VERSION "dbc-export 1 2026.26.6.5"

NS_ :

BS_:

BU_: ADSP APB APP APS APSB BB BMS CC CMP CMPD CP DAS DI DIF DIR DPB EPAS3P EPAS3S EPASTP EPASTS EPBL EPBR ESP EVSE FC GTW HCML HCMR HVP IBST ICR IDB LS OCS1P PARK PCS PCS2 PM PMF PMR PNCD PTC RADC RCM RCM2 RCM3 RCU SCCM SCM SCS SDCR TAS TCU TCU2 TPMS TRCM UI UIS UMC USM V2G VC VCBATT VCBATT0 VCBATT1 VCBATT2 VCCC VCFRONT VCFRONT1 VCFRONT2 VCLEFT VCRIGHT VCSEAT2L VCSEAT2R VCSEC VEH

BO_ 1328 VCSEC_alertLog: 8 VCSEC
 SG_ VCSEC_alertID M : 0|10@1+ (1,0) [0|1023] "" Vector__XXX
 SG_ VCSEC_alertState : 15|1@1+ (1,0) [0|1] "" Vector__XXX
 SG_ VCSEC_a001_InternalWatchdog m1 : 16|1@1+ (1,0) [0|1] "" Vector__XXX
 SG_ VCSEC_a010_UnderVoltageDetected m10 : 16|1@1+ (1,0) [0|1] "" Vector__XXX
 SG_ VCSEC_a010_UnderVoltageTimeout m10 : 17|1@1+ (1,0) [0|1] "" Vector__XXX
 SG_ VCSEC_a015_NVMMMemOverflow m15 : 16|1@1+ (1,0) [0|1] "" Vector__XXX
 SG_ VCSEC_a015_NVMMFilesystemError m15 : 17|1@1+ (1,0) [0|1] "" Vector__XXX
 SG_ VCSEC_a015_NVMMRecordIDError m15 : 18|1@1+ (1,0) [0|1] "" Vector__XXX
 SG_ VCSEC_a057_VEH_cpControl m57 : 16|1@1+ (1,0) [0|1] "" Vector__XXX
 SG_ VCSEC_a059_voltageDrop m59 : 16|12@1+ (0.005443676,0) [0|22.29185322] "" Vector__XXX
 SG_ VCSEC_a059_resistanceEstimate m59 : 28|12@1+ (0.00244,0) [0|9.9918] "" Vector__XXX
 SG_ VCSEC_a059_current m59 : 40|12@1+ (0.05,0) [0|204.75] "" Vector__XXX
 SG_ VCSEC_a063_switchChannel m63 : 16|8@1+ (1,0) [0|255] "" Vector__XXX
 SG_ VCSEC_a063_switchType m63 : 24|8@1+ (1,0) [0|255] "" Vector__XXX
 SG_ VCSEC_a063_ADCVoltage m63 : 32|8@1+ (0.025,0) [0|6.375] "" Vector__XXX
 SG_ VCSEC_a063_disconnected m63 : 40|1@1+ (1,0) [0|1] "" Vector__XXX
 SG_ VCSEC_a063_indeterminate m63 : 41|1@1+ (1,0) [0|1] "" Vector__XXX
 SG_ VCSEC_a063_stuckActive m63 : 42|1@1+ (1,0) [0|1] "" Vector__XXX
 SG_ VCSEC_a063_faulted m63 : 43|1@1+ (1,0) [0|1] "" Vector__XXX
 SG_ VCSEC_a082_RIPC_epbPrivateState m82 : 16|1@1+ (1,0) [0|1] "" Vector__XXX
 SG_ VCSEC_a082_RIPC_remoteHSD m82 : 17|1@1+ (1,0) [0|1] "" Vector__XXX
 SG_ VCSEC_a082_RIPC_railStatus m82 : 18|1@1+ (1,0) [0|1] "" Vector__XXX
 SG_ VCSEC_a082_RIPC_remoteMux m82 : 19|1@1+ (1,0) [0|1] "" Vector__XXX
 SG_ VCSEC_a083_LIPC_epbPrivateState m83 : 16|1@1+ (1,0) [0|1] "" Vector__XXX
 SG_ VCSEC_a083_LIPC_remoteHSD m83 : 17|1@1+ (1,0) [0|1] "" Vector__XXX
 SG_ VCSEC_a083_LIPC_railStatus m83 : 18|1@1+ (1,0) [0|1] "" Vector__XXX
 SG_ VCSEC_a083_LIPC_HSDFaults m83 : 19|1@1+ (1,0) [0|1] "" Vector__XXX
 SG_ VCSEC_a084_CH_StatusC m84 : 16|1@1+ (1,0) [0|1] "" Vector__XXX
 SG_ VCSEC_a085_PARTY_buttonStatus m85 : 16|1@1+ (1,0) [0|1] "" Vector__XXX
 SG_ VCSEC_a086_VEH_LVBMS_statusHigh m86 : 16|1@1+ (1,0) [0|1] "" Vector__XXX
 SG_ VCSEC_a086_VEH_LVBMS_statusLow m86 : 17|1@1+ (1,0) [0|1] "" Vector__XXX
 SG_ VCSEC_a086_VEH_status m86 : 18|1@1+ (1,0) [0|1] "" Vector__XXX
 SG_ VCSEC_a086_VEH_12VBatteryStatus m86 : 19|1@1+ (1,0) [0|1] "" Vector__XXX
 SG_ VCSEC_a086_VEH_LVPowerState m86 : 20|1@1+ (1,0) [0|1] "" Vector__XXX
 SG_ VCSEC_a086_VEH_lightStatus m86 : 21|1@1+ (1,0) [0|1] "" Vector__XXX
 SG_ VCSEC_a086_VEH_systemStatus m86 : 22|1@1+ (1,0) [0|1] "" Vector__XXX
 SG_ VCSEC_a086_VEH_thermalStatus m86 : 23|1@1+ (1,0) [0|1] "" Vector__XXX
 SG_ VCSEC_a086_VEH_vehNm m86 : 24|1@1+ (1,0) [0|1] "" Vector__XXX
 SG_ VCSEC_a087_VEH_temperature m87 : 16|1@1+ (1,0) [0|1] "" Vector__XXX
 SG_ VCSEC_a087_VEH_thermalControl m87 : 17|1@1+ (1,0) [0|1] "" Vector__XXX
 SG_ VCSEC_a087_VEH_torque m87 : 18|1@1+ (1,0) [0|1] "" Vector__XXX
 SG_ VCSEC_a087_VEH_status m87 : 19|1@1+ (1,0) [0|1] "" Vector__XXX
 SG_ VCSEC_a087_PARTY_torque m87 : 20|1@1+ (1,0) [0|1] "" Vector__XXX
 SG_ VCSEC_a087_PARTY_status m87 : 21|1@1+ (1,0) [0|1] "" Vector__XXX
 SG_ VCSEC_a087_PARTY_temperature m87 : 22|1@1+ (1,0) [0|1] "" Vector__XXX
 SG_ VCSEC_a087_PARTY_thermalControl m87 : 23|1@1+ (1,0) [0|1] "" Vector__XXX
 SG_ VCSEC_a087_VEH_motorStatus m87 : 24|1@1+ (1,0) [0|1] "" Vector__XXX
 SG_ VCSEC_a088_VEH_temperature m88 : 16|1@1+ (1,0) [0|1] "" Vector__XXX
 SG_ VCSEC_a088_VEH_thermalControl m88 : 17|1@1+ (1,0) [0|1] "" Vector__XXX
 SG_ VCSEC_a088_VEH_torque m88 : 18|1@1+ (1,0) [0|1] "" Vector__XXX
 SG_ VCSEC_a088_VEH_status m88 : 19|1@1+ (1,0) [0|1] "" Vector__XXX
 SG_ VCSEC_a088_PARTY_torque m88 : 20|1@1+ (1,0) [0|1] "" Vector__XXX
 SG_ VCSEC_a088_PARTY_status m88 : 21|1@1+ (1,0) [0|1] "" Vector__XXX
 SG_ VCSEC_a088_PARTY_temperature m88 : 22|1@1+ (1,0) [0|1] "" Vector__XXX
 SG_ VCSEC_a088_PARTY_thermalControl m88 : 23|1@1+ (1,0) [0|1] "" Vector__XXX
 SG_ VCSEC_a088_VEH_motorStatus m88 : 24|1@1+ (1,0) [0|1] "" Vector__XXX
 SG_ VCSEC_a089_PARTY_party1 m89 : 16|1@1+ (1,0) [0|1] "" Vector__XXX
 SG_ VCSEC_a089_PARTY_status m89 : 17|1@1+ (1,0) [0|1] "" Vector__XXX
 SG_ VCSEC_a089_VEH_status m89 : 18|1@1+ (1,0) [0|1] "" Vector__XXX
 SG_ VCSEC_a089_BDY_party1 m89 : 19|1@1+ (1,0) [0|1] "" Vector__XXX
 SG_ VCSEC_a089_BDY_status m89 : 20|1@1+ (1,0) [0|1] "" Vector__XXX
 SG_ VCSEC_a089_CH_status m89 : 21|1@1+ (1,0) [0|1] "" Vector__XXX
 SG_ VCSEC_a089_CH_party1 m89 : 22|1@1+ (1,0) [0|1] "" Vector__XXX
 SG_ VCSEC_a089_CH_party3 m89 : 23|1@1+ (1,0) [0|1] "" Vector__XXX
 SG_ VCSEC_a089_VEH_party1 m89 : 24|1@1+ (1,0) [0|1] "" Vector__XXX
 SG_ VCSEC_a089_VEH_party3 m89 : 25|1@1+ (1,0) [0|1] "" Vector__XXX
 SG_ VCSEC_a091_VEH_faultsAndExtras m91 : 16|1@1+ (1,0) [0|1] "" Vector__XXX
 SG_ VCSEC_a091_VEH_info m91 : 17|1@1+ (1,0) [0|1] "" Vector__XXX
 SG_ VCSEC_a091_VEH_state m91 : 18|1@1+ (1,0) [0|1] "" Vector__XXX
 SG_ VCSEC_a092_VEH_restraintStatus m92 : 16|1@1+ (1,0) [0|1] "" Vector__XXX
 SG_ VCSEC_a092_VEH_switchStatus m92 : 17|1@1+ (1,0) [0|1] "" Vector__XXX
 SG_ VCSEC_a092_VEH_seatStatus2 m92 : 18|1@1+ (1,0) [0|1] "" Vector__XXX
 SG_ VCSEC_a092_VEH_vehNm m92 : 19|1@1+ (1,0) [0|1] "" Vector__XXX
 SG_ VCSEC_a093_VEH_restraintStatus m93 : 16|1@1+ (1,0) [0|1] "" Vector__XXX
 SG_ VCSEC_a093_VEH_switchStatus m93 : 17|1@1+ (1,0) [0|1] "" Vector__XXX
 SG_ VCSEC_a093_VEH_seatStatus2 m93 : 18|1@1+ (1,0) [0|1] "" Vector__XXX
 SG_ VCSEC_a093_VEH_vehNm m93 : 19|1@1+ (1,0) [0|1] "" Vector__XXX
 SG_ VCSEC_a094_VEH_sysStatus m94 : 16|1@1+ (1,0) [0|1] "" Vector__XXX
 SG_ VCSEC_a094_PARTY_sysStatus m94 : 17|1@1+ (1,0) [0|1] "" Vector__XXX
 SG_ VCSEC_a094_CH_sysStatus m94 : 18|1@1+ (1,0) [0|1] "" Vector__XXX
 SG_ VCSEC_a095_PT_ptNm m95 : 16|1@1+ (1,0) [0|1] "" Vector__XXX
 SG_ VCSEC_a095_PT_status m95 : 17|1@1+ (1,0) [0|1] "" Vector__XXX
 SG_ VCSEC_a096_VEH_status m96 : 16|1@1+ (1,0) [0|1] "" Vector__XXX
 SG_ VCSEC_a096_CH_status m96 : 17|1@1+ (1,0) [0|1] "" Vector__XXX
 SG_ VCSEC_a097_VEH_HVStatus m97 : 16|1@1+ (1,0) [0|1] "" Vector__XXX
 SG_ VCSEC_a097_VEH_state m97 : 17|1@1+ (1,0) [0|1] "" Vector__XXX
 SG_ VCSEC_a098_CH_torque m98 : 16|1@1+ (1,0) [0|1] "" Vector__XXX
 SG_ VCSEC_a098_VEH_hvStatus m98 : 17|1@1+ (1,0) [0|1] "" Vector__XXX
 SG_ VCSEC_a098_VEH_status m98 : 18|1@1+ (1,0) [0|1] "" Vector__XXX
 SG_ VCSEC_a098_VEH_thermalControl m98 : 19|1@1+ (1,0) [0|1] "" Vector__XXX
 SG_ VCSEC_a098_VEH_temperature m98 : 20|1@1+ (1,0) [0|1] "" Vector__XXX
 SG_ VCSEC_a098_VEH_torque m98 : 21|1@1+ (1,0) [0|1] "" Vector__XXX
 SG_ VCSEC_a098_PARTY_status m98 : 22|1@1+ (1,0) [0|1] "" Vector__XXX
 SG_ VCSEC_a098_PARTY_temperature m98 : 23|1@1+ (1,0) [0|1] "" Vector__XXX
 SG_ VCSEC_a098_PARTY_thermalControl m98 : 24|1@1+ (1,0) [0|1] "" Vector__XXX
 SG_ VCSEC_a098_PARTY_torque m98 : 25|1@1+ (1,0) [0|1] "" Vector__XXX
 SG_ VCSEC_a098_PT_thermalControl m98 : 26|1@1+ (1,0) [0|1] "" Vector__XXX
 SG_ VCSEC_a098_PT_temperature m98 : 27|1@1+ (1,0) [0|1] "" Vector__XXX
 SG_ VCSEC_a098_PARTY_motorStatus m98 : 28|1@1+ (1,0) [0|1] "" Vector__XXX
 SG_ VCSEC_a098_VEH_motorStatus m98 : 29|1@1+ (1,0) [0|1] "" Vector__XXX
 SG_ VCSEC_a099_VEH_oocStatus m99 : 16|1@1+ (1,0) [0|1] "" Vector__XXX
 SG_ VCSEC_a100_VEH m100 : 16|1@1+ (1,0) [0|1] "" Vector__XXX
 SG_ VCSEC_a100_PARTY m100 : 17|1@1+ (1,0) [0|1] "" Vector__XXX
 SG_ VCSEC_a100_PT m100 : 18|1@1+ (1,0) [0|1] "" Vector__XXX
 SG_ VCSEC_a100_CH m100 : 19|1@1+ (1,0) [0|1] "" Vector__XXX
 SG_ VCSEC_a100_OBD m100 : 20|1@1+ (1,0) [0|1] "" Vector__XXX
 SG_ VCSEC_a101_VEH_state m101 : 16|1@1+ (1,0) [0|1] "" Vector__XXX
 SG_ VCSEC_a101_PARTY_locState m101 : 17|1@1+ (1,0) [0|1] "" Vector__XXX
 SG_ VCSEC_a101_LIPC_externalWatchdog m101 : 18|1@1+ (1,0) [0|1] "" Vector__XXX
 SG_ VCSEC_a101_VEH_locState m101 : 19|1@1+ (1,0) [0|1] "" Vector__XXX
 SG_ VCSEC_a101_BDY_locState m101 : 20|1@1+ (1,0) [0|1] "" Vector__XXX
 SG_ VCSEC_a102_VEH_faultsAndExtras m102 : 16|1@1+ (1,0) [0|1] "" Vector__XXX
 SG_ VCSEC_a102_VEH_feedbackStatus m102 : 17|1@1+ (1,0) [0|1] "" Vector__XXX
 SG_ VCSEC_a102_VEH_sensorStatus m102 : 18|1@1+ (1,0) [0|1] "" Vector__XXX
 SG_ VCSEC_a102_VEH_rods m102 : 19|1@1+ (1,0) [0|1] "" Vector__XXX
 SG_ VCSEC_a103_VEH_hvsNm m103 : 16|1@1+ (1,0) [0|1] "" Vector__XXX
 SG_ VCSEC_a103_VEH_vehNm m103 : 17|1@1+ (1,0) [0|1] "" Vector__XXX
 SG_ VCSEC_a103_VEH_status m103 : 18|1@1+ (1,0) [0|1] "" Vector__XXX
 SG_ VCSEC_a103_PT_ptNm m103 : 19|1@1+ (1,0) [0|1] "" Vector__XXX
 SG_ VCSEC_a103_PT_status m103 : 20|1@1+ (1,0) [0|1] "" Vector__XXX
 SG_ VCSEC_a103_VEH_evseStatus m103 : 21|1@1+ (1,0) [0|1] "" Vector__XXX
 SG_ VCSEC_a105_VEH_states m105 : 16|1@1+ (1,0) [0|1] "" Vector__XXX
 SG_ VCSEC_a105_VEH_chNm m105 : 17|1@1+ (1,0) [0|1] "" Vector__XXX
 SG_ VCSEC_a105_VEH_dampingStates m105 : 18|1@1+ (1,0) [0|1] "" Vector__XXX
 SG_ VCSEC_a106_VEH_dcdcStatus m106 : 16|1@1+ (1,0) [0|1] "" Vector__XXX
 SG_ VCSEC_a106_VEH_thermalControl m106 : 17|1@1+ (1,0) [0|1] "" Vector__XXX
 SG_ VCSEC_a106_VEH_dcdcRailStatus m106 : 18|1@1+ (1,0) [0|1] "" Vector__XXX
 SG_ VCSEC_a106_CH_dcdcRailStatus m106 : 19|1@1+ (1,0) [0|1] "" Vector__XXX
 SG_ VCSEC_a106_CH_alertMatrix m106 : 20|1@1+ (1,0) [0|1] "" Vector__XXX
 SG_ VCSEC_a107_VEH_hvsNm m107 : 16|1@1+ (1,0) [0|1] "" Vector__XXX
 SG_ VCSEC_a107_VEH_vehNm m107 : 17|1@1+ (1,0) [0|1] "" Vector__XXX
 SG_ VCSEC_a107_VEH_status m107 : 18|1@1+ (1,0) [0|1] "" Vector__XXX
 SG_ VCSEC_a107_VEH_thermalStatus m107 : 19|1@1+ (1,0) [0|1] "" Vector__XXX
 SG_ VCSEC_a107_VEH_bmbMinMax m107 : 20|1@1+ (1,0) [0|1] "" Vector__XXX
 SG_ VCSEC_a107_VEH_powerAvailable m107 : 21|1@1+ (1,0) [0|1] "" Vector__XXX
 SG_ VCSEC_a107_PT_ptNm m107 : 22|1@1+ (1,0) [0|1] "" Vector__XXX
 SG_ VCSEC_a107_PT_status m107 : 23|1@1+ (1,0) [0|1] "" Vector__XXX
 SG_ VCSEC_a107_PT_thermalStatus m107 : 24|1@1+ (1,0) [0|1] "" Vector__XXX
 SG_ VCSEC_a107_PT_socStatus m107 : 25|1@1+ (1,0) [0|1] "" Vector__XXX
 SG_ VCSEC_a107_VEH_socStatus m107 : 26|1@1+ (1,0) [0|1] "" Vector__XXX
 SG_ VCSEC_a107_VEH_packConfig m107 : 27|1@1+ (1,0) [0|1] "" Vector__XXX
 SG_ VCSEC_a107_VEH_energyStatus m107 : 28|1@1+ (1,0) [0|1] "" Vector__XXX
 SG_ VCSEC_a107_VEH_chargeInfo m107 : 29|1@1+ (1,0) [0|1] "" Vector__XXX
 SG_ VCSEC_a108_VEH_hvStatus m108 : 16|1@1+ (1,0) [0|1] "" Vector__XXX
 SG_ VCSEC_a108_VEH_temperature m108 : 17|1@1+ (1,0) [0|1] "" Vector__XXX
 SG_ VCSEC_a108_VEH_thermalControl m108 : 18|1@1+ (1,0) [0|1] "" Vector__XXX
 SG_ VCSEC_a108_VEH_torque m108 : 19|1@1+ (1,0) [0|1] "" Vector__XXX
 SG_ VCSEC_a108_VEH_status m108 : 20|1@1+ (1,0) [0|1] "" Vector__XXX
 SG_ VCSEC_a108_PARTY_torque m108 : 21|1@1+ (1,0) [0|1] "" Vector__XXX
 SG_ VCSEC_a108_PARTY_status m108 : 22|1@1+ (1,0) [0|1] "" Vector__XXX
 SG_ VCSEC_a108_PARTY_temperature m108 : 23|1@1+ (1,0) [0|1] "" Vector__XXX
 SG_ VCSEC_a108_PARTY_thermalControl m108 : 24|1@1+ (1,0) [0|1] "" Vector__XXX
 SG_ VCSEC_a108_PT_temperature m108 : 25|1@1+ (1,0) [0|1] "" Vector__XXX
 SG_ VCSEC_a108_PT_thermalControl m108 : 26|1@1+ (1,0) [0|1] "" Vector__XXX
 SG_ VCSEC_a108_PARTY_motorStatus m108 : 27|1@1+ (1,0) [0|1] "" Vector__XXX
 SG_ VCSEC_a108_VEH_motorStatus m108 : 28|1@1+ (1,0) [0|1] "" Vector__XXX
 SG_ VCSEC_a108_CH_torque m108 : 29|1@1+ (1,0) [0|1] "" Vector__XXX
 SG_ VCSEC_a110_VEH_carState m110 : 16|1@1+ (1,0) [0|1] "" Vector__XXX
 SG_ VCSEC_a110_VEH_carConfig m110 : 17|1@1+ (1,0) [0|1] "" Vector__XXX
 SG_ VCSEC_a110_VEH_time m110 : 18|1@1+ (1,0) [0|1] "" Vector__XXX
 SG_ VCSEC_a110_VEH_updateStatus m110 : 19|1@1+ (1,0) [0|1] "" Vector__XXX
 SG_ VCSEC_a110_VEH_vehNm m110 : 20|1@1+ (1,0) [0|1] "" Vector__XXX
 SG_ VCSEC_a110_VEH_mismatchFault m110 : 21|1@1+ (1,0) [0|1] "" Vector__XXX
 SG_ VCSEC_a110_VEH_vin m110 : 22|1@1+ (1,0) [0|1] "" Vector__XXX
 SG_ VCSEC_a110_VEH_bmpDebug m110 : 23|1@1+ (1,0) [0|1] "" Vector__XXX
 SG_ VCSEC_a110_VEH_gearControl m110 : 24|1@1+ (1,0) [0|1] "" Vector__XXX
 SG_ VCSEC_a110_VEH_canLogAvailabilit m110 : 25|1@1+ (1,0) [0|1] "" Vector__XXX
 SG_ VCSEC_a110_CH_airbagCutoffStatus m110 : 26|1@1+ (1,0) [0|1] "" Vector__XXX
 SG_ VCSEC_a110_CH_carConfig m110 : 27|1@1+ (1,0) [0|1] "" Vector__XXX
 SG_ VCSEC_a110_CH_carState m110 : 28|1@1+ (1,0) [0|1] "" Vector__XXX
 SG_ VCSEC_a110_CH_vin m110 : 29|1@1+ (1,0) [0|1] "" Vector__XXX
 SG_ VCSEC_a110_CH_chNm m110 : 30|1@1+ (1,0) [0|1] "" Vector__XXX
 SG_ VCSEC_a110_CH_epochTimeGtw m110 : 31|1@1+ (1,0) [0|1] "" Vector__XXX
 SG_ VCSEC_a110_PARTY_carConfig m110 : 32|1@1+ (1,0) [0|1] "" Vector__XXX
 SG_ VCSEC_a111_VEH_internalStatus m111 : 16|1@1+ (1,0) [0|1] "" Vector__XXX
 SG_ VCSEC_a111_VEH_status m111 : 17|1@1+ (1,0) [0|1] "" Vector__XXX
 SG_ VCSEC_a111_VEH_vehNm m111 : 18|1@1+ (1,0) [0|1] "" Vector__XXX
 SG_ VCSEC_a111_RIPC_LVPowerState m111 : 19|1@1+ (1,0) [0|1] "" Vector__XXX
 SG_ VCSEC_a111_RIPC_epbPrivateState m111 : 20|1@1+ (1,0) [0|1] "" Vector__XXX
 SG_ VCSEC_a111_RIPC_railStatus m111 : 21|1@1+ (1,0) [0|1] "" Vector__XXX
 SG_ VCSEC_a111_RIPC_remoteADC m111 : 22|1@1+ (1,0) [0|1] "" Vector__XXX
 SG_ VCSEC_a111_RIPC_switchStatus m111 : 23|1@1+ (1,0) [0|1] "" Vector__XXX
 SG_ VCSEC_a111_VEH_LVPowerState m111 : 24|1@1+ (1,0) [0|1] "" Vector__XXX
 SG_ VCSEC_a111_VEH_seatStatus m111 : 25|1@1+ (1,0) [0|1] "" Vector__XXX
 SG_ VCSEC_a111_PARTY_status m111 : 26|1@1+ (1,0) [0|1] "" Vector__XXX
 SG_ VCSEC_a111_CH_status m111 : 27|1@1+ (1,0) [0|1] "" Vector__XXX
 SG_ VCSEC_a112_VEH_internalStatus m112 : 16|1@1+ (1,0) [0|1] "" Vector__XXX
 SG_ VCSEC_a112_VEH_status m112 : 17|1@1+ (1,0) [0|1] "" Vector__XXX
 SG_ VCSEC_a112_VEH_vehNm m112 : 18|1@1+ (1,0) [0|1] "" Vector__XXX
 SG_ VCSEC_a112_LIPC_LVPowerState m112 : 19|1@1+ (1,0) [0|1] "" Vector__XXX
 SG_ VCSEC_a112_LIPC_epbPrivateState m112 : 20|1@1+ (1,0) [0|1] "" Vector__XXX
 SG_ VCSEC_a112_LIPC_railStatus m112 : 21|1@1+ (1,0) [0|1] "" Vector__XXX
 SG_ VCSEC_a112_LIPC_remoteADC m112 : 22|1@1+ (1,0) [0|1] "" Vector__XXX
 SG_ VCSEC_a112_LIPC_switchStatus m112 : 23|1@1+ (1,0) [0|1] "" Vector__XXX
 SG_ VCSEC_a112_VEH_LVPowerState m112 : 24|1@1+ (1,0) [0|1] "" Vector__XXX
 SG_ VCSEC_a112_PARTY_status m112 : 25|1@1+ (1,0) [0|1] "" Vector__XXX
 SG_ VCSEC_a112_CH_status m112 : 26|1@1+ (1,0) [0|1] "" Vector__XXX
 SG_ VCSEC_a114_PARTY_status m114 : 16|1@1+ (1,0) [0|1] "" Vector__XXX
 SG_ VCSEC_a114_PARTY_wheelSpeeds m114 : 17|1@1+ (1,0) [0|1] "" Vector__XXX
 SG_ VCSEC_a114_VEH_wheelSpeeds m114 : 18|1@1+ (1,0) [0|1] "" Vector__XXX
 SG_ VCSEC_a114_CH_wheelSpeeds m114 : 19|1@1+ (1,0) [0|1] "" Vector__XXX
 SG_ VCSEC_a114_PARTY_party3 m114 : 20|1@1+ (1,0) [0|1] "" Vector__XXX
 SG_ VCSEC_a114_VEH_party3 m114 : 21|1@1+ (1,0) [0|1] "" Vector__XXX
 SG_ VCSEC_a114_VEH_status m114 : 22|1@1+ (1,0) [0|1] "" Vector__XXX
 SG_ VCSEC_a114_PARTY_wheelRotation m114 : 23|1@1+ (1,0) [0|1] "" Vector__XXX
 SG_ VCSEC_a114_CH_wheelRotation m114 : 24|1@1+ (1,0) [0|1] "" Vector__XXX
 SG_ VCSEC_a114_VEH_wheelRotation m114 : 25|1@1+ (1,0) [0|1] "" Vector__XXX
 SG_ VCSEC_a114_PARTY_brakeTorque m114 : 26|1@1+ (1,0) [0|1] "" Vector__XXX
 SG_ VCSEC_a114_PARTY_offsets m114 : 27|1@1+ (1,0) [0|1] "" Vector__XXX
 SG_ VCSEC_a114_BDY_offsets m114 : 28|1@1+ (1,0) [0|1] "" Vector__XXX
 SG_ VCSEC_a114_BDY_party3 m114 : 29|1@1+ (1,0) [0|1] "" Vector__XXX
 SG_ VCSEC_a114_BDY_status m114 : 30|1@1+ (1,0) [0|1] "" Vector__XXX
 SG_ VCSEC_a114_BDY_wheelRotation m114 : 31|1@1+ (1,0) [0|1] "" Vector__XXX
 SG_ VCSEC_a114_BDY_wheelSpeeds m114 : 32|1@1+ (1,0) [0|1] "" Vector__XXX
 SG_ VCSEC_a114_CH_party1 m114 : 33|1@1+ (1,0) [0|1] "" Vector__XXX
 SG_ VCSEC_a114_CH_party3 m114 : 34|1@1+ (1,0) [0|1] "" Vector__XXX
 SG_ VCSEC_a114_CH_status m114 : 35|1@1+ (1,0) [0|1] "" Vector__XXX
 SG_ VCSEC_a115_VEH_vehNm m115 : 16|1@1+ (1,0) [0|1] "" Vector__XXX
 SG_ VCSEC_a115_VEH_authentication m115 : 17|1@1+ (1,0) [0|1] "" Vector__XXX
 SG_ VCSEC_a115_VEH_BLEResetRequest m115 : 18|1@1+ (1,0) [0|1] "" Vector__XXX
 SG_ VCSEC_a115_VEH_requests m115 : 19|1@1+ (1,0) [0|1] "" Vector__XXX
 SG_ VCSEC_a115_VEH_requests2 m115 : 20|1@1+ (1,0) [0|1] "" Vector__XXX
 SG_ VCSEC_a115_REM_authentication m115 : 21|1@1+ (1,0) [0|1] "" Vector__XXX
 SG_ VCSEC_a115_UI_corianderVehicleCo m115 : 22|1@1+ (1,0) [0|1] "" Vector__XXX
 SG_ VCSEC_a115_CH_TPMSDisplay m115 : 23|1@1+ (1,0) [0|1] "" Vector__XXX
 SG_ VCSEC_a116_PARTY_epbmStatus m116 : 16|1@1+ (1,0) [0|1] "" Vector__XXX
 SG_ VCSEC_a116_VEH_vehNm m116 : 17|1@1+ (1,0) [0|1] "" Vector__XXX
 SG_ VCSEC_a116_VEH_hvacRequest m116 : 18|1@1+ (1,0) [0|1] "" Vector__XXX
 SG_ VCSEC_a116_VEH_hvacStatus m116 : 19|1@1+ (1,0) [0|1] "" Vector__XXX
 SG_ VCSEC_a116_VEH_LVPowerState m116 : 20|1@1+ (1,0) [0|1] "" Vector__XXX
 SG_ VCSEC_a116_VEH_lightStatus m116 : 21|1@1+ (1,0) [0|1] "" Vector__XXX
 SG_ VCSEC_a116_VEH_seatStatus m116 : 22|1@1+ (1,0) [0|1] "" Vector__XXX
 SG_ VCSEC_a116_VEH_thsStatus m116 : 23|1@1+ (1,0) [0|1] "" Vector__XXX
 SG_ VCSEC_a116_VEH_doorStatus m116 : 24|1@1+ (1,0) [0|1] "" Vector__XXX
 SG_ VCSEC_a116_VEH_seatHeatStatus m116 : 25|1@1+ (1,0) [0|1] "" Vector__XXX
 SG_ VCSEC_a116_VEH_restraintStatus m116 : 26|1@1+ (1,0) [0|1] "" Vector__XXX
 SG_ VCSEC_a116_VEH_switchStatus m116 : 27|1@1+ (1,0) [0|1] "" Vector__XXX
 SG_ VCSEC_a116_VEH_logging1Hz m116 : 28|1@1+ (1,0) [0|1] "" Vector__XXX
 SG_ VCSEC_a116_VEH_seatStatus2 m116 : 29|1@1+ (1,0) [0|1] "" Vector__XXX
 SG_ VCSEC_a116_VEH_status m116 : 30|1@1+ (1,0) [0|1] "" Vector__XXX
 SG_ VCSEC_a116_VEH_thermalCommand m116 : 31|1@1+ (1,0) [0|1] "" Vector__XXX
 SG_ VCSEC_a116_VEH_windowStatus m116 : 32|1@1+ (1,0) [0|1] "" Vector__XXX
 SG_ VCSEC_a116_PARTY_restraintStatus m116 : 33|1@1+ (1,0) [0|1] "" Vector__XXX
 SG_ VCSEC_a116_PARTY_doorStatus m116 : 34|1@1+ (1,0) [0|1] "" Vector__XXX
 SG_ VCSEC_a116_BDY_epbmStatus m116 : 35|1@1+ (1,0) [0|1] "" Vector__XXX
 SG_ VCSEC_a116_BDY_restraintStatus m116 : 36|1@1+ (1,0) [0|1] "" Vector__XXX
 SG_ VCSEC_a116_BDY_switchStatus m116 : 37|1@1+ (1,0) [0|1] "" Vector__XXX
 SG_ VCSEC_a117_BDY_epbmStatus m117 : 16|1@1+ (1,0) [0|1] "" Vector__XXX
 SG_ VCSEC_a117_BDY_restraintStatus m117 : 17|1@1+ (1,0) [0|1] "" Vector__XXX
 SG_ VCSEC_a117_VEH_prndStatus m117 : 18|1@1+ (1,0) [0|1] "" Vector__XXX
 SG_ VCSEC_a117_PARTY_epbmStatus m117 : 19|1@1+ (1,0) [0|1] "" Vector__XXX
 SG_ VCSEC_a117_VEH_vehNm m117 : 20|1@1+ (1,0) [0|1] "" Vector__XXX
 SG_ VCSEC_a117_VEH_hvacBlowerFdb m117 : 21|1@1+ (1,0) [0|1] "" Vector__XXX
 SG_ VCSEC_a117_VEH_LVPowerState m117 : 22|1@1+ (1,0) [0|1] "" Vector__XXX
 SG_ VCSEC_a117_VEH_restraintStatus m117 : 23|1@1+ (1,0) [0|1] "" Vector__XXX
 SG_ VCSEC_a117_VEH_lightStatus m117 : 24|1@1+ (1,0) [0|1] "" Vector__XXX
 SG_ VCSEC_a117_VEH_seatStatus m117 : 25|1@1+ (1,0) [0|1] "" Vector__XXX
 SG_ VCSEC_a117_BDY_falconSwitchStatu m117 : 26|1@1+ (1,0) [0|1] "" Vector__XXX
 SG_ VCSEC_a117_VEH_doorStatus m117 : 27|1@1+ (1,0) [0|1] "" Vector__XXX
 SG_ VCSEC_a117_VEH_doorStatus2 m117 : 28|1@1+ (1,0) [0|1] "" Vector__XXX
 SG_ VCSEC_a117_VEH_windowStatus m117 : 29|1@1+ (1,0) [0|1] "" Vector__XXX
 SG_ VCSEC_a117_VEH_switchStatus m117 : 30|1@1+ (1,0) [0|1] "" Vector__XXX
 SG_ VCSEC_a117_VEH_intrusionSensorSt m117 : 31|1@1+ (1,0) [0|1] "" Vector__XXX
 SG_ VCSEC_a117_VEH_liftgateStatus m117 : 32|1@1+ (1,0) [0|1] "" Vector__XXX
 SG_ VCSEC_a117_VEH_seatStatus2 m117 : 33|1@1+ (1,0) [0|1] "" Vector__XXX
 SG_ VCSEC_a117_PARTY_restraintStatus m117 : 34|1@1+ (1,0) [0|1] "" Vector__XXX
 SG_ VCSEC_a117_VEH_thermalStatus m117 : 35|1@1+ (1,0) [0|1] "" Vector__XXX
 SG_ VCSEC_a117_PARTY_doorStatus m117 : 36|1@1+ (1,0) [0|1] "" Vector__XXX
 SG_ VCSEC_a117_VEH_status m117 : 37|1@1+ (1,0) [0|1] "" Vector__XXX
 SG_ VCSEC_a117_PARTY_prndStatus m117 : 38|1@1+ (1,0) [0|1] "" Vector__XXX
 SG_ VCSEC_a117_PARTY_lightingSeconda m117 : 39|1@1+ (1,0) [0|1] "" Vector__XXX
 SG_ VCSEC_a118_VEH_vehNm m118 : 16|1@1+ (1,0) [0|1] "" Vector__XXX
 SG_ VCSEC_a118_VEH_lighting m118 : 17|1@1+ (1,0) [0|1] "" Vector__XXX
 SG_ VCSEC_a118_VEH_sensors m118 : 18|1@1+ (1,0) [0|1] "" Vector__XXX
 SG_ VCSEC_a118_VEH_status m118 : 19|1@1+ (1,0) [0|1] "" Vector__XXX
 SG_ VCSEC_a118_VEH_okToUseHighPwr m118 : 20|1@1+ (1,0) [0|1] "" Vector__XXX
 SG_ VCSEC_a118_VEH_LVPowerState m118 : 21|1@1+ (1,0) [0|1] "" Vector__XXX
 SG_ VCSEC_a118_VEH_coolant m118 : 22|1@1+ (1,0) [0|1] "" Vector__XXX
 SG_ VCSEC_a118_VEH_vehicleStatus m118 : 23|1@1+ (1,0) [0|1] "" Vector__XXX
 SG_ VCSEC_a118_VEH_12VBatteryStatus m118 : 24|1@1+ (1,0) [0|1] "" Vector__XXX
 SG_ VCSEC_a118_VEH_systemStatus m118 : 25|1@1+ (1,0) [0|1] "" Vector__XXX
 SG_ VCSEC_a118_PARTY_LVPowerState m118 : 26|1@1+ (1,0) [0|1] "" Vector__XXX
 SG_ VCSEC_a118_PARTY_outputPowerStat m118 : 27|1@1+ (1,0) [0|1] "" Vector__XXX
 SG_ VCSEC_a118_PARTY_vehicleTime m118 : 28|1@1+ (1,0) [0|1] "" Vector__XXX
 SG_ VCSEC_a118_VEH_thermalCommand m118 : 29|1@1+ (1,0) [0|1] "" Vector__XXX
 SG_ VCSEC_a118_CH_LVPowerState m118 : 30|1@1+ (1,0) [0|1] "" Vector__XXX
 SG_ VCSEC_a118_PARTY_sensors m118 : 31|1@1+ (1,0) [0|1] "" Vector__XXX
 SG_ VCSEC_a118_CH_sensors m118 : 32|1@1+ (1,0) [0|1] "" Vector__XXX
 SG_ VCSEC_a118_VEH_interNodeResistan m118 : 33|1@1+ (1,0) [0|1] "" Vector__XXX
 SG_ VCSEC_a118_CH_lighting m118 : 34|1@1+ (1,0) [0|1] "" Vector__XXX
 SG_ VCSEC_a118_VEH_lightStatus m118 : 35|1@1+ (1,0) [0|1] "" Vector__XXX
 SG_ VCSEC_a118_PARTY_vehNm m118 : 36|1@1+ (1,0) [0|1] "" Vector__XXX
 SG_ VCSEC_a118_CH_12VBatteryStatus m118 : 37|1@1+ (1,0) [0|1] "" Vector__XXX
 SG_ VCSEC_a118_CH_LVBMS_statusHigh m118 : 38|1@1+ (1,0) [0|1] "" Vector__XXX
 SG_ VCSEC_a118_CH_alertMatrix m118 : 39|1@1+ (1,0) [0|1] "" Vector__XXX
 SG_ VCSEC_a118_BDY_outputPowerStatus m118 : 40|1@1+ (1,0) [0|1] "" Vector__XXX
 SG_ VCSEC_a118_BDY_vehicleTime m118 : 41|1@1+ (1,0) [0|1] "" Vector__XXX
 SG_ VCSEC_a118_PARTY_AP_vehicleState m118 : 42|1@1+ (1,0) [0|1] "" Vector__XXX
 SG_ VCSEC_a118_BDY_AP_vehicleState1H m118 : 43|1@1+ (1,0) [0|1] "" Vector__XXX
 SG_ VCSEC_a118_PARTY_VCFRONT_cameraC m118 : 44|1@1+ (1,0) [0|1] "" Vector__XXX
 SG_ VCSEC_a119_VEH_steerAngle m119 : 16|1@1+ (1,0) [0|1] "" Vector__XXX
 SG_ VCSEC_a119_VEH_leftStalk m119 : 17|1@1+ (1,0) [0|1] "" Vector__XXX
 SG_ VCSEC_a119_VEH_rightStalk m119 : 18|1@1+ (1,0) [0|1] "" Vector__XXX
 SG_ VCSEC_a119_PARTY_rightStalk m119 : 19|1@1+ (1,0) [0|1] "" Vector__XXX
 SG_ VCSEC_a119_CH_steerAngle m119 : 20|1@1+ (1,0) [0|1] "" Vector__XXX
 SG_ VCSEC_a119_PARTY_steerAngle m119 : 21|1@1+ (1,0) [0|1] "" Vector__XXX
 SG_ VCSEC_a120_PARTY_chassisCntl m120 : 16|1@1+ (1,0) [0|1] "" Vector__XXX
 SG_ VCSEC_a120_VEH_systemStatus m120 : 17|1@1+ (1,0) [0|1] "" Vector__XXX
 SG_ VCSEC_a120_CH_chassisCntl m120 : 18|1@1+ (1,0) [0|1] "" Vector__XXX
 SG_ VCSEC_a120_PARTY_systemStatus m120 : 19|1@1+ (1,0) [0|1] "" Vector__XXX
 SG_ VCSEC_a120_PARTY_torque m120 : 20|1@1+ (1,0) [0|1] "" Vector__XXX
 SG_ VCSEC_a120_VEH_torque m120 : 21|1@1+ (1,0) [0|1] "" Vector__XXX
 SG_ VCSEC_a120_PARTY_locStatus m120 : 22|1@1+ (1,0) [0|1] "" Vector__XXX
 SG_ VCSEC_a120_PARTY_speed m120 : 23|1@1+ (1,0) [0|1] "" Vector__XXX
 SG_ VCSEC_a120_VEH_speed m120 : 24|1@1+ (1,0) [0|1] "" Vector__XXX
 SG_ VCSEC_a120_PARTY_status m120 : 25|1@1+ (1,0) [0|1] "" Vector__XXX
 SG_ VCSEC_a120_PT_speed m120 : 26|1@1+ (1,0) [0|1] "" Vector__XXX
 SG_ VCSEC_a120_PT_systemStatus m120 : 27|1@1+ (1,0) [0|1] "" Vector__XXX
 SG_ VCSEC_a120_PARTY_vehicleEstimate m120 : 28|1@1+ (1,0) [0|1] "" Vector__XXX
 SG_ VCSEC_a120_VEH_aggregatedAxleSpe m120 : 29|1@1+ (1,0) [0|1] "" Vector__XXX
 SG_ VCSEC_a120_PARTY_aggregatedAxleS m120 : 30|1@1+ (1,0) [0|1] "" Vector__XXX
 SG_ VCSEC_a120_VEH_systemPower m120 : 31|1@1+ (1,0) [0|1] "" Vector__XXX
 SG_ VCSEC_a120_PARTY_autonomyHealth m120 : 32|1@1+ (1,0) [0|1] "" Vector__XXX
 SG_ VCSEC_a120_VEH_autonomyHealth m120 : 33|1@1+ (1,0) [0|1] "" Vector__XXX
 SG_ VCSEC_a120_PT_systemPower m120 : 34|1@1+ (1,0) [0|1] "" Vector__XXX
 SG_ VCSEC_a120_PARTY_stalklessInterf m120 : 35|1@1+ (1,0) [0|1] "" Vector__XXX
 SG_ VCSEC_a120_CH_speed m120 : 36|1@1+ (1,0) [0|1] "" Vector__XXX
 SG_ VCSEC_a120_VEH_estimatedBrakeTem m120 : 37|1@1+ (1,0) [0|1] "" Vector__XXX
 SG_ VCSEC_a120_PARTY_prndControl m120 : 38|1@1+ (1,0) [0|1] "" Vector__XXX
 SG_ VCSEC_a120_PARTY_locStatus2 m120 : 39|1@1+ (1,0) [0|1] "" Vector__XXX
 SG_ VCSEC_a120_VEH_chassisCntl m120 : 40|1@1+ (1,0) [0|1] "" Vector__XXX
 SG_ VCSEC_a120_CH_locStatus2 m120 : 41|1@1+ (1,0) [0|1] "" Vector__XXX
 SG_ VCSEC_a120_VEH_locStatus m120 : 42|1@1+ (1,0) [0|1] "" Vector__XXX
 SG_ VCSEC_a120_VEH_locStatus2 m120 : 43|1@1+ (1,0) [0|1] "" Vector__XXX
 SG_ VCSEC_a120_VEH_prndControl m120 : 44|1@1+ (1,0) [0|1] "" Vector__XXX
 SG_ VCSEC_a120_VEH_vehicleEstimates m120 : 45|1@1+ (1,0) [0|1] "" Vector__XXX
 SG_ VCSEC_a120_PARTY_motorStatus m120 : 46|1@1+ (1,0) [0|1] "" Vector__XXX
 SG_ VCSEC_a120_VEH_motorStatus m120 : 47|1@1+ (1,0) [0|1] "" Vector__XXX
 SG_ VCSEC_a120_BDY_speed m120 : 48|1@1+ (1,0) [0|1] "" Vector__XXX
 SG_ VCSEC_a121_VEH_status m121 : 16|1@1+ (1,0) [0|1] "" Vector__XXX
 SG_ VCSEC_a121_VEH_occupancy m121 : 17|1@1+ (1,0) [0|1] "" Vector__XXX
 SG_ VCSEC_a133_alarmTriggerReason m133 : 16|4@1+ (1,0) [0|15] "" Vector__XXX
 SG_ VCSEC_a140_keyDidNotIdentify m140 : 16|1@1+ (1,0) [0|1] "" Vector__XXX
 SG_ VCSEC_a140_keyNotPairedToTheCar m140 : 17|1@1+ (1,0) [0|1] "" Vector__XXX
 SG_ VCSEC_a140_authenticationFailed m140 : 18|1@1+ (1,0) [0|1] "" Vector__XXX
 SG_ VCSEC_a140_authenticationTimeout m140 : 19|1@1+ (1,0) [0|1] "" Vector__XXX
 SG_ VCSEC_a140_cardRmvdB4AuthComplet m140 : 20|1@1+ (1,0) [0|1] "" Vector__XXX
 SG_ VCSEC_a140_cardRmvdB4SndingChaln m140 : 21|1@1+ (1,0) [0|1] "" Vector__XXX
 SG_ VCSEC_a140_cardRmvdB4SndingReqID m140 : 22|1@1+ (1,0) [0|1] "" Vector__XXX
 SG_ VCSEC_a140_cardRmvdB4RecvingID m140 : 23|1@1+ (1,0) [0|1] "" Vector__XXX
 SG_ VCSEC_a140_multipleTriesToAuth m140 : 24|1@1+ (1,0) [0|1] "" Vector__XXX
 SG_ VCSEC_a177_newWhitelistSlot m177 : 16|5@1+ (1,0) [0|31] "" Vector__XXX
 SG_ VCSEC_a177_signingKeySlot m177 : 21|5@1+ (1,0) [0|31] "" Vector__XXX
 SG_ VCSEC_a177_newKeyPublicKey m177 : 26|20@1+ (1,0) [0|1048575] "" Vector__XXX
 SG_ VCSEC_a177_keyActiveTime m177 : 46|12@1+ (1,0) [0|4095] "" Vector__XXX
 SG_ VCSEC_a177_keyRole m177 : 58|4@1+ (1,0) [0|15] "" Vector__XXX
 SG_ VCSEC_a178_publicKey m178 : 16|32@1+ (1,0) [0|4294967295] "" Vector__XXX
 SG_ VCSEC_a178_signingKeySlot m178 : 48|5@1+ (1,0) [0|31] "" Vector__XXX
 SG_ VCSEC_a178_removedKeySlot m178 : 53|5@1+ (1,0) [0|31] "" Vector__XXX
 SG_ VCSEC_a178_removedKeyRole m178 : 58|4@1+ (1,0) [0|15] "" Vector__XXX
 SG_ VCSEC_a191_clearWlist m191 : 16|1@1+ (1,0) [0|1] "" Vector__XXX
 SG_ VCSEC_a191_WlistingDevice m191 : 17|1@1+ (1,0) [0|1] "" Vector__XXX
 SG_ VCSEC_a191_failedToSendWlist m191 : 18|1@1+ (1,0) [0|1] "" Vector__XXX
 SG_ VCSEC_a192_clearWlist m192 : 16|1@1+ (1,0) [0|1] "" Vector__XXX
 SG_ VCSEC_a192_WlistingDevice m192 : 17|1@1+ (1,0) [0|1] "" Vector__XXX
 SG_ VCSEC_a192_failedToSendWlist m192 : 18|1@1+ (1,0) [0|1] "" Vector__XXX
 SG_ VCSEC_a193_clearWlist m193 : 16|1@1+ (1,0) [0|1] "" Vector__XXX
 SG_ VCSEC_a193_WlistingDevice m193 : 17|1@1+ (1,0) [0|1] "" Vector__XXX
 SG_ VCSEC_a193_failedToSendWlist m193 : 18|1@1+ (1,0) [0|1] "" Vector__XXX
 SG_ VCSEC_a194_clearWlist m194 : 16|1@1+ (1,0) [0|1] "" Vector__XXX
 SG_ VCSEC_a194_WlistingDevice m194 : 17|1@1+ (1,0) [0|1] "" Vector__XXX
 SG_ VCSEC_a194_failedToSendWlist m194 : 18|1@1+ (1,0) [0|1] "" Vector__XXX
 SG_ VCSEC_a197_connectionChannel m197 : 16|4@1+ (1,0) [0|15] "" Vector__XXX
 SG_ VCSEC_a197_connHandleMismatch m197 : 20|1@1+ (1,0) [0|1] "" Vector__XXX
 SG_ VCSEC_a197_confrmtnTimeout m197 : 21|1@1+ (1,0) [0|1] "" Vector__XXX
 SG_ VCSEC_a197_errorInconfrmtn m197 : 24|8@1+ (1,0) [0|255] "" Vector__XXX
 SG_ VCSEC_a210_whiteListChannel m210 : 16|5@1+ (1,0) [0|31] "" Vector__XXX
 SG_ VCSEC_a211_handlePulled m211 : 16|4@1+ (1,0) [0|15] "" Vector__XXX
 SG_ VCSEC_a211_connectionCount m211 : 20|2@1+ (1,0) [0|3] "" Vector__XXX
 SG_ VCSEC_a211_RSSIValidMatrix m211 : 22|24@1+ (1,0) [0|16777215] "" Vector__XXX
 SG_ VCSEC_a211_DevicePresentCount m211 : 46|2@1+ (1,0) [0|3] "" Vector__XXX
 SG_ VCSEC_a211_UnknownDevicePresent m211 : 48|1@1+ (1,0) [0|1] "" Vector__XXX
 SG_ VCSEC_a211_AuthRequested m211 : 49|1@1+ (1,0) [0|1] "" Vector__XXX
 SG_ VCSEC_a211_MaximumRSSI m211 : 50|8@1- (1,0) [-128|127] "" Vector__XXX
 SG_ VCSEC_a211_MaximumRSSIAntenna m211 : 58|4@1+ (1,0) [0|15] "" Vector__XXX
 SG_ VCSEC_a211_riderKeyConnected m211 : 62|1@1+ (1,0) [0|1] "" Vector__XXX
 SG_ VCSEC_a211_FleetModeActive m211 : 63|1@1+ (1,0) [0|1] "" Vector__XXX
 SG_ VCSEC_a219_pairingRemovedSensor0 m219 : 16|1@1+ (1,0) [0|1] "" Vector__XXX
 SG_ VCSEC_a219_pairingRemovedSensor1 m219 : 17|1@1+ (1,0) [0|1] "" Vector__XXX
 SG_ VCSEC_a219_pairingRemovedSensor2 m219 : 18|1@1+ (1,0) [0|1] "" Vector__XXX
 SG_ VCSEC_a219_pairingRemovedSensor3 m219 : 19|1@1+ (1,0) [0|1] "" Vector__XXX
 SG_ VCSEC_a221_countryCode m221 : 16|16@1+ (1,0) [0|65535] "" Vector__XXX
 SG_ VCSEC_a221_homologationRegion m221 : 32|2@1+ (1,0) [0|3] "" Vector__XXX
 SG_ VCSEC_a256_whitelistOperation m256 : 16|4@1+ (1,0) [0|15] "" Vector__XXX
 SG_ VCSEC_a256_failureReason m256 : 24|6@1+ (1,0) [0|63] "" Vector__XXX
 SG_ VCSEC_a256_whitelistSlot m256 : 32|5@1+ (1,0) [0|31] "" Vector__XXX
 SG_ VCSEC_a256_signingKeySlot m256 : 40|5@1+ (1,0) [0|31] "" Vector__XXX
 SG_ VCSEC_a256_keyActiveTime m256 : 45|18@1+ (1,0) [0|262143] "" Vector__XXX
 SG_ VCSEC_a257_whitelistSlot m257 : 16|5@1+ (1,0) [0|31] "" Vector__XXX
 SG_ VCSEC_a257_keyID m257 : 24|24@1+ (1,0) [0|16777215] "" Vector__XXX
 SG_ VCSEC_a257_keyActiveTime m257 : 48|8@1+ (1,0) [0|255] "" Vector__XXX
 SG_ VCSEC_a257_permissionActiveTime m257 : 56|8@1+ (1,0) [0|255] "" Vector__XXX
 SG_ VCSEC_a266_pressure m266 : 16|8@1+ (0.025,0) [0|6.375] "" Vector__XXX
 SG_ VCSEC_a267_pressure m267 : 16|8@1+ (0.025,0) [0|6.375] "" Vector__XXX
 SG_ VCSEC_a268_pressure m268 : 16|8@1+ (0.025,0) [0|6.375] "" Vector__XXX
 SG_ VCSEC_a269_pressure m269 : 16|8@1+ (0.025,0) [0|6.375] "" Vector__XXX
 SG_ VCSEC_a270_pressure m270 : 16|8@1+ (0.025,0) [0|6.375] "" Vector__XXX
 SG_ VCSEC_a271_pressure m271 : 16|8@1+ (0.025,0) [0|6.375] "" Vector__XXX
 SG_ VCSEC_a272_pressure m272 : 16|8@1+ (0.025,0) [0|6.375] "" Vector__XXX
 SG_ VCSEC_a273_pressure m273 : 16|8@1+ (0.025,0) [0|6.375] "" Vector__XXX
 SG_ VCSEC_a311_whitelistChannel m311 : 16|5@1+ (1,0) [0|31] "" Vector__XXX
 SG_ VCSEC_a436_currentUHFHardware m436 : 16|8@1+ (1,0) [0|255] "" Vector__XXX
 SG_ VCSEC_a436_expectedUHFHardware m436 : 24|8@1+ (1,0) [0|255] "" Vector__XXX
 SG_ VCSEC_a436_countryCode m436 : 32|16@1+ (1,0) [0|65535] "" Vector__XXX
 SG_ VCSEC_a455_pressure m455 : 16|8@1+ (0.025,0) [0|6.375] "" Vector__XXX
 SG_ VCSEC_a456_pressure m456 : 16|8@1+ (0.025,0) [0|6.375] "" Vector__XXX
 SG_ VCSEC_a457_pressure m457 : 16|8@1+ (0.025,0) [0|6.375] "" Vector__XXX
 SG_ VCSEC_a458_pressure m458 : 16|8@1+ (0.025,0) [0|6.375] "" Vector__XXX
 SG_ VCSEC_a497_centerEndpointMismatc m497 : 16|1@1+ (1,0) [0|1] "" Vector__XXX
 SG_ VCSEC_a497_cradleEndpointMismatc m497 : 17|1@1+ (1,0) [0|1] "" Vector__XXX
 SG_ VCSEC_a497_leftEndpointMismatch m497 : 18|1@1+ (1,0) [0|1] "" Vector__XXX
 SG_ VCSEC_a497_rightEndpointMismatch m497 : 19|1@1+ (1,0) [0|1] "" Vector__XXX
 SG_ VCSEC_a497_rearLeftEndpointMisma m497 : 20|1@1+ (1,0) [0|1] "" Vector__XXX
 SG_ VCSEC_a497_rearRightEndpointMism m497 : 21|1@1+ (1,0) [0|1] "" Vector__XXX
 SG_ VCSEC_a497_endpointLocationToFix m497 : 24|4@1+ (1,0) [0|15] "" Vector__XXX
 SG_ VCSEC_a497_endpointExpectedPcbaI m497 : 32|8@1+ (1,0) [0|255] "" Vector__XXX
 SG_ VCSEC_a497_endpointExpectedAssem m497 : 40|4@1+ (1,0) [0|15] "" Vector__XXX
 SG_ VCSEC_a497_endpointExpectedUsage m497 : 44|4@1+ (1,0) [0|15] "" Vector__XXX
 SG_ VCSEC_a497_endpointActualPcbaId m497 : 48|8@1+ (1,0) [0|255] "" Vector__XXX
 SG_ VCSEC_a497_endpointActualAssembl m497 : 56|4@1+ (1,0) [0|15] "" Vector__XXX
 SG_ VCSEC_a497_endpointActualUsageId m497 : 60|4@1+ (1,0) [0|15] "" Vector__XXX
 SG_ VCSEC_a504_ecuUnprovisioned m504 : 16|1@1+ (1,0) [0|1] "" Vector__XXX
 SG_ VCSEC_a505_excessiveMacFailures m505 : 16|1@1+ (1,0) [0|1] "" Vector__XXX
 SG_ VCSEC_a517_pressure m517 : 16|9@1+ (0.025,0) [0|12.775] "" Vector__XXX
 SG_ VCSEC_a518_pressure m518 : 16|9@1+ (0.025,0) [0|12.775] "" Vector__XXX
 SG_ VCSEC_a519_pressure m519 : 16|9@1+ (0.025,0) [0|12.775] "" Vector__XXX
 SG_ VCSEC_a520_pressure m520 : 16|9@1+ (0.025,0) [0|12.775] "" Vector__XXX

BO_ 1017 VCSEC_alertMatrix: 8 VCSEC
 SG_ VCSEC_matrixIndex M : 0|4@1+ (1,0) [0|15] "" Vector__XXX
 SG_ VCSEC_a001_WatchdogReset m0 : 4|1@1+ (1,0) [0|1] "" Vector__XXX
 SG_ VCSEC_a002_PowerLossReset m0 : 5|1@1+ (1,0) [0|1] "" Vector__XXX
 SG_ VCSEC_a003_SWAssertion m0 : 6|1@1+ (1,0) [0|1] "" Vector__XXX
 SG_ VCSEC_a005_CANTXError m0 : 8|1@1+ (1,0) [0|1] "" Vector__XXX
 SG_ VCSEC_a006_CANTX_cyclicError m0 : 9|1@1+ (1,0) [0|1] "" Vector__XXX
 SG_ VCSEC_a010_ExtSupplyVoltError m0 : 13|1@1+ (1,0) [0|1] "" Vector__XXX
 SG_ VCSEC_a012_CPUReset m0 : 15|1@1+ (1,0) [0|1] "" Vector__XXX
 SG_ VCSEC_a013_AlertManagerFault m0 : 16|1@1+ (1,0) [0|1] "" Vector__XXX
 SG_ VCSEC_a015_NVMMError m0 : 18|1@1+ (1,0) [0|1] "" Vector__XXX
 SG_ VCSEC_a016_NVMMRecordError m0 : 19|1@1+ (1,0) [0|1] "" Vector__XXX
 SG_ VCSEC_a017_NVMMStatusDbg m0 : 20|1@1+ (1,0) [0|1] "" Vector__XXX
 SG_ VCSEC_a021_TaskSchedulerError m0 : 24|1@1+ (1,0) [0|1] "" Vector__XXX
 SG_ VCSEC_a022_TaskInitError m0 : 25|1@1+ (1,0) [0|1] "" Vector__XXX
 SG_ VCSEC_a029_CoreDump m0 : 32|1@1+ (1,0) [0|1] "" Vector__XXX
 SG_ VCSEC_a030_ECULogUploadRequest m0 : 33|1@1+ (1,0) [0|1] "" Vector__XXX
 SG_ VCSEC_a031_UDSActive m0 : 34|1@1+ (1,0) [0|1] "" Vector__XXX
 SG_ VCSEC_a041_HighCPULoad m0 : 44|1@1+ (1,0) [0|1] "" Vector__XXX
 SG_ VCSEC_a042_HighStackUsage m0 : 45|1@1+ (1,0) [0|1] "" Vector__XXX
 SG_ VCSEC_a043_Task1msError m0 : 46|1@1+ (1,0) [0|1] "" Vector__XXX
 SG_ VCSEC_a044_Task10msError m0 : 47|1@1+ (1,0) [0|1] "" Vector__XXX
 SG_ VCSEC_a045_Task100msError m0 : 48|1@1+ (1,0) [0|1] "" Vector__XXX
 SG_ VCSEC_a046_Task1000msError m0 : 49|1@1+ (1,0) [0|1] "" Vector__XXX
 SG_ VCSEC_a057_HVP_MIA m0 : 60|1@1+ (1,0) [0|1] "" Vector__XXX
 SG_ VCSEC_a058_inputRHighSyncDebug m0 : 61|1@1+ (1,0) [0|1] "" Vector__XXX
 SG_ VCSEC_a059_inputResistanceHigh m0 : 62|1@1+ (1,0) [0|1] "" Vector__XXX
 SG_ VCSEC_a060_engineeringBuild m0 : 63|1@1+ (1,0) [0|1] "" Vector__XXX
 SG_ VCSEC_a061_XCPConnected m1 : 4|1@1+ (1,0) [0|1] "" Vector__XXX
 SG_ VCSEC_a062_XCPWasConnected m1 : 5|1@1+ (1,0) [0|1] "" Vector__XXX
 SG_ VCSEC_a063_SwitchFault m1 : 6|1@1+ (1,0) [0|1] "" Vector__XXX
 SG_ VCSEC_a064_busSleepReqTimeout m1 : 7|1@1+ (1,0) [0|1] "" Vector__XXX
 SG_ VCSEC_a082_VCRIGHT_IPC_MIA m1 : 25|1@1+ (1,0) [0|1] "" Vector__XXX
 SG_ VCSEC_a083_VCLEFT_IPC_MIA m1 : 26|1@1+ (1,0) [0|1] "" Vector__XXX
 SG_ VCSEC_a084_TPMS_MIA m1 : 27|1@1+ (1,0) [0|1] "" Vector__XXX
 SG_ VCSEC_a085_CCCM_MIA m1 : 28|1@1+ (1,0) [0|1] "" Vector__XXX
 SG_ VCSEC_a086_VCBATT_MIA m1 : 29|1@1+ (1,0) [0|1] "" Vector__XXX
 SG_ VCSEC_a087_DIREL_MIA m1 : 30|1@1+ (1,0) [0|1] "" Vector__XXX
 SG_ VCSEC_a088_DIRER_MIA m1 : 31|1@1+ (1,0) [0|1] "" Vector__XXX
 SG_ VCSEC_a089_IBST_MIA m1 : 32|1@1+ (1,0) [0|1] "" Vector__XXX
 SG_ VCSEC_a090_APS_MIA m1 : 33|1@1+ (1,0) [0|1] "" Vector__XXX
 SG_ VCSEC_a091_CMPD_MIA m1 : 34|1@1+ (1,0) [0|1] "" Vector__XXX
 SG_ VCSEC_a092_VCSEATD_MIA m1 : 35|1@1+ (1,0) [0|1] "" Vector__XXX
 SG_ VCSEC_a093_VCSEATP_MIA m1 : 36|1@1+ (1,0) [0|1] "" Vector__XXX
 SG_ VCSEC_a094_EPAS3P_MIA m1 : 37|1@1+ (1,0) [0|1] "" Vector__XXX
 SG_ VCSEC_a095_CHG_MIA m1 : 38|1@1+ (1,0) [0|1] "" Vector__XXX
 SG_ VCSEC_a096_OCS1P_MIA m1 : 39|1@1+ (1,0) [0|1] "" Vector__XXX
 SG_ VCSEC_a097_CMP_MIA m1 : 40|1@1+ (1,0) [0|1] "" Vector__XXX
 SG_ VCSEC_a098_DIR_MIA m1 : 41|1@1+ (1,0) [0|1] "" Vector__XXX
 SG_ VCSEC_a099_PARK_MIA m1 : 42|1@1+ (1,0) [0|1] "" Vector__XXX
 SG_ VCSEC_a100_CANbus_MIA m1 : 43|1@1+ (1,0) [0|1] "" Vector__XXX
 SG_ VCSEC_a101_PM_MIA m1 : 44|1@1+ (1,0) [0|1] "" Vector__XXX
 SG_ VCSEC_a102_PTC_MIA m1 : 45|1@1+ (1,0) [0|1] "" Vector__XXX
 SG_ VCSEC_a103_CP_MIA m1 : 46|1@1+ (1,0) [0|1] "" Vector__XXX
 SG_ VCSEC_a104_DAS_MIA m1 : 47|1@1+ (1,0) [0|1] "" Vector__XXX
 SG_ VCSEC_a105_TAS_MIA m1 : 48|1@1+ (1,0) [0|1] "" Vector__XXX
 SG_ VCSEC_a106_PCS_MIA m1 : 49|1@1+ (1,0) [0|1] "" Vector__XXX
 SG_ VCSEC_a107_BMS_MIA m1 : 50|1@1+ (1,0) [0|1] "" Vector__XXX
 SG_ VCSEC_a108_DIF_MIA m1 : 51|1@1+ (1,0) [0|1] "" Vector__XXX
 SG_ VCSEC_a109_RCM_MIA m1 : 52|1@1+ (1,0) [0|1] "" Vector__XXX
 SG_ VCSEC_a110_GTW_MIA m1 : 53|1@1+ (1,0) [0|1] "" Vector__XXX
 SG_ VCSEC_a111_EPBR_MIA m1 : 54|1@1+ (1,0) [0|1] "" Vector__XXX
 SG_ VCSEC_a112_EPBL_MIA m1 : 55|1@1+ (1,0) [0|1] "" Vector__XXX
 SG_ VCSEC_a113_UI_MIA m1 : 56|1@1+ (1,0) [0|1] "" Vector__XXX
 SG_ VCSEC_a114_ESP_MIA m1 : 57|1@1+ (1,0) [0|1] "" Vector__XXX
 SG_ VCSEC_a115_VCSEC_MIA m1 : 58|1@1+ (1,0) [0|1] "" Vector__XXX
 SG_ VCSEC_a116_VCRIGHT_MIA m1 : 59|1@1+ (1,0) [0|1] "" Vector__XXX
 SG_ VCSEC_a117_VCLEFT_MIA m1 : 60|1@1+ (1,0) [0|1] "" Vector__XXX
 SG_ VCSEC_a118_VCFRONT_MIA m1 : 61|1@1+ (1,0) [0|1] "" Vector__XXX
 SG_ VCSEC_a119_SCCM_MIA m1 : 62|1@1+ (1,0) [0|1] "" Vector__XXX
 SG_ VCSEC_a120_DI_DRIVE_MIA m1 : 63|1@1+ (1,0) [0|1] "" Vector__XXX
 SG_ VCSEC_a121_ICR_MIA m2 : 4|1@1+ (1,0) [0|1] "" Vector__XXX
 SG_ VCSEC_a133_alarmTriggered m2 : 16|1@1+ (1,0) [0|1] "" Vector__XXX
 SG_ VCSEC_a134_noVINLoaded m2 : 17|1@1+ (1,0) [0|1] "" Vector__XXX
 SG_ VCSEC_a135_centerEndpointBusy m2 : 18|1@1+ (1,0) [0|1] "" Vector__XXX
 SG_ VCSEC_a136_leftEndpointBusy m2 : 19|1@1+ (1,0) [0|1] "" Vector__XXX
 SG_ VCSEC_a137_rightEndpointBusy m2 : 20|1@1+ (1,0) [0|1] "" Vector__XXX
 SG_ VCSEC_a138_rearEndpointBusy m2 : 21|1@1+ (1,0) [0|1] "" Vector__XXX
 SG_ VCSEC_a140_nfcAuthentication m2 : 23|1@1+ (1,0) [0|1] "" Vector__XXX
 SG_ VCSEC_a141_tooFewKeysOnWhitelist m2 : 24|1@1+ (1,0) [0|1] "" Vector__XXX
 SG_ VCSEC_a142_bleGattAlertC m2 : 25|1@1+ (1,0) [0|1] "" Vector__XXX
 SG_ VCSEC_a143_bleGattAlertL m2 : 26|1@1+ (1,0) [0|1] "" Vector__XXX
 SG_ VCSEC_a144_bleGattAlertR m2 : 27|1@1+ (1,0) [0|1] "" Vector__XXX
 SG_ VCSEC_a145_bleGattAlertRe m2 : 28|1@1+ (1,0) [0|1] "" Vector__XXX
 SG_ VCSEC_a147_protobufRXTimeout m2 : 30|1@1+ (1,0) [0|1] "" Vector__XXX
 SG_ VCSEC_a148_keyWhitelistFull m2 : 31|1@1+ (1,0) [0|1] "" Vector__XXX
 SG_ VCSEC_a149_attrsWentMissingL m2 : 32|1@1+ (1,0) [0|1] "" Vector__XXX
 SG_ VCSEC_a150_attrsWentMissingR m2 : 33|1@1+ (1,0) [0|1] "" Vector__XXX
 SG_ VCSEC_a151_attrsWentMissingRe m2 : 34|1@1+ (1,0) [0|1] "" Vector__XXX
 SG_ VCSEC_a153_srvcCmdTimeoutC m2 : 36|1@1+ (1,0) [0|1] "" Vector__XXX
 SG_ VCSEC_a154_srvcCmdTimeoutL m2 : 37|1@1+ (1,0) [0|1] "" Vector__XXX
 SG_ VCSEC_a155_srvcCmdTimeoutR m2 : 38|1@1+ (1,0) [0|1] "" Vector__XXX
 SG_ VCSEC_a156_srvcCmdTimeoutRe m2 : 39|1@1+ (1,0) [0|1] "" Vector__XXX
 SG_ VCSEC_a158_hciDebugC m2 : 41|1@1+ (1,0) [0|1] "" Vector__XXX
 SG_ VCSEC_a159_hciDebugL m2 : 42|1@1+ (1,0) [0|1] "" Vector__XXX
 SG_ VCSEC_a161_hciDebugR m2 : 44|1@1+ (1,0) [0|1] "" Vector__XXX
 SG_ VCSEC_a162_hciDebugRe m2 : 45|1@1+ (1,0) [0|1] "" Vector__XXX
 SG_ VCSEC_a164_attrsWentMissingC m2 : 47|1@1+ (1,0) [0|1] "" Vector__XXX
 SG_ VCSEC_a165_ephemeralKeyGenerated m2 : 48|1@1+ (1,0) [0|1] "" Vector__XXX
 SG_ VCSEC_a166_BLECenterPowerCycled m2 : 49|1@1+ (1,0) [0|1] "" Vector__XXX
 SG_ VCSEC_a167_BLECenterSoftReset m2 : 50|1@1+ (1,0) [0|1] "" Vector__XXX
 SG_ VCSEC_a168_BLELeftSoftReset m2 : 51|1@1+ (1,0) [0|1] "" Vector__XXX
 SG_ VCSEC_a169_BLERightSoftReset m2 : 52|1@1+ (1,0) [0|1] "" Vector__XXX
 SG_ VCSEC_a170_BLERearSoftReset m2 : 53|1@1+ (1,0) [0|1] "" Vector__XXX
 SG_ VCSEC_a172_BLEUnexpectedResetC m2 : 55|1@1+ (1,0) [0|1] "" Vector__XXX
 SG_ VCSEC_a173_BLEUnexpectedResetL m2 : 56|1@1+ (1,0) [0|1] "" Vector__XXX
 SG_ VCSEC_a174_BLEUnexpectedResetRi m2 : 57|1@1+ (1,0) [0|1] "" Vector__XXX
 SG_ VCSEC_a175_BLEUnexpectedResetRe m2 : 58|1@1+ (1,0) [0|1] "" Vector__XXX
 SG_ VCSEC_a177_whitelistAddedKey m2 : 60|1@1+ (1,0) [0|1] "" Vector__XXX
 SG_ VCSEC_a178_whitelistRemovedKey m2 : 61|1@1+ (1,0) [0|1] "" Vector__XXX
 SG_ VCSEC_a179_InfotainmentNotPaired m2 : 62|1@1+ (1,0) [0|1] "" Vector__XXX
 SG_ VCSEC_a180_wlistRemovedPermissio m2 : 63|1@1+ (1,0) [0|1] "" Vector__XXX
 SG_ VCSEC_a181_signedMessageFault m3 : 4|1@1+ (1,0) [0|1] "" Vector__XXX
 SG_ VCSEC_a182_cryptoHighStackUsage m3 : 5|1@1+ (1,0) [0|1] "" Vector__XXX
 SG_ VCSEC_a183_centerEndpointRFMia m3 : 6|1@1+ (1,0) [0|1] "" Vector__XXX
 SG_ VCSEC_a184_driverEndpointRFMia m3 : 7|1@1+ (1,0) [0|1] "" Vector__XXX
 SG_ VCSEC_a185_passengerEndpointRFMi m3 : 8|1@1+ (1,0) [0|1] "" Vector__XXX
 SG_ VCSEC_a186_rearEndpointRFMia m3 : 9|1@1+ (1,0) [0|1] "" Vector__XXX
 SG_ VCSEC_a187_badConnectionDropped m3 : 10|1@1+ (1,0) [0|1] "" Vector__XXX
 SG_ VCSEC_a188_protobufDecodeError m3 : 11|1@1+ (1,0) [0|1] "" Vector__XXX
 SG_ VCSEC_a189_protoExpLengthTooLarg m3 : 12|1@1+ (1,0) [0|1] "" Vector__XXX
 SG_ VCSEC_a190_protoTooManyBytes m3 : 13|1@1+ (1,0) [0|1] "" Vector__XXX
 SG_ VCSEC_a191_macIDWlistingFailedC m3 : 14|1@1+ (1,0) [0|1] "" Vector__XXX
 SG_ VCSEC_a192_macIDWlistingFailedL m3 : 15|1@1+ (1,0) [0|1] "" Vector__XXX
 SG_ VCSEC_a193_macIDWlistingFailedRi m3 : 16|1@1+ (1,0) [0|1] "" Vector__XXX
 SG_ VCSEC_a194_macIDWlistingFailedRe m3 : 17|1@1+ (1,0) [0|1] "" Vector__XXX
 SG_ VCSEC_a195_keyMissingInDrive m3 : 18|1@1+ (1,0) [0|1] "" Vector__XXX
 SG_ VCSEC_a196_protobufTXTimeout m3 : 19|1@1+ (1,0) [0|1] "" Vector__XXX
 SG_ VCSEC_a197_indicationFault m3 : 20|1@1+ (1,0) [0|1] "" Vector__XXX
 SG_ VCSEC_a198_BPillarNFCReaderMIA m3 : 21|1@1+ (1,0) [0|1] "" Vector__XXX
 SG_ VCSEC_a199_CenterNFCReaderMIA m3 : 22|1@1+ (1,0) [0|1] "" Vector__XXX
 SG_ VCSEC_a200_centerEndpointLostCom m3 : 23|1@1+ (1,0) [0|1] "" Vector__XXX
 SG_ VCSEC_a201_leftEndpointLostComm m3 : 24|1@1+ (1,0) [0|1] "" Vector__XXX
 SG_ VCSEC_a202_rightEndpointLostComm m3 : 25|1@1+ (1,0) [0|1] "" Vector__XXX
 SG_ VCSEC_a203_rearEndpointLostComm m3 : 26|1@1+ (1,0) [0|1] "" Vector__XXX
 SG_ VCSEC_a204_SharedSecretsWritten m3 : 27|1@1+ (1,0) [0|1] "" Vector__XXX
 SG_ VCSEC_a205_MTUUpdateNotConfirmed m3 : 28|1@1+ (1,0) [0|1] "" Vector__XXX
 SG_ VCSEC_a206_BLELeftAssertFailure m3 : 29|1@1+ (1,0) [0|1] "" Vector__XXX
 SG_ VCSEC_a207_BLERightAssertFailure m3 : 30|1@1+ (1,0) [0|1] "" Vector__XXX
 SG_ VCSEC_a208_BLERearAssertFailure m3 : 31|1@1+ (1,0) [0|1] "" Vector__XXX
 SG_ VCSEC_a209_BLECenterAssertFailur m3 : 32|1@1+ (1,0) [0|1] "" Vector__XXX
 SG_ VCSEC_a210_keyDeviceBatteryLow m3 : 33|1@1+ (1,0) [0|1] "" Vector__XXX
 SG_ VCSEC_a211_handlePullWithoutAuth m3 : 34|1@1+ (1,0) [0|1] "" Vector__XXX
 SG_ VCSEC_a212_snifferRSSIMIA m3 : 35|1@1+ (1,0) [0|1] "" Vector__XXX
 SG_ VCSEC_a213_gattTimeoutWithExptdC m3 : 36|1@1+ (1,0) [0|1] "" Vector__XXX
 SG_ VCSEC_a214_gattServFalseWaitToBo m3 : 37|1@1+ (1,0) [0|1] "" Vector__XXX
 SG_ VCSEC_a215_TPMSUnexpectedDisconn m3 : 38|1@1+ (1,0) [0|1] "" Vector__XXX
 SG_ VCSEC_a216_TPMSUnexpectedDisconn m3 : 39|1@1+ (1,0) [0|1] "" Vector__XXX
 SG_ VCSEC_a217_TPMSUnexpectedDisconn m3 : 40|1@1+ (1,0) [0|1] "" Vector__XXX
 SG_ VCSEC_a218_TPMSUnexpectedDisconn m3 : 41|1@1+ (1,0) [0|1] "" Vector__XXX
 SG_ VCSEC_a219_TPMSSensorPairingRemo m3 : 42|1@1+ (1,0) [0|1] "" Vector__XXX
 SG_ VCSEC_a220_TPMSSensorPairingNotC m3 : 43|1@1+ (1,0) [0|1] "" Vector__XXX
 SG_ VCSEC_a221_TPMSSoftWarning m3 : 44|1@1+ (1,0) [0|1] "" Vector__XXX
 SG_ VCSEC_a222_TPMSSystemMalfunction m3 : 45|1@1+ (1,0) [0|1] "" Vector__XXX
 SG_ VCSEC_a223_TPMSSensorConnectionC m3 : 46|1@1+ (1,0) [0|1] "" Vector__XXX
 SG_ VCSEC_a224_TPMSSensorConnectionC m3 : 47|1@1+ (1,0) [0|1] "" Vector__XXX
 SG_ VCSEC_a225_TPMSSensorConnectionC m3 : 48|1@1+ (1,0) [0|1] "" Vector__XXX
 SG_ VCSEC_a226_TPMSSensorConnectionC m3 : 49|1@1+ (1,0) [0|1] "" Vector__XXX
 SG_ VCSEC_a227_connectionWithoutLink m3 : 50|1@1+ (1,0) [0|1] "" Vector__XXX
 SG_ VCSEC_a228_TPMSHardWarning m3 : 51|1@1+ (1,0) [0|1] "" Vector__XXX
 SG_ VCSEC_a235_presentWithoutHandleP m3 : 58|1@1+ (1,0) [0|1] "" Vector__XXX
 SG_ VCSEC_a236_keyIdentificationMaxA m3 : 59|1@1+ (1,0) [0|1] "" Vector__XXX
 SG_ VCSEC_a237_keyNotReadyToReceiveI m3 : 60|1@1+ (1,0) [0|1] "" Vector__XXX
 SG_ VCSEC_a238_TPMSLocationsUpdated m3 : 61|1@1+ (1,0) [0|1] "" Vector__XXX
 SG_ VCSEC_a239_TPMSIdleConnection m3 : 62|1@1+ (1,0) [0|1] "" Vector__XXX
 SG_ VCSEC_a240_noKeysPaired m3 : 63|1@1+ (1,0) [0|1] "" Vector__XXX
 SG_ VCSEC_a241_TPMSUpdateStartedSens m4 : 4|1@1+ (1,0) [0|1] "" Vector__XXX
 SG_ VCSEC_a242_TPMSUpdateStartedSens m4 : 5|1@1+ (1,0) [0|1] "" Vector__XXX
 SG_ VCSEC_a243_TPMSUpdateStartedSens m4 : 6|1@1+ (1,0) [0|1] "" Vector__XXX
 SG_ VCSEC_a244_TPMSUpdateStartedSens m4 : 7|1@1+ (1,0) [0|1] "" Vector__XXX
 SG_ VCSEC_a245_TPMSUpdateInterrupted m4 : 8|1@1+ (1,0) [0|1] "" Vector__XXX
 SG_ VCSEC_a246_TPMSUpdateInterrupted m4 : 9|1@1+ (1,0) [0|1] "" Vector__XXX
 SG_ VCSEC_a247_TPMSUpdateInterrupted m4 : 10|1@1+ (1,0) [0|1] "" Vector__XXX
 SG_ VCSEC_a248_TPMSUpdateInterrupted m4 : 11|1@1+ (1,0) [0|1] "" Vector__XXX
 SG_ VCSEC_a249_TPMSUpdateCompleteSen m4 : 12|1@1+ (1,0) [0|1] "" Vector__XXX
 SG_ VCSEC_a250_TPMSUpdateCompleteSen m4 : 13|1@1+ (1,0) [0|1] "" Vector__XXX
 SG_ VCSEC_a251_TPMSUpdateCompleteSen m4 : 14|1@1+ (1,0) [0|1] "" Vector__XXX
 SG_ VCSEC_a252_TPMSUpdateCompleteSen m4 : 15|1@1+ (1,0) [0|1] "" Vector__XXX
 SG_ VCSEC_a254_whitelistUpdatedKey m4 : 17|1@1+ (1,0) [0|1] "" Vector__XXX
 SG_ VCSEC_a255_wlistUpdatedPermissio m4 : 18|1@1+ (1,0) [0|1] "" Vector__XXX
 SG_ VCSEC_a256_whitelistOperationFai m4 : 19|1@1+ (1,0) [0|1] "" Vector__XXX
 SG_ VCSEC_a257_connectedKeyIsExpirin m4 : 20|1@1+ (1,0) [0|1] "" Vector__XXX
 SG_ VCSEC_a258_keyIsExpiring m4 : 21|1@1+ (1,0) [0|1] "" Vector__XXX
 SG_ VCSEC_a260_prsntPhoneKeyDisconne m4 : 23|1@1+ (1,0) [0|1] "" Vector__XXX
 SG_ VCSEC_a261_TPMSFactoryLearnActiv m4 : 24|1@1+ (1,0) [0|1] "" Vector__XXX
 SG_ VCSEC_a262_flowControlBackedUp m4 : 25|1@1+ (1,0) [0|1] "" Vector__XXX
 SG_ VCSEC_a263_dispatchCouldNotBeCom m4 : 26|1@1+ (1,0) [0|1] "" Vector__XXX
 SG_ VCSEC_a264_noOnePopulatedMessage m4 : 27|1@1+ (1,0) [0|1] "" Vector__XXX
 SG_ VCSEC_a265_tooManyPopulatedMessa m4 : 28|1@1+ (1,0) [0|1] "" Vector__XXX
 SG_ VCSEC_a266_TPMSSoftWarningFrontL m4 : 29|1@1+ (1,0) [0|1] "" Vector__XXX
 SG_ VCSEC_a267_TPMSSoftWarningFrontR m4 : 30|1@1+ (1,0) [0|1] "" Vector__XXX
 SG_ VCSEC_a268_TPMSSoftWarningRearLe m4 : 31|1@1+ (1,0) [0|1] "" Vector__XXX
 SG_ VCSEC_a269_TPMSSoftWarningRearRi m4 : 32|1@1+ (1,0) [0|1] "" Vector__XXX
 SG_ VCSEC_a270_TPMSHardWarningFrontL m4 : 33|1@1+ (1,0) [0|1] "" Vector__XXX
 SG_ VCSEC_a271_TPMSHardWarningFrontR m4 : 34|1@1+ (1,0) [0|1] "" Vector__XXX
 SG_ VCSEC_a272_TPMSHardWarningRearLe m4 : 35|1@1+ (1,0) [0|1] "" Vector__XXX
 SG_ VCSEC_a273_TPMSHardWarningRearRi m4 : 36|1@1+ (1,0) [0|1] "" Vector__XXX
 SG_ VCSEC_a274_handlePullWithoutAuth m4 : 37|1@1+ (1,0) [0|1] "" Vector__XXX
 SG_ VCSEC_a275_childSeatNotConnected m4 : 38|1@1+ (1,0) [0|1] "" Vector__XXX
 SG_ VCSEC_a276_childSeatNotConnected m4 : 39|1@1+ (1,0) [0|1] "" Vector__XXX
 SG_ VCSEC_a277_childSeatBatteryIsLow m4 : 40|1@1+ (1,0) [0|1] "" Vector__XXX
 SG_ VCSEC_a280_TPMSLowBattery0 m4 : 43|1@1+ (1,0) [0|1] "" Vector__XXX
 SG_ VCSEC_a281_TPMSLowBattery1 m4 : 44|1@1+ (1,0) [0|1] "" Vector__XXX
 SG_ VCSEC_a282_TPMSLowBattery2 m4 : 45|1@1+ (1,0) [0|1] "" Vector__XXX
 SG_ VCSEC_a283_TPMSLowBattery3 m4 : 46|1@1+ (1,0) [0|1] "" Vector__XXX
 SG_ VCSEC_a300_scheduleItKeyAdded m4 : 63|1@1+ (1,0) [0|1] "" Vector__XXX
 SG_ VCSEC_a301_imposterDetected m5 : 4|1@1+ (1,0) [0|1] "" Vector__XXX
 SG_ VCSEC_a302_unfused m5 : 5|1@1+ (1,0) [0|1] "" Vector__XXX
 SG_ VCSEC_a303_KeyfobUpdateInterrupt m5 : 6|1@1+ (1,0) [0|1] "" Vector__XXX
 SG_ VCSEC_a304_KeyfobUpdateComplete m5 : 7|1@1+ (1,0) [0|1] "" Vector__XXX
 SG_ VCSEC_a305_ATTFlowControlViolate m5 : 8|1@1+ (1,0) [0|1] "" Vector__XXX
 SG_ VCSEC_a306_KeyfobAdvReceivedWhil m5 : 9|1@1+ (1,0) [0|1] "" Vector__XXX
 SG_ VCSEC_a307_ATTTimeout m5 : 10|1@1+ (1,0) [0|1] "" Vector__XXX
 SG_ VCSEC_a308_NonConnectableAdvRece m5 : 11|1@1+ (1,0) [0|1] "" Vector__XXX
 SG_ VCSEC_a309_serviceKeyConditionsN m5 : 12|1@1+ (1,0) [0|1] "" Vector__XXX
 SG_ VCSEC_a310_chargePortFilterFalse m5 : 13|1@1+ (1,0) [0|1] "" Vector__XXX
 SG_ VCSEC_a311_moreThanThreeKeysPres m5 : 14|1@1+ (1,0) [0|1] "" Vector__XXX
 SG_ VCSEC_a312_unexpectedBLEDisconne m5 : 15|1@1+ (1,0) [0|1] "" Vector__XXX
 SG_ VCSEC_a315_bleBondingEvent m5 : 18|1@1+ (1,0) [0|1] "" Vector__XXX
 SG_ VCSEC_a316_ltkRequestRejected m5 : 19|1@1+ (1,0) [0|1] "" Vector__XXX
 SG_ VCSEC_a401_rearLeftEndpointLostC m6 : 44|1@1+ (1,0) [0|1] "" Vector__XXX
 SG_ VCSEC_a402_rearRightEndpointLost m6 : 45|1@1+ (1,0) [0|1] "" Vector__XXX
 SG_ VCSEC_a404_NFCCradleEndpointLost m6 : 47|1@1+ (1,0) [0|1] "" Vector__XXX
 SG_ VCSEC_a406_hciDebugRL m6 : 49|1@1+ (1,0) [0|1] "" Vector__XXX
 SG_ VCSEC_a407_hciDebugRR m6 : 50|1@1+ (1,0) [0|1] "" Vector__XXX
 SG_ VCSEC_a408_hciDebugNFCC m6 : 51|1@1+ (1,0) [0|1] "" Vector__XXX
 SG_ VCSEC_a411_leftRearEndpointBusy m6 : 54|1@1+ (1,0) [0|1] "" Vector__XXX
 SG_ VCSEC_a412_rightRearEndpointBusy m6 : 55|1@1+ (1,0) [0|1] "" Vector__XXX
 SG_ VCSEC_a413_NFCCradleEndpointBusy m6 : 56|1@1+ (1,0) [0|1] "" Vector__XXX
 SG_ VCSEC_a416_BLECradleNFCSoftReset m6 : 59|1@1+ (1,0) [0|1] "" Vector__XXX
 SG_ VCSEC_a417_BLERearLeftSoftReset m6 : 60|1@1+ (1,0) [0|1] "" Vector__XXX
 SG_ VCSEC_a418_BLERearRightSoftReset m6 : 61|1@1+ (1,0) [0|1] "" Vector__XXX
 SG_ VCSEC_a420_BLEUnexpectedResetNFC m6 : 63|1@1+ (1,0) [0|1] "" Vector__XXX
 SG_ VCSEC_a421_BLEUnexpectedResetRL m7 : 4|1@1+ (1,0) [0|1] "" Vector__XXX
 SG_ VCSEC_a422_BLEUnexpectedResetRR m7 : 5|1@1+ (1,0) [0|1] "" Vector__XXX
 SG_ VCSEC_a425_BLENFCCradleAssertFai m7 : 8|1@1+ (1,0) [0|1] "" Vector__XXX
 SG_ VCSEC_a426_BLERearLeftAssertFail m7 : 9|1@1+ (1,0) [0|1] "" Vector__XXX
 SG_ VCSEC_a427_BLERearRightAssertFai m7 : 10|1@1+ (1,0) [0|1] "" Vector__XXX
 SG_ VCSEC_a428_UWBCenterUpdateInterr m7 : 11|1@1+ (1,0) [0|1] "" Vector__XXX
 SG_ VCSEC_a429_UWBLeftUpdateInterrup m7 : 12|1@1+ (1,0) [0|1] "" Vector__XXX
 SG_ VCSEC_a430_UWBRightUpdateInterru m7 : 13|1@1+ (1,0) [0|1] "" Vector__XXX
 SG_ VCSEC_a432_UWBRearLeftUpdateInte m7 : 15|1@1+ (1,0) [0|1] "" Vector__XXX
 SG_ VCSEC_a433_UWBRearRightUpdateInt m7 : 16|1@1+ (1,0) [0|1] "" Vector__XXX
 SG_ VCSEC_a434_UWBRadioConfigUpdated m7 : 17|1@1+ (1,0) [0|1] "" Vector__XXX
 SG_ VCSEC_a435_NFCCardPresentWhileCh m7 : 18|1@1+ (1,0) [0|1] "" Vector__XXX
 SG_ VCSEC_a436_uhfHWDoesNotMatchCoun m7 : 19|1@1+ (1,0) [0|1] "" Vector__XXX
 SG_ VCSEC_a437_NearbyInteractionDebu m7 : 20|1@1+ (1,0) [0|1] "" Vector__XXX
 SG_ VCSEC_a438_UWBRearUpdateInterrup m7 : 21|1@1+ (1,0) [0|1] "" Vector__XXX
 SG_ VCSEC_a453_passiveDisabled m7 : 36|1@1+ (1,0) [0|1] "" Vector__XXX
 SG_ VCSEC_a454_TPMSOverPressureWarni m7 : 37|1@1+ (1,0) [0|1] "" Vector__XXX
 SG_ VCSEC_a455_TPMSOverPressureWarni m7 : 38|1@1+ (1,0) [0|1] "" Vector__XXX
 SG_ VCSEC_a456_TPMSOverPressureWarni m7 : 39|1@1+ (1,0) [0|1] "" Vector__XXX
 SG_ VCSEC_a457_TPMSOverPressureWarni m7 : 40|1@1+ (1,0) [0|1] "" Vector__XXX
 SG_ VCSEC_a458_TPMSOverPressureWarni m7 : 41|1@1+ (1,0) [0|1] "" Vector__XXX
 SG_ VCSEC_a459_TPMSCertCheckFailedSe m7 : 42|1@1+ (1,0) [0|1] "" Vector__XXX
 SG_ VCSEC_a460_TPMSCertCheckFailedSe m7 : 43|1@1+ (1,0) [0|1] "" Vector__XXX
 SG_ VCSEC_a461_TPMSCertCheckFailedSe m7 : 44|1@1+ (1,0) [0|1] "" Vector__XXX
 SG_ VCSEC_a462_TPMSCertCheckFailedSe m7 : 45|1@1+ (1,0) [0|1] "" Vector__XXX
 SG_ VCSEC_a465_UWBRearLeftKeyVerific m7 : 48|1@1+ (1,0) [0|1] "" Vector__XXX
 SG_ VCSEC_a466_UWBRearRightKeyVerifi m7 : 49|1@1+ (1,0) [0|1] "" Vector__XXX
 SG_ VCSEC_a467_UWBCenterKeyVerificat m7 : 50|1@1+ (1,0) [0|1] "" Vector__XXX
 SG_ VCSEC_a468_UWBRearKeyVerificatio m7 : 51|1@1+ (1,0) [0|1] "" Vector__XXX
 SG_ VCSEC_a469_UWBLeftKeyVerificatio m7 : 52|1@1+ (1,0) [0|1] "" Vector__XXX
 SG_ VCSEC_a470_UWBRightKeyVerificati m7 : 53|1@1+ (1,0) [0|1] "" Vector__XXX
 SG_ VCSEC_a472_peerRemovedInformatio m7 : 55|1@1+ (1,0) [0|1] "" Vector__XXX
 SG_ VCSEC_a473_handlePullWithoutAuth m7 : 56|1@1+ (1,0) [0|1] "" Vector__XXX
 SG_ VCSEC_a474_handlePullWithoutAuth m7 : 57|1@1+ (1,0) [0|1] "" Vector__XXX
 SG_ VCSEC_a475_handlePullWithoutAuth m7 : 58|1@1+ (1,0) [0|1] "" Vector__XXX
 SG_ VCSEC_a476_handlePullWithoutAuth m7 : 59|1@1+ (1,0) [0|1] "" Vector__XXX
 SG_ VCSEC_a477_phoneStartedBonding m7 : 60|1@1+ (1,0) [0|1] "" Vector__XXX
 SG_ VCSEC_a478_handlePullWithoutAuth m7 : 61|1@1+ (1,0) [0|1] "" Vector__XXX
 SG_ VCSEC_a479_handlePullWithoutAuth m7 : 62|1@1+ (1,0) [0|1] "" Vector__XXX
 SG_ VCSEC_a480_handlePullWithoutAuth m7 : 63|1@1+ (1,0) [0|1] "" Vector__XXX
 SG_ VCSEC_a481_handlePullWithoutAuth m8 : 4|1@1+ (1,0) [0|1] "" Vector__XXX
 SG_ VCSEC_a482_VINChanged m8 : 5|1@1+ (1,0) [0|1] "" Vector__XXX
 SG_ VCSEC_a483_highThermalGradiantDe m8 : 6|1@1+ (1,0) [0|1] "" Vector__XXX
 SG_ VCSEC_a484_UWBLeftUpdateTriggere m8 : 7|1@1+ (1,0) [0|1] "" Vector__XXX
 SG_ VCSEC_a485_UWBCenterUpdateTrigge m8 : 8|1@1+ (1,0) [0|1] "" Vector__XXX
 SG_ VCSEC_a486_UWBRightUpdateTrigger m8 : 9|1@1+ (1,0) [0|1] "" Vector__XXX
 SG_ VCSEC_a487_unrecognizedProto m8 : 10|1@1+ (1,0) [0|1] "" Vector__XXX
 SG_ VCSEC_a488_FiraRangingRejected m8 : 11|1@1+ (1,0) [0|1] "" Vector__XXX
 SG_ VCSEC_a489_UWBRearLeftUpdateTrig m8 : 12|1@1+ (1,0) [0|1] "" Vector__XXX
 SG_ VCSEC_a490_UWBRearRightUpdateTri m8 : 13|1@1+ (1,0) [0|1] "" Vector__XXX
 SG_ VCSEC_a494_UWBRearUpdateTriggere m8 : 17|1@1+ (1,0) [0|1] "" Vector__XXX
 SG_ VCSEC_a495_handlePullWithoutAuth m8 : 18|1@1+ (1,0) [0|1] "" Vector__XXX
 SG_ VCSEC_a496_handlePullWithoutAuth m8 : 19|1@1+ (1,0) [0|1] "" Vector__XXX
 SG_ VCSEC_a497_incorrectEndpointInst m8 : 20|1@1+ (1,0) [0|1] "" Vector__XXX
 SG_ VCSEC_a498_TPMSFeature0Reached m8 : 21|1@1+ (1,0) [0|1] "" Vector__XXX
 SG_ VCSEC_a499_TPMSAssertFailure0 m8 : 22|1@1+ (1,0) [0|1] "" Vector__XXX
 SG_ VCSEC_a500_TPMSAssertFailure1 m8 : 23|1@1+ (1,0) [0|1] "" Vector__XXX
 SG_ VCSEC_a501_TPMSAssertFailure2 m8 : 24|1@1+ (1,0) [0|1] "" Vector__XXX
 SG_ VCSEC_a502_TPMSAssertFailure3 m8 : 25|1@1+ (1,0) [0|1] "" Vector__XXX
 SG_ VCSEC_a503_CANMsgMACVerification m8 : 26|1@1+ (1,0) [0|1] "" Vector__XXX
 SG_ VCSEC_a504_CANMsgMACVerification m8 : 27|1@1+ (1,0) [0|1] "" Vector__XXX
 SG_ VCSEC_a505_CANMsgMACVerification m8 : 28|1@1+ (1,0) [0|1] "" Vector__XXX
 SG_ VCSEC_a510_watchKeyOffWrist m8 : 33|1@1+ (1,0) [0|1] "" Vector__XXX
 SG_ VCSEC_a511_phoneKeyStationary m8 : 34|1@1+ (1,0) [0|1] "" Vector__XXX
 SG_ VCSEC_a513_TPMSConnectionStatsNo m8 : 36|1@1+ (1,0) [0|1] "" Vector__XXX
 SG_ VCSEC_a514_TPMSConnectionStatsNo m8 : 37|1@1+ (1,0) [0|1] "" Vector__XXX
 SG_ VCSEC_a515_TPMSConnectionStatsNo m8 : 38|1@1+ (1,0) [0|1] "" Vector__XXX
 SG_ VCSEC_a516_TPMSConnectionStatsNo m8 : 39|1@1+ (1,0) [0|1] "" Vector__XXX
 SG_ VCSEC_a517_TPMSOutOfRangePressur m8 : 40|1@1+ (1,0) [0|1] "" Vector__XXX
 SG_ VCSEC_a518_TPMSOutOfRangePressur m8 : 41|1@1+ (1,0) [0|1] "" Vector__XXX
 SG_ VCSEC_a519_TPMSOutOfRangePressur m8 : 42|1@1+ (1,0) [0|1] "" Vector__XXX
 SG_ VCSEC_a520_TPMSOutOfRangePressur m8 : 43|1@1+ (1,0) [0|1] "" Vector__XXX
 SG_ VCSEC_a521_TPMSSensorLowConfiden m8 : 44|1@1+ (1,0) [0|1] "" Vector__XXX
 SG_ VCSEC_a522_TPMSSensorLowConfiden m8 : 45|1@1+ (1,0) [0|1] "" Vector__XXX
 SG_ VCSEC_a523_TPMSSensorLowConfiden m8 : 46|1@1+ (1,0) [0|1] "" Vector__XXX
 SG_ VCSEC_a524_TPMSSensorLowConfiden m8 : 47|1@1+ (1,0) [0|1] "" Vector__XXX
 SG_ VCSEC_a525_TPMSLocalizationMulti m8 : 48|1@1+ (1,0) [0|1] "" Vector__XXX
 SG_ VCSEC_a526_TPMSLocalizationMulti m8 : 49|1@1+ (1,0) [0|1] "" Vector__XXX
 SG_ VCSEC_a527_TPMSLocalizationMulti m8 : 50|1@1+ (1,0) [0|1] "" Vector__XXX
 SG_ VCSEC_a528_TPMSLocalizationMulti m8 : 51|1@1+ (1,0) [0|1] "" Vector__XXX
 SG_ VCSEC_a529_TPMSTireServiceDetect m8 : 52|1@1+ (1,0) [0|1] "" Vector__XXX
 SG_ VCSEC_a540_dummyAlertMax m8 : 63|1@1+ (1,0) [0|1] "" Vector__XXX

BO_ 825 VCSEC_authentication: 8 VCSEC
 SG_ VCSEC_BLEConnectionCounter : 0|4@1+ (1,0) [0|15] "" Vector__XXX
 SG_ VCSEC_authRejectionReason : 4|3@1+ (1,0) [0|7] "" Vector__XXX
 SG_ VCSEC_IDRequested : 7|1@1+ (1,0) [0|1] "" Vector__XXX
 SG_ VCSEC_operationMode : 8|2@1+ (1,0) [0|3] "" Vector__XXX
 SG_ VCSEC_vehicleLockStatus : 12|4@1+ (1,0) [0|15] "" Vector__XXX
 SG_ VCSEC_authenticationStatus : 16|2@1+ (1,0) [0|3] "" Vector__XXX
 SG_ VCSEC_chargePortLockStatus : 18|1@1+ (1,0) [0|1] "" Vector__XXX
 SG_ VCSEC_leftFrontLockStatus : 19|1@1+ (1,0) [0|1] "" Vector__XXX
 SG_ VCSEC_leftRearLockStatus : 20|1@1+ (1,0) [0|1] "" Vector__XXX
 SG_ VCSEC_rightFrontLockStatus : 21|1@1+ (1,0) [0|1] "" Vector__XXX
 SG_ VCSEC_rightRearLockStatus : 22|1@1+ (1,0) [0|1] "" Vector__XXX
 SG_ VCSEC_trunkLockStatus : 23|1@1+ (1,0) [0|1] "" Vector__XXX
 SG_ VCSEC_lockRequestType : 24|5@1+ (1,0) [0|31] "" Vector__XXX
 SG_ VCSEC_summonRequest : 29|3@1+ (1,0) [0|7] "" Vector__XXX
 SG_ VCSEC_3rdPartyPLGRequest : 32|2@1+ (1,0) [0|3] "" Vector__XXX
 SG_ VCSEC_3rdPartyFrunkPLGRequest : 34|2@1+ (1,0) [0|3] "" Vector__XXX
 SG_ VCSEC_MCUCommandType : 36|3@1+ (1,0) [0|7] "" Vector__XXX
 SG_ VCSEC_frunkLockStatus : 39|1@1+ (1,0) [0|1] "" Vector__XXX
 SG_ VCSEC_usingModifiedMACAddress : 40|1@1+ (1,0) [0|1] "" Vector__XXX
 SG_ VCSEC_isKeyWithinSummonRange : 41|1@1+ (1,0) [0|1] "" Vector__XXX
 SG_ VCSEC_isBLEDeviceWithinSummonRan : 42|1@1+ (1,0) [0|1] "" Vector__XXX
 SG_ VCSEC_alarmStatus : 43|4@1+ (1,0) [0|15] "" Vector__XXX
 SG_ VCSEC_serviceDiagnosticRequest : 47|1@1+ (1,0) [0|1] "" Vector__XXX
 SG_ VCSEC_immobilizerState : 48|3@1+ (1,0) [0|7] "" Vector__XXX
 SG_ VCSEC_lockIndicationRequest : 51|3@1+ (1,0) [0|7] "" Vector__XXX
 SG_ VCSEC_simpleLockStatus : 54|2@1+ (1,0) [0|3] "" Vector__XXX
 SG_ VCSEC_keyChannelIndexed : 56|4@1+ (1,0) [0|15] "" Vector__XXX
 SG_ VCSEC_authRequested : 60|1@1+ (1,0) [0|1] "" Vector__XXX
 SG_ VCSEC_remoteStartActive : 61|2@1+ (1,0) [0|3] "" Vector__XXX
 SG_ VCSEC_keyPairDesired : 63|1@1+ (1,0) [0|1] "" Vector__XXX

BO_ 1817 VCSEC_debug100ms: 8 VCSEC
 SG_ VCSEC_debug100msIndex M : 0|5@1+ (1,0) [0|31] "" Vector__XXX
 SG_ VCSEC_walkAwayLockKeyState m0 : 5|2@1+ (1,0) [0|3] "" Vector__XXX
 SG_ VCSEC_thresholdOffsetVersion m0 : 8|3@1+ (1,0) [0|7] "" Vector__XXX
 SG_ VCSEC_walkAwayLockState m0 : 11|3@1+ (1,0) [0|7] "" Vector__XXX
 SG_ VCSEC_rssi0WLEntry m0 : 16|5@1+ (1,0) [0|31] "" Vector__XXX
 SG_ VCSEC_endpointLayout m0 : 21|2@1+ (1,0) [0|3] "" Vector__XXX
 SG_ VCSEC_rssi1WLEntry m0 : 24|5@1+ (1,0) [0|31] "" Vector__XXX
 SG_ VCSEC_rssi2WLEntry m0 : 32|5@1+ (1,0) [0|31] "" Vector__XXX
 SG_ VCSEC_walkUpUnlockState m0 : 37|3@1+ (1,0) [0|7] "" Vector__XXX
 SG_ VCSEC_algoHighThreshLeft m0 : 40|1@1+ (1,0) [0|1] "" Vector__XXX
 SG_ VCSEC_algoHighThreshRight m0 : 41|1@1+ (1,0) [0|1] "" Vector__XXX
 SG_ VCSEC_algoHighThreshCenter m0 : 42|1@1+ (1,0) [0|1] "" Vector__XXX
 SG_ VCSEC_pollingReason m0 : 43|4@1+ (1,0) [0|15] "" Vector__XXX
 SG_ VCSEC_numberOfPubKeysOnWhitelist m0 : 48|5@1+ (1,0) [0|31] "" Vector__XXX
 SG_ VCSEC_thermalDetectState m0 : 53|2@1+ (1,0) [0|3] "" Vector__XXX
 SG_ VCSEC_chargeHandleMitigationActi m0 : 55|1@1+ (1,0) [0|1] "" Vector__XXX
 SG_ VCSEC_smartTrunkMitigatedKeyCoun m5 : 8|5@1+ (1,0) [0|31] "" Vector__XXX
 SG_ VCSEC_UWB3WLEntry m5 : 21|5@1+ (1,0) [0|31] "" Vector__XXX
 SG_ VCSEC_device0Offset m5 : 26|6@1- (0.5,0) [-16|15.5] "dBm" Vector__XXX
 SG_ VCSEC_device1Offset m5 : 32|6@1- (0.5,0) [-16|15.5] "dBm" Vector__XXX
 SG_ VCSEC_device2Offset m5 : 40|6@1- (0.5,0) [-16|15.5] "dBm" Vector__XXX
 SG_ VCSEC_connection0BondingState m7 : 8|4@1+ (1,0) [0|15] "" Vector__XXX
 SG_ VCSEC_connection1BondingState m7 : 12|4@1+ (1,0) [0|15] "" Vector__XXX
 SG_ VCSEC_connection2BondingState m7 : 16|4@1+ (1,0) [0|15] "" Vector__XXX
 SG_ VCSEC_connection0UWBAvailability m7 : 24|5@1+ (1,0) [0|31] "" Vector__XXX
 SG_ VCSEC_connection1UWBAvailability m7 : 32|5@1+ (1,0) [0|31] "" Vector__XXX
 SG_ VCSEC_connection2UWBAvailability m7 : 40|5@1+ (1,0) [0|31] "" Vector__XXX
 SG_ VCSEC_NISessionStateCenter0 m8 : 8|5@1+ (1,0) [0|31] "" Vector__XXX
 SG_ VCSEC_NISessionStateLeft0 m8 : 16|5@1+ (1,0) [0|31] "" Vector__XXX
 SG_ VCSEC_NISessionStateRight0 m8 : 24|5@1+ (1,0) [0|31] "" Vector__XXX
 SG_ VCSEC_NISessionStateRearLeft0 m8 : 29|5@1+ (1,0) [0|31] "" Vector__XXX
 SG_ VCSEC_NISessionStateRearRight0 m8 : 34|5@1+ (1,0) [0|31] "" Vector__XXX
 SG_ VCSEC_NISessionStateRear0 m8 : 39|5@1+ (1,0) [0|31] "" Vector__XXX
 SG_ VCSEC_NISessionStateCenter1 m8 : 44|5@1+ (1,0) [0|31] "" Vector__XXX
 SG_ VCSEC_NISessionStateLeft1 m8 : 49|5@1+ (1,0) [0|31] "" Vector__XXX
 SG_ VCSEC_NISessionStateRight1 m8 : 54|5@1+ (1,0) [0|31] "" Vector__XXX
 SG_ VCSEC_NISessionStateRearLeft1 m8 : 59|5@1+ (1,0) [0|31] "" Vector__XXX
 SG_ VCSEC_NISessionStateRearRight1 m9 : 8|5@1+ (1,0) [0|31] "" Vector__XXX
 SG_ VCSEC_NISessionStateRear1 m9 : 16|5@1+ (1,0) [0|31] "" Vector__XXX
 SG_ VCSEC_NISessionStateCenter2 m9 : 24|5@1+ (1,0) [0|31] "" Vector__XXX
 SG_ VCSEC_NISessionStateLeft2 m9 : 32|5@1+ (1,0) [0|31] "" Vector__XXX
 SG_ VCSEC_NISessionStateRight2 m9 : 40|5@1+ (1,0) [0|31] "" Vector__XXX
 SG_ VCSEC_NISessionStateRearLeft2 m9 : 48|5@1+ (1,0) [0|31] "" Vector__XXX
 SG_ VCSEC_NISessionStateRearRight2 m9 : 53|5@1+ (1,0) [0|31] "" Vector__XXX
 SG_ VCSEC_NISessionStateRear2 m9 : 58|5@1+ (1,0) [0|31] "" Vector__XXX
 SG_ VCSEC_NISessionStateLeft3 m10 : 8|5@1+ (1,0) [0|31] "" Vector__XXX
 SG_ VCSEC_NISessionStateRight3 m10 : 16|5@1+ (1,0) [0|31] "" Vector__XXX
 SG_ VCSEC_NISessionStateRearRight3 m10 : 24|5@1+ (1,0) [0|31] "" Vector__XXX
 SG_ VCSEC_NISessionStateRearLeft3 m10 : 32|5@1+ (1,0) [0|31] "" Vector__XXX
 SG_ VCSEC_NISessionStateCenter3 m10 : 40|5@1+ (1,0) [0|31] "" Vector__XXX

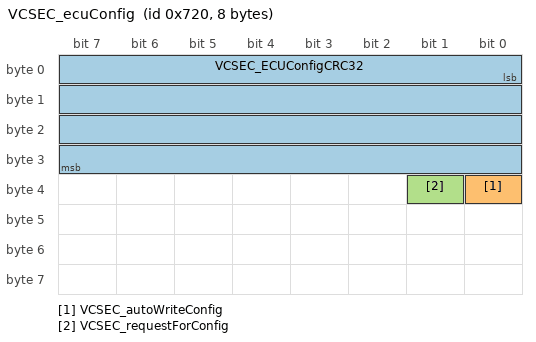
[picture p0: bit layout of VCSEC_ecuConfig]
BO_ 1824 VCSEC_ecuConfig: 8 VCSEC
 SG_ VCSEC_ECUConfigCRC32 : 0|32@1+ (1,0) [0|4294967295] "" Vector__XXX
 SG_ VCSEC_autoWriteConfig : 32|1@1+ (1,0) [0|1] "" Vector__XXX
 SG_ VCSEC_requestForConfig : 33|1@1+ (1,0) [0|1] "" Vector__XXX

BO_ 793 VCSEC_info: 8 VCSEC
 SG_ VCSEC_infoIndex M : 0|8@1+ (1,0) [0|255] "" Vector__XXX
 SG_ VCSEC_infoBuildType m10 : 8|3@1+ (1,0) [0|7] "" Vector__XXX
 SG_ VCSEC_infoBuildConfigId m10 : 16|16@1+ (1,0) [0|65535] "" Vector__XXX
 SG_ VCSEC_infoHardwareId m10 : 32|16@1+ (1,0) [0|65535] "" Vector__XXX
 SG_ VCSEC_infoComponentId m10 : 48|16@1+ (1,0) [0|65535] "" Vector__XXX
 SG_ VCSEC_infoPcbaId m11 : 8|8@1+ (1,0) [0|255] "" Vector__XXX
 SG_ VCSEC_infoAssemblyId m11 : 16|8@1+ (1,0) [0|255] "" Vector__XXX
 SG_ VCSEC_infoUsageId m11 : 32|16@1+ (1,0) [0|65535] "" Vector__XXX
 SG_ VCSEC_infoSubUsageId m11 : 48|16@1+ (1,0) [0|65535] "" Vector__XXX
 SG_ VCSEC_infoAppCrc m13 : 32|32@1+ (1,0) [0|4294967295] "" Vector__XXX
 SG_ VCSEC_infoSubcomponent1 m16 : 32|32@1+ (1,0) [0|4294967295] "" Vector__XXX
 SG_ VCSEC_infoAppGitHash m17 : 8|56@1+ (1,0) [0|7.20575940379e+16] "" Vector__XXX
 SG_ VCSEC_infoBootGitHash m18 : 8|56@1+ (1,0) [0|7.20575940379e+16] "" Vector__XXX
 SG_ VCSEC_infoPlatformType m19 : 8|8@1+ (1,0) [0|255] "" Vector__XXX
 SG_ VCSEC_infoBootUdsProtoVersion m20 : 8|16@1+ (1,0) [0|65535] "" Vector__XXX
 SG_ VCSEC_infoBootCrc m20 : 24|32@1+ (1,0) [0|4294967295] "" Vector__XXX
 SG_ VCSEC_infoSubcomponent2 m23 : 32|32@1+ (1,0) [0|4294967295] "" Vector__XXX
 SG_ VCSEC_infoSubcomponent3 m24 : 32|32@1+ (1,0) [0|4294967295] "" Vector__XXX
 SG_ VCSEC_infoSubcomponent4 m31 : 32|32@1+ (1,0) [0|4294967295] "" Vector__XXX

CM_ BO_ 1328 "Vehicle security controller message: alert log";
CM_ SG_ 1328 VCSEC_alertID "Vehicle security controller: alert ID";
CM_ SG_ 1328 VCSEC_alertState "Vehicle security controller: alert state";
CM_ SG_ 1328 VCSEC_a001_InternalWatchdog "Vehicle security controller: a001 internal watchdog";
CM_ SG_ 1328 VCSEC_a010_UnderVoltageDetected "Vehicle security controller: a010 under voltage detected";
CM_ SG_ 1328 VCSEC_a010_UnderVoltageTimeout "Vehicle security controller: a010 under voltage timeout";
CM_ SG_ 1328 VCSEC_a015_NVMMMemOverflow "Vehicle security controller: a015 NVMM mem overflow";
CM_ SG_ 1328 VCSEC_a015_NVMMFilesystemError "Vehicle security controller: a015 NVMM filesystem error";
CM_ SG_ 1328 VCSEC_a015_NVMMRecordIDError "Vehicle security controller: a015 NVMM record ID error";
CM_ SG_ 1328 VCSEC_a057_VEH_cpControl "Vehicle security controller: a057 VEH cp control";
CM_ SG_ 1328 VCSEC_a059_voltageDrop "Vehicle security controller: a059 voltage drop";
CM_ SG_ 1328 VCSEC_a059_resistanceEstimate "Vehicle security controller: a059 resistance estimate";
CM_ SG_ 1328 VCSEC_a059_current "Vehicle security controller: a059 current";
CM_ SG_ 1328 VCSEC_a063_switchChannel "Vehicle security controller: a063 switch channel";
CM_ SG_ 1328 VCSEC_a063_switchType "Vehicle security controller: a063 switch type";
CM_ SG_ 1328 VCSEC_a063_ADCVoltage "Vehicle security controller: a063 ADC voltage";
CM_ SG_ 1328 VCSEC_a063_disconnected "Vehicle security controller: a063 disconnected";
CM_ SG_ 1328 VCSEC_a063_indeterminate "Vehicle security controller: a063 indeterminate";
CM_ SG_ 1328 VCSEC_a063_stuckActive "Vehicle security controller: a063 stuck active";
CM_ SG_ 1328 VCSEC_a063_faulted "Vehicle security controller: a063 faulted";
CM_ SG_ 1328 VCSEC_a082_RIPC_epbPrivateState "Vehicle security controller: a082 RIPC epb private state";
CM_ SG_ 1328 VCSEC_a082_RIPC_remoteHSD "Vehicle security controller: a082 RIPC remote HSD";
CM_ SG_ 1328 VCSEC_a082_RIPC_railStatus "Vehicle security controller: a082 RIPC rail status";
CM_ SG_ 1328 VCSEC_a082_RIPC_remoteMux "Vehicle security controller: a082 RIPC remote mux";
CM_ SG_ 1328 VCSEC_a083_LIPC_epbPrivateState "Vehicle security controller: a083 LIPC epb private state";
CM_ SG_ 1328 VCSEC_a083_LIPC_remoteHSD "Vehicle security controller: a083 LIPC remote HSD";
CM_ SG_ 1328 VCSEC_a083_LIPC_railStatus "Vehicle security controller: a083 LIPC rail status";
CM_ SG_ 1328 VCSEC_a083_LIPC_HSDFaults "Vehicle security controller: a083 LIPC HSD faults";
CM_ SG_ 1328 VCSEC_a084_CH_StatusC "Vehicle security controller: a084 CH status c";
CM_ SG_ 1328 VCSEC_a085_PARTY_buttonStatus "Vehicle security controller: a085 PARTY button status";
CM_ SG_ 1328 VCSEC_a086_VEH_LVBMS_statusHigh "Vehicle security controller: a086 VEH LVBMS status high";
CM_ SG_ 1328 VCSEC_a086_VEH_LVBMS_statusLow "Vehicle security controller: a086 VEH LVBMS status low";
CM_ SG_ 1328 VCSEC_a086_VEH_status "Vehicle security controller: a086 VEH status";
CM_ SG_ 1328 VCSEC_a086_VEH_12VBatteryStatus "Vehicle security controller: a086 VEH 12 v battery status";
CM_ SG_ 1328 VCSEC_a086_VEH_LVPowerState "Vehicle security controller: a086 VEH LV power state";
CM_ SG_ 1328 VCSEC_a086_VEH_lightStatus "Vehicle security controller: a086 VEH light status";
CM_ SG_ 1328 VCSEC_a086_VEH_systemStatus "Vehicle security controller: a086 VEH system status";
CM_ SG_ 1328 VCSEC_a086_VEH_thermalStatus "Vehicle security controller: a086 VEH thermal status";
CM_ SG_ 1328 VCSEC_a086_VEH_vehNm "Vehicle security controller: a086 VEH veh nm";
CM_ SG_ 1328 VCSEC_a087_VEH_temperature "Vehicle security controller: a087 VEH temperature";
CM_ SG_ 1328 VCSEC_a087_VEH_thermalControl "Vehicle security controller: a087 VEH thermal control";
CM_ SG_ 1328 VCSEC_a087_VEH_torque "Vehicle security controller: a087 VEH torque";
CM_ SG_ 1328 VCSEC_a087_VEH_status "Vehicle security controller: a087 VEH status";
CM_ SG_ 1328 VCSEC_a087_PARTY_torque "Vehicle security controller: a087 PARTY torque";
CM_ SG_ 1328 VCSEC_a087_PARTY_status "Vehicle security controller: a087 PARTY status";
CM_ SG_ 1328 VCSEC_a087_PARTY_temperature "Vehicle security controller: a087 PARTY temperature";
CM_ SG_ 1328 VCSEC_a087_PARTY_thermalControl "Vehicle security controller: a087 PARTY thermal control";
CM_ SG_ 1328 VCSEC_a087_VEH_motorStatus "Vehicle security controller: a087 VEH motor status";
CM_ SG_ 1328 VCSEC_a088_VEH_temperature "Vehicle security controller: a088 VEH temperature";
CM_ SG_ 1328 VCSEC_a088_VEH_thermalControl "Vehicle security controller: a088 VEH thermal control";
CM_ SG_ 1328 VCSEC_a088_VEH_torque "Vehicle security controller: a088 VEH torque";
CM_ SG_ 1328 VCSEC_a088_VEH_status "Vehicle security controller: a088 VEH status";
CM_ SG_ 1328 VCSEC_a088_PARTY_torque "Vehicle security controller: a088 PARTY torque";
CM_ SG_ 1328 VCSEC_a088_PARTY_status "Vehicle security controller: a088 PARTY status";
CM_ SG_ 1328 VCSEC_a088_PARTY_temperature "Vehicle security controller: a088 PARTY temperature";
CM_ SG_ 1328 VCSEC_a088_PARTY_thermalControl "Vehicle security controller: a088 PARTY thermal control";
CM_ SG_ 1328 VCSEC_a088_VEH_motorStatus "Vehicle security controller: a088 VEH motor status";
CM_ SG_ 1328 VCSEC_a089_PARTY_party1 "Vehicle security controller: a089 PARTY party1";
CM_ SG_ 1328 VCSEC_a089_PARTY_status "Vehicle security controller: a089 PARTY status";
CM_ SG_ 1328 VCSEC_a089_VEH_status "Vehicle security controller: a089 VEH status";
CM_ SG_ 1328 VCSEC_a089_BDY_party1 "Vehicle security controller: a089 BDY party1";
CM_ SG_ 1328 VCSEC_a089_BDY_status "Vehicle security controller: a089 BDY status";
CM_ SG_ 1328 VCSEC_a089_CH_status "Vehicle security controller: a089 CH status";
CM_ SG_ 1328 VCSEC_a089_CH_party1 "Vehicle security controller: a089 CH party1";
CM_ SG_ 1328 VCSEC_a089_CH_party3 "Vehicle security controller: a089 CH party3";
CM_ SG_ 1328 VCSEC_a089_VEH_party1 "Vehicle security controller: a089 VEH party1";
CM_ SG_ 1328 VCSEC_a089_VEH_party3 "Vehicle security controller: a089 VEH party3";
CM_ SG_ 1328 VCSEC_a091_VEH_faultsAndExtras "Vehicle security controller: a091 VEH faults and extras";
CM_ SG_ 1328 VCSEC_a091_VEH_info "Vehicle security controller: a091 VEH info";
CM_ SG_ 1328 VCSEC_a091_VEH_state "Vehicle security controller: a091 VEH state";
CM_ SG_ 1328 VCSEC_a092_VEH_restraintStatus "Vehicle security controller: a092 VEH restraint status";
CM_ SG_ 1328 VCSEC_a092_VEH_switchStatus "Vehicle security controller: a092 VEH switch status";
CM_ SG_ 1328 VCSEC_a092_VEH_seatStatus2 "Vehicle security controller: a092 VEH seat status2";
CM_ SG_ 1328 VCSEC_a092_VEH_vehNm "Vehicle security controller: a092 VEH veh nm";
CM_ SG_ 1328 VCSEC_a093_VEH_restraintStatus "Vehicle security controller: a093 VEH restraint status";
CM_ SG_ 1328 VCSEC_a093_VEH_switchStatus "Vehicle security controller: a093 VEH switch status";
CM_ SG_ 1328 VCSEC_a093_VEH_seatStatus2 "Vehicle security controller: a093 VEH seat status2";
CM_ SG_ 1328 VCSEC_a093_VEH_vehNm "Vehicle security controller: a093 VEH veh nm";
CM_ SG_ 1328 VCSEC_a094_VEH_sysStatus "Vehicle security controller: a094 VEH sys status";
CM_ SG_ 1328 VCSEC_a094_PARTY_sysStatus "Vehicle security controller: a094 PARTY sys status";
CM_ SG_ 1328 VCSEC_a094_CH_sysStatus "Vehicle security controller: a094 CH sys status";
CM_ SG_ 1328 VCSEC_a095_PT_ptNm "Vehicle security controller: a095 PT pt nm";
CM_ SG_ 1328 VCSEC_a095_PT_status "Vehicle security controller: a095 PT status";
CM_ SG_ 1328 VCSEC_a096_VEH_status "Vehicle security controller: a096 VEH status";
CM_ SG_ 1328 VCSEC_a096_CH_status "Vehicle security controller: a096 CH status";
CM_ SG_ 1328 VCSEC_a097_VEH_HVStatus "Vehicle security controller: a097 VEH HV status";
CM_ SG_ 1328 VCSEC_a097_VEH_state "Vehicle security controller: a097 VEH state";
CM_ SG_ 1328 VCSEC_a098_CH_torque "Vehicle security controller: a098 CH torque";
CM_ SG_ 1328 VCSEC_a098_VEH_hvStatus "Vehicle security controller: a098 VEH hv status";
CM_ SG_ 1328 VCSEC_a098_VEH_status "Vehicle security controller: a098 VEH status";
CM_ SG_ 1328 VCSEC_a098_VEH_thermalControl "Vehicle security controller: a098 VEH thermal control";
CM_ SG_ 1328 VCSEC_a098_VEH_temperature "Vehicle security controller: a098 VEH temperature";
CM_ SG_ 1328 VCSEC_a098_VEH_torque "Vehicle security controller: a098 VEH torque";
CM_ SG_ 1328 VCSEC_a098_PARTY_status "Vehicle security controller: a098 PARTY status";
CM_ SG_ 1328 VCSEC_a098_PARTY_temperature "Vehicle security controller: a098 PARTY temperature";
CM_ SG_ 1328 VCSEC_a098_PARTY_thermalControl "Vehicle security controller: a098 PARTY thermal control";
CM_ SG_ 1328 VCSEC_a098_PARTY_torque "Vehicle security controller: a098 PARTY torque";
CM_ SG_ 1328 VCSEC_a098_PT_thermalControl "Vehicle security controller: a098 PT thermal control";
CM_ SG_ 1328 VCSEC_a098_PT_temperature "Vehicle security controller: a098 PT temperature";
CM_ SG_ 1328 VCSEC_a098_PARTY_motorStatus "Vehicle security controller: a098 PARTY motor status";
CM_ SG_ 1328 VCSEC_a098_VEH_motorStatus "Vehicle security controller: a098 VEH motor status";
CM_ SG_ 1328 VCSEC_a099_VEH_oocStatus "Vehicle security controller: a099 VEH ooc status";
CM_ SG_ 1328 VCSEC_a100_VEH "Vehicle security controller: a100 VEH";
CM_ SG_ 1328 VCSEC_a100_PARTY "Vehicle security controller: a100 PARTY";
CM_ SG_ 1328 VCSEC_a100_PT "Vehicle security controller: a100 PT";
CM_ SG_ 1328 VCSEC_a100_CH "Vehicle security controller: a100 CH";
CM_ SG_ 1328 VCSEC_a100_OBD "Vehicle security controller: a100 OBD";
CM_ SG_ 1328 VCSEC_a101_VEH_state "Vehicle security controller: a101 VEH state";
CM_ SG_ 1328 VCSEC_a101_PARTY_locState "Vehicle security controller: a101 PARTY loc state";
CM_ SG_ 1328 VCSEC_a101_LIPC_externalWatchdog "Vehicle security controller: a101 LIPC external watchdog heart beat";
CM_ SG_ 1328 VCSEC_a101_VEH_locState "Vehicle security controller: a101 VEH loc state";
CM_ SG_ 1328 VCSEC_a101_BDY_locState "Vehicle security controller: a101 BDY loc state";
CM_ SG_ 1328 VCSEC_a102_VEH_faultsAndExtras "Vehicle security controller: a102 VEH faults and extras";
CM_ SG_ 1328 VCSEC_a102_VEH_feedbackStatus "Vehicle security controller: a102 VEH feedback status";
CM_ SG_ 1328 VCSEC_a102_VEH_sensorStatus "Vehicle security controller: a102 VEH sensor status";
CM_ SG_ 1328 VCSEC_a102_VEH_rods "Vehicle security controller: a102 VEH rods";
CM_ SG_ 1328 VCSEC_a103_VEH_hvsNm "Vehicle security controller: a103 VEH hvs nm";
CM_ SG_ 1328 VCSEC_a103_VEH_vehNm "Vehicle security controller: a103 VEH veh nm";
CM_ SG_ 1328 VCSEC_a103_VEH_status "Vehicle security controller: a103 VEH status";
CM_ SG_ 1328 VCSEC_a103_PT_ptNm "Vehicle security controller: a103 PT pt nm";
CM_ SG_ 1328 VCSEC_a103_PT_status "Vehicle security controller: a103 PT status";
CM_ SG_ 1328 VCSEC_a103_VEH_evseStatus "Vehicle security controller: a103 VEH evse status";
CM_ SG_ 1328 VCSEC_a105_VEH_states "Vehicle security controller: a105 VEH states";
CM_ SG_ 1328 VCSEC_a105_VEH_chNm "Vehicle security controller: a105 VEH ch nm";
CM_ SG_ 1328 VCSEC_a105_VEH_dampingStates "Vehicle security controller: a105 VEH damping states";
CM_ SG_ 1328 VCSEC_a106_VEH_dcdcStatus "Vehicle security controller: a106 VEH dcdc status";
CM_ SG_ 1328 VCSEC_a106_VEH_thermalControl "Vehicle security controller: a106 VEH thermal control";
CM_ SG_ 1328 VCSEC_a106_VEH_dcdcRailStatus "Vehicle security controller: a106 VEH dcdc rail status";
CM_ SG_ 1328 VCSEC_a106_CH_dcdcRailStatus "Vehicle security controller: a106 CH dcdc rail status";
CM_ SG_ 1328 VCSEC_a106_CH_alertMatrix "Vehicle security controller: a106 CH alert matrix";
CM_ SG_ 1328 VCSEC_a107_VEH_hvsNm "Vehicle security controller: a107 VEH hvs nm";
CM_ SG_ 1328 VCSEC_a107_VEH_vehNm "Vehicle security controller: a107 VEH veh nm";
CM_ SG_ 1328 VCSEC_a107_VEH_status "Vehicle security controller: a107 VEH status";
CM_ SG_ 1328 VCSEC_a107_VEH_thermalStatus "Vehicle security controller: a107 VEH thermal status";
CM_ SG_ 1328 VCSEC_a107_VEH_bmbMinMax "Vehicle security controller: a107 VEH bmb min max";
CM_ SG_ 1328 VCSEC_a107_VEH_powerAvailable "Vehicle security controller: a107 VEH power available";
CM_ SG_ 1328 VCSEC_a107_PT_ptNm "Vehicle security controller: a107 PT pt nm";
CM_ SG_ 1328 VCSEC_a107_PT_status "Vehicle security controller: a107 PT status";
CM_ SG_ 1328 VCSEC_a107_PT_thermalStatus "Vehicle security controller: a107 PT thermal status";
CM_ SG_ 1328 VCSEC_a107_PT_socStatus "Vehicle security controller: a107 PT soc status";
CM_ SG_ 1328 VCSEC_a107_VEH_socStatus "Vehicle security controller: a107 VEH soc status";
CM_ SG_ 1328 VCSEC_a107_VEH_packConfig "Vehicle security controller: a107 VEH pack config";
CM_ SG_ 1328 VCSEC_a107_VEH_energyStatus "Vehicle security controller: a107 VEH energy status";
CM_ SG_ 1328 VCSEC_a107_VEH_chargeInfo "Vehicle security controller: a107 VEH charge info";
CM_ SG_ 1328 VCSEC_a108_VEH_hvStatus "Vehicle security controller: a108 VEH hv status";
CM_ SG_ 1328 VCSEC_a108_VEH_temperature "Vehicle security controller: a108 VEH temperature";
CM_ SG_ 1328 VCSEC_a108_VEH_thermalControl "Vehicle security controller: a108 VEH thermal control";
CM_ SG_ 1328 VCSEC_a108_VEH_torque "Vehicle security controller: a108 VEH torque";
CM_ SG_ 1328 VCSEC_a108_VEH_status "Vehicle security controller: a108 VEH status";
CM_ SG_ 1328 VCSEC_a108_PARTY_torque "Vehicle security controller: a108 PARTY torque";
CM_ SG_ 1328 VCSEC_a108_PARTY_status "Vehicle security controller: a108 PARTY status";
CM_ SG_ 1328 VCSEC_a108_PARTY_temperature "Vehicle security controller: a108 PARTY temperature";
CM_ SG_ 1328 VCSEC_a108_PARTY_thermalControl "Vehicle security controller: a108 PARTY thermal control";
CM_ SG_ 1328 VCSEC_a108_PT_temperature "Vehicle security controller: a108 PT temperature";
CM_ SG_ 1328 VCSEC_a108_PT_thermalControl "Vehicle security controller: a108 PT thermal control";
CM_ SG_ 1328 VCSEC_a108_PARTY_motorStatus "Vehicle security controller: a108 PARTY motor status";
CM_ SG_ 1328 VCSEC_a108_VEH_motorStatus "Vehicle security controller: a108 VEH motor status";
CM_ SG_ 1328 VCSEC_a108_CH_torque "Vehicle security controller: a108 CH torque";
CM_ SG_ 1328 VCSEC_a110_VEH_carState "Vehicle security controller: a110 VEH car state";
CM_ SG_ 1328 VCSEC_a110_VEH_carConfig "Vehicle security controller: a110 VEH car config";
CM_ SG_ 1328 VCSEC_a110_VEH_time "Vehicle security controller: a110 VEH time";
CM_ SG_ 1328 VCSEC_a110_VEH_updateStatus "Vehicle security controller: a110 VEH update status";
CM_ SG_ 1328 VCSEC_a110_VEH_vehNm "Vehicle security controller: a110 VEH veh nm";
CM_ SG_ 1328 VCSEC_a110_VEH_mismatchFault "Vehicle security controller: a110 VEH mismatch fault";
CM_ SG_ 1328 VCSEC_a110_VEH_vin "Vehicle security controller: a110 VEH vin";
CM_ SG_ 1328 VCSEC_a110_VEH_bmpDebug "Vehicle security controller: a110 VEH bmp debug";
CM_ SG_ 1328 VCSEC_a110_VEH_gearControl "Vehicle security controller: a110 VEH gear control";
CM_ SG_ 1328 VCSEC_a110_VEH_canLogAvailabilit "Vehicle security controller: a110 VEH can log availability";
CM_ SG_ 1328 VCSEC_a110_CH_airbagCutoffStatus "Vehicle security controller: a110 CH airbag cutoff status";
CM_ SG_ 1328 VCSEC_a110_CH_carConfig "Vehicle security controller: a110 CH car config";
CM_ SG_ 1328 VCSEC_a110_CH_carState "Vehicle security controller: a110 CH car state";
CM_ SG_ 1328 VCSEC_a110_CH_vin "Vehicle security controller: a110 CH vin";
CM_ SG_ 1328 VCSEC_a110_CH_chNm "Vehicle security controller: a110 CH ch nm";
CM_ SG_ 1328 VCSEC_a110_CH_epochTimeGtw "Vehicle security controller: a110 CH epoch time gtw";
CM_ SG_ 1328 VCSEC_a110_PARTY_carConfig "Vehicle security controller: a110 PARTY car config";
CM_ SG_ 1328 VCSEC_a111_VEH_internalStatus "Vehicle security controller: a111 VEH internal status";
CM_ SG_ 1328 VCSEC_a111_VEH_status "Vehicle security controller: a111 VEH status";
CM_ SG_ 1328 VCSEC_a111_VEH_vehNm "Vehicle security controller: a111 VEH veh nm";
CM_ SG_ 1328 VCSEC_a111_RIPC_LVPowerState "Vehicle security controller: a111 RIPC LV power state";
CM_ SG_ 1328 VCSEC_a111_RIPC_epbPrivateState "Vehicle security controller: a111 RIPC epb private state";
CM_ SG_ 1328 VCSEC_a111_RIPC_railStatus "Vehicle security controller: a111 RIPC rail status";
CM_ SG_ 1328 VCSEC_a111_RIPC_remoteADC "Vehicle security controller: a111 RIPC remote ADC";
CM_ SG_ 1328 VCSEC_a111_RIPC_switchStatus "Vehicle security controller: a111 RIPC switch status";
CM_ SG_ 1328 VCSEC_a111_VEH_LVPowerState "Vehicle security controller: a111 VEH LV power state";
CM_ SG_ 1328 VCSEC_a111_VEH_seatStatus "Vehicle security controller: a111 VEH seat status";
CM_ SG_ 1328 VCSEC_a111_PARTY_status "Vehicle security controller: a111 PARTY status";
CM_ SG_ 1328 VCSEC_a111_CH_status "Vehicle security controller: a111 CH status";
CM_ SG_ 1328 VCSEC_a112_VEH_internalStatus "Vehicle security controller: a112 VEH internal status";
CM_ SG_ 1328 VCSEC_a112_VEH_status "Vehicle security controller: a112 VEH status";
CM_ SG_ 1328 VCSEC_a112_VEH_vehNm "Vehicle security controller: a112 VEH veh nm";
CM_ SG_ 1328 VCSEC_a112_LIPC_LVPowerState "Vehicle security controller: a112 LIPC LV power state";
CM_ SG_ 1328 VCSEC_a112_LIPC_epbPrivateState "Vehicle security controller: a112 LIPC epb private state";
CM_ SG_ 1328 VCSEC_a112_LIPC_railStatus "Vehicle security controller: a112 LIPC rail status";
CM_ SG_ 1328 VCSEC_a112_LIPC_remoteADC "Vehicle security controller: a112 LIPC remote ADC";
CM_ SG_ 1328 VCSEC_a112_LIPC_switchStatus "Vehicle security controller: a112 LIPC switch status";
CM_ SG_ 1328 VCSEC_a112_VEH_LVPowerState "Vehicle security controller: a112 VEH LV power state";
CM_ SG_ 1328 VCSEC_a112_PARTY_status "Vehicle security controller: a112 PARTY status";
CM_ SG_ 1328 VCSEC_a112_CH_status "Vehicle security controller: a112 CH status";
CM_ SG_ 1328 VCSEC_a114_PARTY_status "Vehicle security controller: a114 PARTY status";
CM_ SG_ 1328 VCSEC_a114_PARTY_wheelSpeeds "Vehicle security controller: a114 PARTY wheel speeds";
CM_ SG_ 1328 VCSEC_a114_VEH_wheelSpeeds "Vehicle security controller: a114 VEH wheel speeds";
CM_ SG_ 1328 VCSEC_a114_CH_wheelSpeeds "Vehicle security controller: a114 CH wheel speeds";
CM_ SG_ 1328 VCSEC_a114_PARTY_party3 "Vehicle security controller: a114 PARTY party3";
CM_ SG_ 1328 VCSEC_a114_VEH_party3 "Vehicle security controller: a114 VEH party3";
CM_ SG_ 1328 VCSEC_a114_VEH_status "Vehicle security controller: a114 VEH status";
CM_ SG_ 1328 VCSEC_a114_PARTY_wheelRotation "Vehicle security controller: a114 PARTY wheel rotation";
CM_ SG_ 1328 VCSEC_a114_CH_wheelRotation "Vehicle security controller: a114 CH wheel rotation";
CM_ SG_ 1328 VCSEC_a114_VEH_wheelRotation "Vehicle security controller: a114 VEH wheel rotation";
CM_ SG_ 1328 VCSEC_a114_PARTY_brakeTorque "Vehicle security controller: a114 PARTY brake torque";
CM_ SG_ 1328 VCSEC_a114_PARTY_offsets "Vehicle security controller: a114 PARTY offsets";
CM_ SG_ 1328 VCSEC_a114_BDY_offsets "Vehicle security controller: a114 BDY offsets";
CM_ SG_ 1328 VCSEC_a114_BDY_party3 "Vehicle security controller: a114 BDY party3";
CM_ SG_ 1328 VCSEC_a114_BDY_status "Vehicle security controller: a114 BDY status";
CM_ SG_ 1328 VCSEC_a114_BDY_wheelRotation "Vehicle security controller: a114 BDY wheel rotation";
CM_ SG_ 1328 VCSEC_a114_BDY_wheelSpeeds "Vehicle security controller: a114 BDY wheel speeds";
CM_ SG_ 1328 VCSEC_a114_CH_party1 "Vehicle security controller: a114 CH party1";
CM_ SG_ 1328 VCSEC_a114_CH_party3 "Vehicle security controller: a114 CH party3";
CM_ SG_ 1328 VCSEC_a114_CH_status "Vehicle security controller: a114 CH status";
CM_ SG_ 1328 VCSEC_a115_VEH_vehNm "Vehicle security controller: a115 VEH veh nm";
CM_ SG_ 1328 VCSEC_a115_VEH_authentication "Vehicle security controller: a115 VEH authentication";
CM_ SG_ 1328 VCSEC_a115_VEH_BLEResetRequest "Vehicle security controller: a115 VEH BLE reset request";
CM_ SG_ 1328 VCSEC_a115_VEH_requests "Vehicle security controller: a115 VEH requests";
CM_ SG_ 1328 VCSEC_a115_VEH_requests2 "Vehicle security controller: a115 VEH requests2";
CM_ SG_ 1328 VCSEC_a115_REM_authentication "Vehicle security controller: a115 REM authentication";
CM_ SG_ 1328 VCSEC_a115_UI_corianderVehicleCo "Vehicle security controller: a115 UI coriander vehicle control";
CM_ SG_ 1328 VCSEC_a115_CH_TPMSDisplay "Vehicle security controller: a115 CH TPMS display";
CM_ SG_ 1328 VCSEC_a116_PARTY_epbmStatus "Vehicle security controller: a116 PARTY epbm status";
CM_ SG_ 1328 VCSEC_a116_VEH_vehNm "Vehicle security controller: a116 VEH veh nm";
CM_ SG_ 1328 VCSEC_a116_VEH_hvacRequest "Vehicle security controller: a116 VEH hvac request";
CM_ SG_ 1328 VCSEC_a116_VEH_hvacStatus "Vehicle security controller: a116 VEH hvac status";
CM_ SG_ 1328 VCSEC_a116_VEH_LVPowerState "Vehicle security controller: a116 VEH LV power state";
CM_ SG_ 1328 VCSEC_a116_VEH_lightStatus "Vehicle security controller: a116 VEH light status";
CM_ SG_ 1328 VCSEC_a116_VEH_seatStatus "Vehicle security controller: a116 VEH seat status";
CM_ SG_ 1328 VCSEC_a116_VEH_thsStatus "Vehicle security controller: a116 VEH ths status";
CM_ SG_ 1328 VCSEC_a116_VEH_doorStatus "Vehicle security controller: a116 VEH door status";
CM_ SG_ 1328 VCSEC_a116_VEH_seatHeatStatus "Vehicle security controller: a116 VEH seat heat status";
CM_ SG_ 1328 VCSEC_a116_VEH_restraintStatus "Vehicle security controller: a116 VEH restraint status";
CM_ SG_ 1328 VCSEC_a116_VEH_switchStatus "Vehicle security controller: a116 VEH switch status";
CM_ SG_ 1328 VCSEC_a116_VEH_logging1Hz "Vehicle security controller: a116 VEH logging1 hz";
CM_ SG_ 1328 VCSEC_a116_VEH_seatStatus2 "Vehicle security controller: a116 VEH seat status2";
CM_ SG_ 1328 VCSEC_a116_VEH_status "Vehicle security controller: a116 VEH status";
CM_ SG_ 1328 VCSEC_a116_VEH_thermalCommand "Vehicle security controller: a116 VEH thermal command";
CM_ SG_ 1328 VCSEC_a116_VEH_windowStatus "Vehicle security controller: a116 VEH window status";
CM_ SG_ 1328 VCSEC_a116_PARTY_restraintStatus "Vehicle security controller: a116 PARTY restraint status";
CM_ SG_ 1328 VCSEC_a116_PARTY_doorStatus "Vehicle security controller: a116 PARTY door status";
CM_ SG_ 1328 VCSEC_a116_BDY_epbmStatus "Vehicle security controller: a116 BDY epbm status";
CM_ SG_ 1328 VCSEC_a116_BDY_restraintStatus "Vehicle security controller: a116 BDY restraint status";
CM_ SG_ 1328 VCSEC_a116_BDY_switchStatus "Vehicle security controller: a116 BDY switch status";
CM_ SG_ 1328 VCSEC_a117_BDY_epbmStatus "Vehicle security controller: a117 BDY epbm status";
CM_ SG_ 1328 VCSEC_a117_BDY_restraintStatus "Vehicle security controller: a117 BDY restraint status";
CM_ SG_ 1328 VCSEC_a117_VEH_prndStatus "Vehicle security controller: a117 VEH prnd status";
CM_ SG_ 1328 VCSEC_a117_PARTY_epbmStatus "Vehicle security controller: a117 PARTY epbm status";
CM_ SG_ 1328 VCSEC_a117_VEH_vehNm "Vehicle security controller: a117 VEH veh nm";
CM_ SG_ 1328 VCSEC_a117_VEH_hvacBlowerFdb "Vehicle security controller: a117 VEH hvac blower fdb";
CM_ SG_ 1328 VCSEC_a117_VEH_LVPowerState "Vehicle security controller: a117 VEH LV power state";
CM_ SG_ 1328 VCSEC_a117_VEH_restraintStatus "Vehicle security controller: a117 VEH restraint status";
CM_ SG_ 1328 VCSEC_a117_VEH_lightStatus "Vehicle security controller: a117 VEH light status";
CM_ SG_ 1328 VCSEC_a117_VEH_seatStatus "Vehicle security controller: a117 VEH seat status";
CM_ SG_ 1328 VCSEC_a117_BDY_falconSwitchStatu "Vehicle security controller: a117 BDY falcon switch status";
CM_ SG_ 1328 VCSEC_a117_VEH_doorStatus "Vehicle security controller: a117 VEH door status";
CM_ SG_ 1328 VCSEC_a117_VEH_doorStatus2 "Vehicle security controller: a117 VEH door status2";
CM_ SG_ 1328 VCSEC_a117_VEH_windowStatus "Vehicle security controller: a117 VEH window status";
CM_ SG_ 1328 VCSEC_a117_VEH_switchStatus "Vehicle security controller: a117 VEH switch status";
CM_ SG_ 1328 VCSEC_a117_VEH_intrusionSensorSt "Vehicle security controller: a117 VEH intrusion sensor status";
CM_ SG_ 1328 VCSEC_a117_VEH_liftgateStatus "Vehicle security controller: a117 VEH liftgate status";
CM_ SG_ 1328 VCSEC_a117_VEH_seatStatus2 "Vehicle security controller: a117 VEH seat status2";
CM_ SG_ 1328 VCSEC_a117_PARTY_restraintStatus "Vehicle security controller: a117 PARTY restraint status";
CM_ SG_ 1328 VCSEC_a117_VEH_thermalStatus "Vehicle security controller: a117 VEH thermal status";
CM_ SG_ 1328 VCSEC_a117_PARTY_doorStatus "Vehicle security controller: a117 PARTY door status";
CM_ SG_ 1328 VCSEC_a117_VEH_status "Vehicle security controller: a117 VEH status";
CM_ SG_ 1328 VCSEC_a117_PARTY_prndStatus "Vehicle security controller: a117 PARTY prnd status";
CM_ SG_ 1328 VCSEC_a117_PARTY_lightingSeconda "Vehicle security controller: a117 PARTY lighting secondary";
CM_ SG_ 1328 VCSEC_a118_VEH_vehNm "Vehicle security controller: a118 VEH veh nm";
CM_ SG_ 1328 VCSEC_a118_VEH_lighting "Vehicle security controller: a118 VEH lighting";
CM_ SG_ 1328 VCSEC_a118_VEH_sensors "Vehicle security controller: a118 VEH sensors";
CM_ SG_ 1328 VCSEC_a118_VEH_status "Vehicle security controller: a118 VEH status";
CM_ SG_ 1328 VCSEC_a118_VEH_okToUseHighPwr "Vehicle security controller: a118 VEH ok to use high pwr";
CM_ SG_ 1328 VCSEC_a118_VEH_LVPowerState "Vehicle security controller: a118 VEH LV power state";
CM_ SG_ 1328 VCSEC_a118_VEH_coolant "Vehicle security controller: a118 VEH coolant";
CM_ SG_ 1328 VCSEC_a118_VEH_vehicleStatus "Vehicle security controller: a118 VEH vehicle status";
CM_ SG_ 1328 VCSEC_a118_VEH_12VBatteryStatus "Vehicle security controller: a118 VEH 12 v battery status";
CM_ SG_ 1328 VCSEC_a118_VEH_systemStatus "Vehicle security controller: a118 VEH system status";
CM_ SG_ 1328 VCSEC_a118_PARTY_LVPowerState "Vehicle security controller: a118 PARTY LV power state";
CM_ SG_ 1328 VCSEC_a118_PARTY_outputPowerStat "Vehicle security controller: a118 PARTY output power status";
CM_ SG_ 1328 VCSEC_a118_PARTY_vehicleTime "Vehicle security controller: a118 PARTY vehicle time";
CM_ SG_ 1328 VCSEC_a118_VEH_thermalCommand "Vehicle security controller: a118 VEH thermal command";
CM_ SG_ 1328 VCSEC_a118_CH_LVPowerState "Vehicle security controller: a118 CH LV power state";
CM_ SG_ 1328 VCSEC_a118_PARTY_sensors "Vehicle security controller: a118 PARTY sensors";
CM_ SG_ 1328 VCSEC_a118_CH_sensors "Vehicle security controller: a118 CH sensors";
CM_ SG_ 1328 VCSEC_a118_VEH_interNodeResistan "Vehicle security controller: a118 VEH inter node resistance";
CM_ SG_ 1328 VCSEC_a118_CH_lighting "Vehicle security controller: a118 CH lighting";
CM_ SG_ 1328 VCSEC_a118_VEH_lightStatus "Vehicle security controller: a118 VEH light status";
CM_ SG_ 1328 VCSEC_a118_PARTY_vehNm "Vehicle security controller: a118 PARTY veh nm";
CM_ SG_ 1328 VCSEC_a118_CH_12VBatteryStatus "Vehicle security controller: a118 CH 12 v battery status";
CM_ SG_ 1328 VCSEC_a118_CH_LVBMS_statusHigh "Vehicle security controller: a118 CH LVBMS status high";
CM_ SG_ 1328 VCSEC_a118_CH_alertMatrix "Vehicle security controller: a118 CH alert matrix";
CM_ SG_ 1328 VCSEC_a118_BDY_outputPowerStatus "Vehicle security controller: a118 BDY output power status";
CM_ SG_ 1328 VCSEC_a118_BDY_vehicleTime "Vehicle security controller: a118 BDY vehicle time";
CM_ SG_ 1328 VCSEC_a118_PARTY_AP_vehicleState "Vehicle security controller: a118 PARTY AP vehicle state1 hz muxed";
CM_ SG_ 1328 VCSEC_a118_BDY_AP_vehicleState1H "Vehicle security controller: a118 BDY AP vehicle state1 hz muxed";
CM_ SG_ 1328 VCSEC_a118_PARTY_VCFRONT_cameraC "Vehicle security controller: a118 PARTY VCFRONT camera cleaning status";
CM_ SG_ 1328 VCSEC_a119_VEH_steerAngle "Vehicle security controller: a119 VEH steer angle";
CM_ SG_ 1328 VCSEC_a119_VEH_leftStalk "Vehicle security controller: a119 VEH left stalk";
CM_ SG_ 1328 VCSEC_a119_VEH_rightStalk "Vehicle security controller: a119 VEH right stalk";
CM_ SG_ 1328 VCSEC_a119_PARTY_rightStalk "Vehicle security controller: a119 PARTY right stalk";
CM_ SG_ 1328 VCSEC_a119_CH_steerAngle "Vehicle security controller: a119 CH steer angle";
CM_ SG_ 1328 VCSEC_a119_PARTY_steerAngle "Vehicle security controller: a119 PARTY steer angle";
CM_ SG_ 1328 VCSEC_a120_PARTY_chassisCntl "Vehicle security controller: a120 PARTY chassis cntl";
CM_ SG_ 1328 VCSEC_a120_VEH_systemStatus "Vehicle security controller: a120 VEH system status";
CM_ SG_ 1328 VCSEC_a120_CH_chassisCntl "Vehicle security controller: a120 CH chassis cntl";
CM_ SG_ 1328 VCSEC_a120_PARTY_systemStatus "Vehicle security controller: a120 PARTY system status";
CM_ SG_ 1328 VCSEC_a120_PARTY_torque "Vehicle security controller: a120 PARTY torque";
CM_ SG_ 1328 VCSEC_a120_VEH_torque "Vehicle security controller: a120 VEH torque";
CM_ SG_ 1328 VCSEC_a120_PARTY_locStatus "Vehicle security controller: a120 PARTY loc status";
CM_ SG_ 1328 VCSEC_a120_PARTY_speed "Vehicle security controller: a120 PARTY speed";
CM_ SG_ 1328 VCSEC_a120_VEH_speed "Vehicle security controller: a120 VEH speed";
CM_ SG_ 1328 VCSEC_a120_PARTY_status "Vehicle security controller: a120 PARTY status";
CM_ SG_ 1328 VCSEC_a120_PT_speed "Vehicle security controller: a120 PT speed";
CM_ SG_ 1328 VCSEC_a120_PT_systemStatus "Vehicle security controller: a120 PT system status";
CM_ SG_ 1328 VCSEC_a120_PARTY_vehicleEstimate "Vehicle security controller: a120 PARTY vehicle estimates";
CM_ SG_ 1328 VCSEC_a120_VEH_aggregatedAxleSpe "Vehicle security controller: a120 VEH aggregated axle speed";
CM_ SG_ 1328 VCSEC_a120_PARTY_aggregatedAxleS "Vehicle security controller: a120 PARTY aggregated axle speed";
CM_ SG_ 1328 VCSEC_a120_VEH_systemPower "Vehicle security controller: a120 VEH system power";
CM_ SG_ 1328 VCSEC_a120_PARTY_autonomyHealth "Vehicle security controller: a120 PARTY autonomy health";
CM_ SG_ 1328 VCSEC_a120_VEH_autonomyHealth "Vehicle security controller: a120 VEH autonomy health";
CM_ SG_ 1328 VCSEC_a120_PT_systemPower "Vehicle security controller: a120 PT system power";
CM_ SG_ 1328 VCSEC_a120_PARTY_stalklessInterf "Vehicle security controller: a120 PARTY stalkless interfaces";
CM_ SG_ 1328 VCSEC_a120_CH_speed "Vehicle security controller: a120 CH speed";
CM_ SG_ 1328 VCSEC_a120_VEH_estimatedBrakeTem "Vehicle security controller: a120 VEH estimated brake temp";
CM_ SG_ 1328 VCSEC_a120_PARTY_prndControl "Vehicle security controller: a120 PARTY prnd control";
CM_ SG_ 1328 VCSEC_a120_PARTY_locStatus2 "Vehicle security controller: a120 PARTY loc status2";
CM_ SG_ 1328 VCSEC_a120_VEH_chassisCntl "Vehicle security controller: a120 VEH chassis cntl";
CM_ SG_ 1328 VCSEC_a120_CH_locStatus2 "Vehicle security controller: a120 CH loc status2";
CM_ SG_ 1328 VCSEC_a120_VEH_locStatus "Vehicle security controller: a120 VEH loc status";
CM_ SG_ 1328 VCSEC_a120_VEH_locStatus2 "Vehicle security controller: a120 VEH loc status2";
CM_ SG_ 1328 VCSEC_a120_VEH_prndControl "Vehicle security controller: a120 VEH prnd control";
CM_ SG_ 1328 VCSEC_a120_VEH_vehicleEstimates "Vehicle security controller: a120 VEH vehicle estimates";
CM_ SG_ 1328 VCSEC_a120_PARTY_motorStatus "Vehicle security controller: a120 PARTY motor status";
CM_ SG_ 1328 VCSEC_a120_VEH_motorStatus "Vehicle security controller: a120 VEH motor status";
CM_ SG_ 1328 VCSEC_a120_BDY_speed "Vehicle security controller: a120 BDY speed";
CM_ SG_ 1328 VCSEC_a121_VEH_status "Vehicle security controller: a121 VEH status";
CM_ SG_ 1328 VCSEC_a121_VEH_occupancy "Vehicle security controller: a121 VEH occupancy";
CM_ SG_ 1328 VCSEC_a133_alarmTriggerReason "Vehicle security controller: a133 alarm trigger reason";
CM_ SG_ 1328 VCSEC_a140_keyDidNotIdentify "Vehicle security controller: a140 key did not identify";
CM_ SG_ 1328 VCSEC_a140_keyNotPairedToTheCar "Vehicle security controller: a140 key not paired to the car";
CM_ SG_ 1328 VCSEC_a140_authenticationFailed "Vehicle security controller: a140 authentication failed";
CM_ SG_ 1328 VCSEC_a140_authenticationTimeout "Vehicle security controller: a140 authentication timeout";
CM_ SG_ 1328 VCSEC_a140_cardRmvdB4AuthComplet "Vehicle security controller: a140 card rmvd B4 auth complete";
CM_ SG_ 1328 VCSEC_a140_cardRmvdB4SndingChaln "Vehicle security controller: a140 card rmvd B4 snding chalng";
CM_ SG_ 1328 VCSEC_a140_cardRmvdB4SndingReqID "Vehicle security controller: a140 card rmvd B4 snding req ID";
CM_ SG_ 1328 VCSEC_a140_cardRmvdB4RecvingID "Vehicle security controller: a140 card rmvd B4 recving ID";
CM_ SG_ 1328 VCSEC_a140_multipleTriesToAuth "Vehicle security controller: a140 multiple tries to auth";
CM_ SG_ 1328 VCSEC_a177_newWhitelistSlot "Vehicle security controller: a177 new whitelist slot";
CM_ SG_ 1328 VCSEC_a177_signingKeySlot "Vehicle security controller: a177 signing key slot";
CM_ SG_ 1328 VCSEC_a177_newKeyPublicKey "Vehicle security controller: a177 new key public key";
CM_ SG_ 1328 VCSEC_a177_keyActiveTime "Vehicle security controller: a177 key active time";
CM_ SG_ 1328 VCSEC_a177_keyRole "Vehicle security controller: a177 key role";
CM_ SG_ 1328 VCSEC_a178_publicKey "Vehicle security controller: a178 public key";
CM_ SG_ 1328 VCSEC_a178_signingKeySlot "Vehicle security controller: a178 signing key slot";
CM_ SG_ 1328 VCSEC_a178_removedKeySlot "Vehicle security controller: a178 removed key slot";
CM_ SG_ 1328 VCSEC_a178_removedKeyRole "Vehicle security controller: a178 removed key role";
CM_ SG_ 1328 VCSEC_a191_clearWlist "Vehicle security controller: a191 clear wlist";
CM_ SG_ 1328 VCSEC_a191_WlistingDevice "Vehicle security controller: a191 wlisting device";
CM_ SG_ 1328 VCSEC_a191_failedToSendWlist "Vehicle security controller: a191 failed to send wlist";
CM_ SG_ 1328 VCSEC_a192_clearWlist "Vehicle security controller: a192 clear wlist";
CM_ SG_ 1328 VCSEC_a192_WlistingDevice "Vehicle security controller: a192 wlisting device";
CM_ SG_ 1328 VCSEC_a192_failedToSendWlist "Vehicle security controller: a192 failed to send wlist";
CM_ SG_ 1328 VCSEC_a193_clearWlist "Vehicle security controller: a193 clear wlist";
CM_ SG_ 1328 VCSEC_a193_WlistingDevice "Vehicle security controller: a193 wlisting device";
CM_ SG_ 1328 VCSEC_a193_failedToSendWlist "Vehicle security controller: a193 failed to send wlist";
CM_ SG_ 1328 VCSEC_a194_clearWlist "Vehicle security controller: a194 clear wlist";
CM_ SG_ 1328 VCSEC_a194_WlistingDevice "Vehicle security controller: a194 wlisting device";
CM_ SG_ 1328 VCSEC_a194_failedToSendWlist "Vehicle security controller: a194 failed to send wlist";
CM_ SG_ 1328 VCSEC_a197_connectionChannel "Vehicle security controller: a197 connection channel";
CM_ SG_ 1328 VCSEC_a197_connHandleMismatch "Vehicle security controller: a197 conn handle mismatch";
CM_ SG_ 1328 VCSEC_a197_confrmtnTimeout "Vehicle security controller: a197 confrmtn timeout";
CM_ SG_ 1328 VCSEC_a197_errorInconfrmtn "Vehicle security controller: a197 error inconfrmtn";
CM_ SG_ 1328 VCSEC_a210_whiteListChannel "Vehicle security controller: a210 white list channel";
CM_ SG_ 1328 VCSEC_a211_handlePulled "Vehicle security controller: a211 handle pulled";
CM_ SG_ 1328 VCSEC_a211_connectionCount "Vehicle security controller: a211 connection count";
CM_ SG_ 1328 VCSEC_a211_RSSIValidMatrix "Vehicle security controller: a211 RSSI valid matrix";
CM_ SG_ 1328 VCSEC_a211_DevicePresentCount "Vehicle security controller: a211 device present count";
CM_ SG_ 1328 VCSEC_a211_UnknownDevicePresent "Vehicle security controller: a211 unknown device present";
CM_ SG_ 1328 VCSEC_a211_AuthRequested "Vehicle security controller: a211 auth requested";
CM_ SG_ 1328 VCSEC_a211_MaximumRSSI "Vehicle security controller: a211 maximum RSSI";
CM_ SG_ 1328 VCSEC_a211_MaximumRSSIAntenna "Vehicle security controller: a211 maximum RSSI antenna";
CM_ SG_ 1328 VCSEC_a211_riderKeyConnected "Vehicle security controller: a211 rider key connected";
CM_ SG_ 1328 VCSEC_a211_FleetModeActive "Vehicle security controller: a211 fleet mode active";
CM_ SG_ 1328 VCSEC_a219_pairingRemovedSensor0 "Vehicle security controller: a219 pairing removed sensor0";
CM_ SG_ 1328 VCSEC_a219_pairingRemovedSensor1 "Vehicle security controller: a219 pairing removed sensor1";
CM_ SG_ 1328 VCSEC_a219_pairingRemovedSensor2 "Vehicle security controller: a219 pairing removed sensor2";
CM_ SG_ 1328 VCSEC_a219_pairingRemovedSensor3 "Vehicle security controller: a219 pairing removed sensor3";
CM_ SG_ 1328 VCSEC_a221_countryCode "Vehicle security controller: a221 country code";
CM_ SG_ 1328 VCSEC_a221_homologationRegion "Vehicle security controller: a221 homologation region";
CM_ SG_ 1328 VCSEC_a256_whitelistOperation "Vehicle security controller: a256 whitelist operation";
CM_ SG_ 1328 VCSEC_a256_failureReason "Vehicle security controller: a256 failure reason";
CM_ SG_ 1328 VCSEC_a256_whitelistSlot "Vehicle security controller: a256 whitelist slot";
CM_ SG_ 1328 VCSEC_a256_signingKeySlot "Vehicle security controller: a256 signing key slot";
CM_ SG_ 1328 VCSEC_a256_keyActiveTime "Vehicle security controller: a256 key active time";
CM_ SG_ 1328 VCSEC_a257_whitelistSlot "Vehicle security controller: a257 whitelist slot";
CM_ SG_ 1328 VCSEC_a257_keyID "Vehicle security controller: a257 key ID";
CM_ SG_ 1328 VCSEC_a257_keyActiveTime "Vehicle security controller: a257 key active time";
CM_ SG_ 1328 VCSEC_a257_permissionActiveTime "Vehicle security controller: a257 permission active time";
CM_ SG_ 1328 VCSEC_a266_pressure "Vehicle security controller: a266 pressure";
CM_ SG_ 1328 VCSEC_a267_pressure "Vehicle security controller: a267 pressure";
CM_ SG_ 1328 VCSEC_a268_pressure "Vehicle security controller: a268 pressure";
CM_ SG_ 1328 VCSEC_a269_pressure "Vehicle security controller: a269 pressure";
CM_ SG_ 1328 VCSEC_a270_pressure "Vehicle security controller: a270 pressure";
CM_ SG_ 1328 VCSEC_a271_pressure "Vehicle security controller: a271 pressure";
CM_ SG_ 1328 VCSEC_a272_pressure "Vehicle security controller: a272 pressure";
CM_ SG_ 1328 VCSEC_a273_pressure "Vehicle security controller: a273 pressure";
CM_ SG_ 1328 VCSEC_a311_whitelistChannel "Vehicle security controller: a311 whitelist channel";
CM_ SG_ 1328 VCSEC_a436_currentUHFHardware "Vehicle security controller: a436 current UHF hardware";
CM_ SG_ 1328 VCSEC_a436_expectedUHFHardware "Vehicle security controller: a436 expected UHF hardware";
CM_ SG_ 1328 VCSEC_a436_countryCode "Vehicle security controller: a436 country code";
CM_ SG_ 1328 VCSEC_a455_pressure "Vehicle security controller: a455 pressure";
CM_ SG_ 1328 VCSEC_a456_pressure "Vehicle security controller: a456 pressure";
CM_ SG_ 1328 VCSEC_a457_pressure "Vehicle security controller: a457 pressure";
CM_ SG_ 1328 VCSEC_a458_pressure "Vehicle security controller: a458 pressure";
CM_ SG_ 1328 VCSEC_a497_centerEndpointMismatc "Vehicle security controller: a497 center endpoint mismatch";
CM_ SG_ 1328 VCSEC_a497_cradleEndpointMismatc "Vehicle security controller: a497 cradle endpoint mismatch";
CM_ SG_ 1328 VCSEC_a497_leftEndpointMismatch "Vehicle security controller: a497 left endpoint mismatch";
CM_ SG_ 1328 VCSEC_a497_rightEndpointMismatch "Vehicle security controller: a497 right endpoint mismatch";
CM_ SG_ 1328 VCSEC_a497_rearLeftEndpointMisma "Vehicle security controller: a497 rear left endpoint mismatch";
CM_ SG_ 1328 VCSEC_a497_rearRightEndpointMism "Vehicle security controller: a497 rear right endpoint mismatch";
CM_ SG_ 1328 VCSEC_a497_endpointLocationToFix "Vehicle security controller: a497 endpoint location to fix";
CM_ SG_ 1328 VCSEC_a497_endpointExpectedPcbaI "Vehicle security controller: a497 endpoint expected pcba id";
CM_ SG_ 1328 VCSEC_a497_endpointExpectedAssem "Vehicle security controller: a497 endpoint expected assembly id";
CM_ SG_ 1328 VCSEC_a497_endpointExpectedUsage "Vehicle security controller: a497 endpoint expected usage id";
CM_ SG_ 1328 VCSEC_a497_endpointActualPcbaId "Vehicle security controller: a497 endpoint actual pcba id";
CM_ SG_ 1328 VCSEC_a497_endpointActualAssembl "Vehicle security controller: a497 endpoint actual assembly id";
CM_ SG_ 1328 VCSEC_a497_endpointActualUsageId "Vehicle security controller: a497 endpoint actual usage id";
CM_ SG_ 1328 VCSEC_a504_ecuUnprovisioned "Vehicle security controller: a504 ecu unprovisioned";
CM_ SG_ 1328 VCSEC_a505_excessiveMacFailures "Vehicle security controller: a505 excessive mac failures";
CM_ SG_ 1328 VCSEC_a517_pressure "Vehicle security controller: a517 pressure";
CM_ SG_ 1328 VCSEC_a518_pressure "Vehicle security controller: a518 pressure";
CM_ SG_ 1328 VCSEC_a519_pressure "Vehicle security controller: a519 pressure";
CM_ SG_ 1328 VCSEC_a520_pressure "Vehicle security controller: a520 pressure";
CM_ BO_ 1017 "Vehicle security controller message: alert matrix";
CM_ SG_ 1017 VCSEC_matrixIndex "Vehicle security controller: matrix index";
CM_ SG_ 1017 VCSEC_a001_WatchdogReset "Vehicle security controller: a001 watchdog reset";
CM_ SG_ 1017 VCSEC_a002_PowerLossReset "Vehicle security controller: a002 power loss reset";
CM_ SG_ 1017 VCSEC_a003_SWAssertion "Vehicle security controller: a003 SW assertion";
CM_ SG_ 1017 VCSEC_a005_CANTXError "Vehicle security controller: a005 CANTX error";
CM_ SG_ 1017 VCSEC_a006_CANTX_cyclicError "Vehicle security controller: a006 CANTX cyclic error";
CM_ SG_ 1017 VCSEC_a010_ExtSupplyVoltError "Vehicle security controller: a010 ext supply volt error";
CM_ SG_ 1017 VCSEC_a012_CPUReset "Vehicle security controller: a012 CPU reset";
CM_ SG_ 1017 VCSEC_a013_AlertManagerFault "Vehicle security controller: a013 alert manager fault";
CM_ SG_ 1017 VCSEC_a015_NVMMError "Vehicle security controller: a015 NVMM error";
CM_ SG_ 1017 VCSEC_a016_NVMMRecordError "Vehicle security controller: a016 NVMM record error";
CM_ SG_ 1017 VCSEC_a017_NVMMStatusDbg "Vehicle security controller: a017 NVMM status dbg";
CM_ SG_ 1017 VCSEC_a021_TaskSchedulerError "Vehicle security controller: a021 task scheduler error";
CM_ SG_ 1017 VCSEC_a022_TaskInitError "Vehicle security controller: a022 task init error";
CM_ SG_ 1017 VCSEC_a029_CoreDump "Vehicle security controller: a029 core dump";
CM_ SG_ 1017 VCSEC_a030_ECULogUploadRequest "Vehicle security controller: a030 ECU log upload request";
CM_ SG_ 1017 VCSEC_a031_UDSActive "Vehicle security controller: a031 UDS active";
CM_ SG_ 1017 VCSEC_a041_HighCPULoad "Vehicle security controller: a041 high CPU load";
CM_ SG_ 1017 VCSEC_a042_HighStackUsage "Vehicle security controller: a042 high stack usage";
CM_ SG_ 1017 VCSEC_a043_Task1msError "Vehicle security controller: a043 task1ms error";
CM_ SG_ 1017 VCSEC_a044_Task10msError "Vehicle security controller: a044 task10ms error";
CM_ SG_ 1017 VCSEC_a045_Task100msError "Vehicle security controller: a045 task100ms error";
CM_ SG_ 1017 VCSEC_a046_Task1000msError "Vehicle security controller: a046 task1000ms error";
CM_ SG_ 1017 VCSEC_a057_HVP_MIA "Vehicle security controller: a057 HVP MIA";
CM_ SG_ 1017 VCSEC_a058_inputRHighSyncDebug "Vehicle security controller: a058 input r high sync debug";
CM_ SG_ 1017 VCSEC_a059_inputResistanceHigh "Vehicle security controller: a059 input resistance high";
CM_ SG_ 1017 VCSEC_a060_engineeringBuild "Vehicle security controller: a060 engineering build";
CM_ SG_ 1017 VCSEC_a061_XCPConnected "Vehicle security controller: a061 XCP connected";
CM_ SG_ 1017 VCSEC_a062_XCPWasConnected "Vehicle security controller: a062 XCP was connected";
CM_ SG_ 1017 VCSEC_a063_SwitchFault "Vehicle security controller: a063 switch fault";
CM_ SG_ 1017 VCSEC_a064_busSleepReqTimeout "Vehicle security controller: a064 bus sleep req timeout";
CM_ SG_ 1017 VCSEC_a082_VCRIGHT_IPC_MIA "Vehicle security controller: a082 VCRIGHT IPC MIA";
CM_ SG_ 1017 VCSEC_a083_VCLEFT_IPC_MIA "Vehicle security controller: a083 VCLEFT IPC MIA";
CM_ SG_ 1017 VCSEC_a084_TPMS_MIA "Vehicle security controller: a084 TPMS MIA";
CM_ SG_ 1017 VCSEC_a085_CCCM_MIA "Vehicle security controller: a085 CCCM MIA";
CM_ SG_ 1017 VCSEC_a086_VCBATT_MIA "Vehicle security controller: a086 VCBATT MIA";
CM_ SG_ 1017 VCSEC_a087_DIREL_MIA "Vehicle security controller: a087 DIREL MIA";
CM_ SG_ 1017 VCSEC_a088_DIRER_MIA "Vehicle security controller: a088 DIRER MIA";
CM_ SG_ 1017 VCSEC_a089_IBST_MIA "Vehicle security controller: a089 IBST MIA";
CM_ SG_ 1017 VCSEC_a090_APS_MIA "Vehicle security controller: a090 APS MIA";
CM_ SG_ 1017 VCSEC_a091_CMPD_MIA "Vehicle security controller: a091 CMPD MIA";
CM_ SG_ 1017 VCSEC_a092_VCSEATD_MIA "Vehicle security controller: a092 VCSEATD MIA";
CM_ SG_ 1017 VCSEC_a093_VCSEATP_MIA "Vehicle security controller: a093 VCSEATP MIA";
CM_ SG_ 1017 VCSEC_a094_EPAS3P_MIA "Vehicle security controller: a094 EPAS3 p MIA";
CM_ SG_ 1017 VCSEC_a095_CHG_MIA "Vehicle security controller: a095 CHG MIA";
CM_ SG_ 1017 VCSEC_a096_OCS1P_MIA "Vehicle security controller: a096 OCS1 p MIA";
CM_ SG_ 1017 VCSEC_a097_CMP_MIA "Vehicle security controller: a097 CMP MIA";
CM_ SG_ 1017 VCSEC_a098_DIR_MIA "Vehicle security controller: a098 DIR MIA";
CM_ SG_ 1017 VCSEC_a099_PARK_MIA "Vehicle security controller: a099 PARK MIA";
CM_ SG_ 1017 VCSEC_a100_CANbus_MIA "Vehicle security controller: a100 CA nbus MIA";
CM_ SG_ 1017 VCSEC_a101_PM_MIA "Vehicle security controller: a101 PM MIA";
CM_ SG_ 1017 VCSEC_a102_PTC_MIA "Vehicle security controller: a102 PTC MIA";
CM_ SG_ 1017 VCSEC_a103_CP_MIA "Vehicle security controller: a103 CP MIA";
CM_ SG_ 1017 VCSEC_a104_DAS_MIA "Vehicle security controller: a104 DAS MIA";
CM_ SG_ 1017 VCSEC_a105_TAS_MIA "Vehicle security controller: a105 TAS MIA";
CM_ SG_ 1017 VCSEC_a106_PCS_MIA "Vehicle security controller: a106 PCS MIA";
CM_ SG_ 1017 VCSEC_a107_BMS_MIA "Vehicle security controller: a107 BMS MIA";
CM_ SG_ 1017 VCSEC_a108_DIF_MIA "Vehicle security controller: a108 DIF MIA";
CM_ SG_ 1017 VCSEC_a109_RCM_MIA "Vehicle security controller: a109 RCM MIA";
CM_ SG_ 1017 VCSEC_a110_GTW_MIA "Vehicle security controller: a110 GTW MIA";
CM_ SG_ 1017 VCSEC_a111_EPBR_MIA "Vehicle security controller: a111 EPBR MIA";
CM_ SG_ 1017 VCSEC_a112_EPBL_MIA "Vehicle security controller: a112 EPBL MIA";
CM_ SG_ 1017 VCSEC_a113_UI_MIA "Vehicle security controller: a113 UI MIA";
CM_ SG_ 1017 VCSEC_a114_ESP_MIA "Vehicle security controller: a114 ESP MIA";
CM_ SG_ 1017 VCSEC_a115_VCSEC_MIA "Vehicle security controller: a115 VCSEC MIA";
CM_ SG_ 1017 VCSEC_a116_VCRIGHT_MIA "Vehicle security controller: a116 VCRIGHT MIA";
CM_ SG_ 1017 VCSEC_a117_VCLEFT_MIA "Vehicle security controller: a117 VCLEFT MIA";
CM_ SG_ 1017 VCSEC_a118_VCFRONT_MIA "Vehicle security controller: a118 VCFRONT MIA";
CM_ SG_ 1017 VCSEC_a119_SCCM_MIA "Vehicle security controller: a119 SCCM MIA";
CM_ SG_ 1017 VCSEC_a120_DI_DRIVE_MIA "Vehicle security controller: a120 DI DRIVE MIA";
CM_ SG_ 1017 VCSEC_a121_ICR_MIA "Vehicle security controller: a121 ICR MIA";
CM_ SG_ 1017 VCSEC_a133_alarmTriggered "Vehicle security controller: a133 alarm triggered";
CM_ SG_ 1017 VCSEC_a134_noVINLoaded "Vehicle security controller: a134 no VIN loaded";
CM_ SG_ 1017 VCSEC_a135_centerEndpointBusy "Vehicle security controller: a135 center endpoint busy";
CM_ SG_ 1017 VCSEC_a136_leftEndpointBusy "Vehicle security controller: a136 left endpoint busy";
CM_ SG_ 1017 VCSEC_a137_rightEndpointBusy "Vehicle security controller: a137 right endpoint busy";
CM_ SG_ 1017 VCSEC_a138_rearEndpointBusy "Vehicle security controller: a138 rear endpoint busy";
CM_ SG_ 1017 VCSEC_a140_nfcAuthentication "Vehicle security controller: a140 nfc authentication";
CM_ SG_ 1017 VCSEC_a141_tooFewKeysOnWhitelist "Vehicle security controller: a141 too few keys on whitelist";
CM_ SG_ 1017 VCSEC_a142_bleGattAlertC "Vehicle security controller: a142 ble gatt alert c";
CM_ SG_ 1017 VCSEC_a143_bleGattAlertL "Vehicle security controller: a143 ble gatt alert l";
CM_ SG_ 1017 VCSEC_a144_bleGattAlertR "Vehicle security controller: a144 ble gatt alert r";
CM_ SG_ 1017 VCSEC_a145_bleGattAlertRe "Vehicle security controller: a145 ble gatt alert re";
CM_ SG_ 1017 VCSEC_a147_protobufRXTimeout "Vehicle security controller: a147 protobuf RX timeout";
CM_ SG_ 1017 VCSEC_a148_keyWhitelistFull "Vehicle security controller: a148 key whitelist full";
CM_ SG_ 1017 VCSEC_a149_attrsWentMissingL "Vehicle security controller: a149 attrs went missing l";
CM_ SG_ 1017 VCSEC_a150_attrsWentMissingR "Vehicle security controller: a150 attrs went missing r";
CM_ SG_ 1017 VCSEC_a151_attrsWentMissingRe "Vehicle security controller: a151 attrs went missing re";
CM_ SG_ 1017 VCSEC_a153_srvcCmdTimeoutC "Vehicle security controller: a153 srvc cmd timeout c";
CM_ SG_ 1017 VCSEC_a154_srvcCmdTimeoutL "Vehicle security controller: a154 srvc cmd timeout l";
CM_ SG_ 1017 VCSEC_a155_srvcCmdTimeoutR "Vehicle security controller: a155 srvc cmd timeout r";
CM_ SG_ 1017 VCSEC_a156_srvcCmdTimeoutRe "Vehicle security controller: a156 srvc cmd timeout re";
CM_ SG_ 1017 VCSEC_a158_hciDebugC "Vehicle security controller: a158 hci debug c";
CM_ SG_ 1017 VCSEC_a159_hciDebugL "Vehicle security controller: a159 hci debug l";
CM_ SG_ 1017 VCSEC_a161_hciDebugR "Vehicle security controller: a161 hci debug r";
CM_ SG_ 1017 VCSEC_a162_hciDebugRe "Vehicle security controller: a162 hci debug re";
CM_ SG_ 1017 VCSEC_a164_attrsWentMissingC "Vehicle security controller: a164 attrs went missing c";
CM_ SG_ 1017 VCSEC_a165_ephemeralKeyGenerated "Vehicle security controller: a165 ephemeral key generated";
CM_ SG_ 1017 VCSEC_a166_BLECenterPowerCycled "Vehicle security controller: a166 BLE center power cycled";
CM_ SG_ 1017 VCSEC_a167_BLECenterSoftReset "Vehicle security controller: a167 BLE center soft reset";
CM_ SG_ 1017 VCSEC_a168_BLELeftSoftReset "Vehicle security controller: a168 BLE left soft reset";
CM_ SG_ 1017 VCSEC_a169_BLERightSoftReset "Vehicle security controller: a169 BLE right soft reset";
CM_ SG_ 1017 VCSEC_a170_BLERearSoftReset "Vehicle security controller: a170 BLE rear soft reset";
CM_ SG_ 1017 VCSEC_a172_BLEUnexpectedResetC "Vehicle security controller: a172 BLE unexpected reset c";
CM_ SG_ 1017 VCSEC_a173_BLEUnexpectedResetL "Vehicle security controller: a173 BLE unexpected reset l";
CM_ SG_ 1017 VCSEC_a174_BLEUnexpectedResetRi "Vehicle security controller: a174 BLE unexpected reset ri";
CM_ SG_ 1017 VCSEC_a175_BLEUnexpectedResetRe "Vehicle security controller: a175 BLE unexpected reset re";
CM_ SG_ 1017 VCSEC_a177_whitelistAddedKey "Vehicle security controller: a177 whitelist added key";
CM_ SG_ 1017 VCSEC_a178_whitelistRemovedKey "Vehicle security controller: a178 whitelist removed key";
CM_ SG_ 1017 VCSEC_a179_InfotainmentNotPaired "Vehicle security controller: a179 infotainment not paired";
CM_ SG_ 1017 VCSEC_a180_wlistRemovedPermissio "Vehicle security controller: a180 wlist removed permission";
CM_ SG_ 1017 VCSEC_a181_signedMessageFault "Vehicle security controller: a181 signed message fault";
CM_ SG_ 1017 VCSEC_a182_cryptoHighStackUsage "Vehicle security controller: a182 crypto high stack usage";
CM_ SG_ 1017 VCSEC_a183_centerEndpointRFMia "Vehicle security controller: a183 center endpoint RF mia";
CM_ SG_ 1017 VCSEC_a184_driverEndpointRFMia "Vehicle security controller: a184 driver endpoint RF mia";
CM_ SG_ 1017 VCSEC_a185_passengerEndpointRFMi "Vehicle security controller: a185 passenger endpoint RF mia";
CM_ SG_ 1017 VCSEC_a186_rearEndpointRFMia "Vehicle security controller: a186 rear endpoint RF mia";
CM_ SG_ 1017 VCSEC_a187_badConnectionDropped "Vehicle security controller: a187 bad connection dropped";
CM_ SG_ 1017 VCSEC_a188_protobufDecodeError "Vehicle security controller: a188 protobuf decode error";
CM_ SG_ 1017 VCSEC_a189_protoExpLengthTooLarg "Vehicle security controller: a189 proto exp length too large";
CM_ SG_ 1017 VCSEC_a190_protoTooManyBytes "Vehicle security controller: a190 proto too many bytes";
CM_ SG_ 1017 VCSEC_a191_macIDWlistingFailedC "Vehicle security controller: a191 mac ID wlisting failed c";
CM_ SG_ 1017 VCSEC_a192_macIDWlistingFailedL "Vehicle security controller: a192 mac ID wlisting failed l";
CM_ SG_ 1017 VCSEC_a193_macIDWlistingFailedRi "Vehicle security controller: a193 mac ID wlisting failed ri";
CM_ SG_ 1017 VCSEC_a194_macIDWlistingFailedRe "Vehicle security controller: a194 mac ID wlisting failed re";
CM_ SG_ 1017 VCSEC_a195_keyMissingInDrive "Vehicle security controller: a195 key missing in drive";
CM_ SG_ 1017 VCSEC_a196_protobufTXTimeout "Vehicle security controller: a196 protobuf TX timeout";
CM_ SG_ 1017 VCSEC_a197_indicationFault "Vehicle security controller: a197 indication fault";
CM_ SG_ 1017 VCSEC_a198_BPillarNFCReaderMIA "Vehicle security controller: a198 b pillar NFC reader MIA";
CM_ SG_ 1017 VCSEC_a199_CenterNFCReaderMIA "Vehicle security controller: a199 center NFC reader MIA";
CM_ SG_ 1017 VCSEC_a200_centerEndpointLostCom "Vehicle security controller: a200 center endpoint lost comm";
CM_ SG_ 1017 VCSEC_a201_leftEndpointLostComm "Vehicle security controller: a201 left endpoint lost comm";
CM_ SG_ 1017 VCSEC_a202_rightEndpointLostComm "Vehicle security controller: a202 right endpoint lost comm";
CM_ SG_ 1017 VCSEC_a203_rearEndpointLostComm "Vehicle security controller: a203 rear endpoint lost comm";
CM_ SG_ 1017 VCSEC_a204_SharedSecretsWritten "Vehicle security controller: a204 shared secrets written";
CM_ SG_ 1017 VCSEC_a205_MTUUpdateNotConfirmed "Vehicle security controller: a205 MTU update not confirmed";
CM_ SG_ 1017 VCSEC_a206_BLELeftAssertFailure "Vehicle security controller: a206 BLE left assert failure";
CM_ SG_ 1017 VCSEC_a207_BLERightAssertFailure "Vehicle security controller: a207 BLE right assert failure";
CM_ SG_ 1017 VCSEC_a208_BLERearAssertFailure "Vehicle security controller: a208 BLE rear assert failure";
CM_ SG_ 1017 VCSEC_a209_BLECenterAssertFailur "Vehicle security controller: a209 BLE center assert failure";
CM_ SG_ 1017 VCSEC_a210_keyDeviceBatteryLow "Vehicle security controller: a210 key device battery low";
CM_ SG_ 1017 VCSEC_a211_handlePullWithoutAuth "Vehicle security controller: a211 handle pull without auth";
CM_ SG_ 1017 VCSEC_a212_snifferRSSIMIA "Vehicle security controller: a212 sniffer RSSIMIA";
CM_ SG_ 1017 VCSEC_a213_gattTimeoutWithExptdC "Vehicle security controller: a213 gatt timeout with exptd count";
CM_ SG_ 1017 VCSEC_a214_gattServFalseWaitToBo "Vehicle security controller: a214 gatt serv false wait to boot";
CM_ SG_ 1017 VCSEC_a215_TPMSUnexpectedDisconn "Vehicle security controller: a215 TPMS unexpected disconnect sensor0";
CM_ SG_ 1017 VCSEC_a216_TPMSUnexpectedDisconn "Vehicle security controller: a216 TPMS unexpected disconnect sensor1";
CM_ SG_ 1017 VCSEC_a217_TPMSUnexpectedDisconn "Vehicle security controller: a217 TPMS unexpected disconnect sensor2";
CM_ SG_ 1017 VCSEC_a218_TPMSUnexpectedDisconn "Vehicle security controller: a218 TPMS unexpected disconnect sensor3";
CM_ SG_ 1017 VCSEC_a219_TPMSSensorPairingRemo "Vehicle security controller: a219 TPMS sensor pairing removed";
CM_ SG_ 1017 VCSEC_a220_TPMSSensorPairingNotC "Vehicle security controller: a220 TPMS sensor pairing not completed";
CM_ SG_ 1017 VCSEC_a221_TPMSSoftWarning "Vehicle security controller: a221 TPMS soft warning";
CM_ SG_ 1017 VCSEC_a222_TPMSSystemMalfunction "Vehicle security controller: a222 TPMS system malfunction";
CM_ SG_ 1017 VCSEC_a223_TPMSSensorConnectionC "Vehicle security controller: a223 TPMS sensor connection cycling0";
CM_ SG_ 1017 VCSEC_a224_TPMSSensorConnectionC "Vehicle security controller: a224 TPMS sensor connection cycling1";
CM_ SG_ 1017 VCSEC_a225_TPMSSensorConnectionC "Vehicle security controller: a225 TPMS sensor connection cycling2";
CM_ SG_ 1017 VCSEC_a226_TPMSSensorConnectionC "Vehicle security controller: a226 TPMS sensor connection cycling3";
CM_ SG_ 1017 VCSEC_a227_connectionWithoutLink "Vehicle security controller: a227 connection without link event";
CM_ SG_ 1017 VCSEC_a228_TPMSHardWarning "Vehicle security controller: a228 TPMS hard warning";
CM_ SG_ 1017 VCSEC_a235_presentWithoutHandleP "Vehicle security controller: a235 present without handle pull";
CM_ SG_ 1017 VCSEC_a236_keyIdentificationMaxA "Vehicle security controller: a236 key identification max attempt reached";
CM_ SG_ 1017 VCSEC_a237_keyNotReadyToReceiveI "Vehicle security controller: a237 key not ready to receive ID requests";
CM_ SG_ 1017 VCSEC_a238_TPMSLocationsUpdated "Vehicle security controller: a238 TPMS locations updated";
CM_ SG_ 1017 VCSEC_a239_TPMSIdleConnection "Vehicle security controller: a239 TPMS idle connection";
CM_ SG_ 1017 VCSEC_a240_noKeysPaired "Vehicle security controller: a240 no keys paired";
CM_ SG_ 1017 VCSEC_a241_TPMSUpdateStartedSens "Vehicle security controller: a241 TPMS update started sensor0";
CM_ SG_ 1017 VCSEC_a242_TPMSUpdateStartedSens "Vehicle security controller: a242 TPMS update started sensor1";
CM_ SG_ 1017 VCSEC_a243_TPMSUpdateStartedSens "Vehicle security controller: a243 TPMS update started sensor2";
CM_ SG_ 1017 VCSEC_a244_TPMSUpdateStartedSens "Vehicle security controller: a244 TPMS update started sensor3";
CM_ SG_ 1017 VCSEC_a245_TPMSUpdateInterrupted "Vehicle security controller: a245 TPMS update interrupted sensor0";
CM_ SG_ 1017 VCSEC_a246_TPMSUpdateInterrupted "Vehicle security controller: a246 TPMS update interrupted sensor1";
CM_ SG_ 1017 VCSEC_a247_TPMSUpdateInterrupted "Vehicle security controller: a247 TPMS update interrupted sensor2";
CM_ SG_ 1017 VCSEC_a248_TPMSUpdateInterrupted "Vehicle security controller: a248 TPMS update interrupted sensor3";
CM_ SG_ 1017 VCSEC_a249_TPMSUpdateCompleteSen "Vehicle security controller: a249 TPMS update complete sensor0";
CM_ SG_ 1017 VCSEC_a250_TPMSUpdateCompleteSen "Vehicle security controller: a250 TPMS update complete sensor1";
CM_ SG_ 1017 VCSEC_a251_TPMSUpdateCompleteSen "Vehicle security controller: a251 TPMS update complete sensor2";
CM_ SG_ 1017 VCSEC_a252_TPMSUpdateCompleteSen "Vehicle security controller: a252 TPMS update complete sensor3";
CM_ SG_ 1017 VCSEC_a254_whitelistUpdatedKey "Vehicle security controller: a254 whitelist updated key";
CM_ SG_ 1017 VCSEC_a255_wlistUpdatedPermissio "Vehicle security controller: a255 wlist updated permission";
CM_ SG_ 1017 VCSEC_a256_whitelistOperationFai "Vehicle security controller: a256 whitelist operation fail";
CM_ SG_ 1017 VCSEC_a257_connectedKeyIsExpirin "Vehicle security controller: a257 connected key is expiring";
CM_ SG_ 1017 VCSEC_a258_keyIsExpiring "Vehicle security controller: a258 key is expiring";
CM_ SG_ 1017 VCSEC_a260_prsntPhoneKeyDisconne "Vehicle security controller: a260 prsnt phone key disconnected";
CM_ SG_ 1017 VCSEC_a261_TPMSFactoryLearnActiv "Vehicle security controller: a261 TPMS factory learn active";
CM_ SG_ 1017 VCSEC_a262_flowControlBackedUp "Vehicle security controller: a262 flow control backed up";
CM_ SG_ 1017 VCSEC_a263_dispatchCouldNotBeCom "Vehicle security controller: a263 dispatch could not be completed";
CM_ SG_ 1017 VCSEC_a264_noOnePopulatedMessage "Vehicle security controller: a264 no one populated message";
CM_ SG_ 1017 VCSEC_a265_tooManyPopulatedMessa "Vehicle security controller: a265 too many populated message";
CM_ SG_ 1017 VCSEC_a266_TPMSSoftWarningFrontL "Vehicle security controller: a266 TPMS soft warning front left";
CM_ SG_ 1017 VCSEC_a267_TPMSSoftWarningFrontR "Vehicle security controller: a267 TPMS soft warning front right";
CM_ SG_ 1017 VCSEC_a268_TPMSSoftWarningRearLe "Vehicle security controller: a268 TPMS soft warning rear left";
CM_ SG_ 1017 VCSEC_a269_TPMSSoftWarningRearRi "Vehicle security controller: a269 TPMS soft warning rear right";
CM_ SG_ 1017 VCSEC_a270_TPMSHardWarningFrontL "Vehicle security controller: a270 TPMS hard warning front left";
CM_ SG_ 1017 VCSEC_a271_TPMSHardWarningFrontR "Vehicle security controller: a271 TPMS hard warning front right";
CM_ SG_ 1017 VCSEC_a272_TPMSHardWarningRearLe "Vehicle security controller: a272 TPMS hard warning rear left";
CM_ SG_ 1017 VCSEC_a273_TPMSHardWarningRearRi "Vehicle security controller: a273 TPMS hard warning rear right";
CM_ SG_ 1017 VCSEC_a274_handlePullWithoutAuth "Vehicle security controller: a274 handle pull without auth2";
CM_ SG_ 1017 VCSEC_a275_childSeatNotConnected "Vehicle security controller: a275 child seat not connected at start of drive";
CM_ SG_ 1017 VCSEC_a276_childSeatNotConnected "Vehicle security controller: a276 child seat not connected at end of drive";
CM_ SG_ 1017 VCSEC_a277_childSeatBatteryIsLow "Vehicle security controller: a277 child seat battery is low";
CM_ SG_ 1017 VCSEC_a280_TPMSLowBattery0 "Vehicle security controller: a280 TPMS low battery0";
CM_ SG_ 1017 VCSEC_a281_TPMSLowBattery1 "Vehicle security controller: a281 TPMS low battery1";
CM_ SG_ 1017 VCSEC_a282_TPMSLowBattery2 "Vehicle security controller: a282 TPMS low battery2";
CM_ SG_ 1017 VCSEC_a283_TPMSLowBattery3 "Vehicle security controller: a283 TPMS low battery3";
CM_ SG_ 1017 VCSEC_a300_scheduleItKeyAdded "Vehicle security controller: a300 schedule it key added";
CM_ SG_ 1017 VCSEC_a301_imposterDetected "Vehicle security controller: a301 imposter detected";
CM_ SG_ 1017 VCSEC_a302_unfused "Vehicle security controller: a302 unfused";
CM_ SG_ 1017 VCSEC_a303_KeyfobUpdateInterrupt "Vehicle security controller: a303 keyfob update interrupted";
CM_ SG_ 1017 VCSEC_a304_KeyfobUpdateComplete "Vehicle security controller: a304 keyfob update complete";
CM_ SG_ 1017 VCSEC_a305_ATTFlowControlViolate "Vehicle security controller: a305 ATT flow control violated c";
CM_ SG_ 1017 VCSEC_a306_KeyfobAdvReceivedWhil "Vehicle security controller: a306 keyfob adv received while connected";
CM_ SG_ 1017 VCSEC_a307_ATTTimeout "Vehicle security controller: a307 ATT timeout";
CM_ SG_ 1017 VCSEC_a308_NonConnectableAdvRece "Vehicle security controller: a308 non connectable adv received";
CM_ SG_ 1017 VCSEC_a309_serviceKeyConditionsN "Vehicle security controller: a309 service key conditions not met";
CM_ SG_ 1017 VCSEC_a310_chargePortFilterFalse "Vehicle security controller: a310 charge port filter false positive";
CM_ SG_ 1017 VCSEC_a311_moreThanThreeKeysPres "Vehicle security controller: a311 more than three keys present";
CM_ SG_ 1017 VCSEC_a312_unexpectedBLEDisconne "Vehicle security controller: a312 unexpected BLE disconnect";
CM_ SG_ 1017 VCSEC_a315_bleBondingEvent "Vehicle security controller: a315 ble bonding event";
CM_ SG_ 1017 VCSEC_a316_ltkRequestRejected "Vehicle security controller: a316 ltk request rejected";
CM_ SG_ 1017 VCSEC_a401_rearLeftEndpointLostC "Vehicle security controller: a401 rear left endpoint lost comm";
CM_ SG_ 1017 VCSEC_a402_rearRightEndpointLost "Vehicle security controller: a402 rear right endpoint lost comm";
CM_ SG_ 1017 VCSEC_a404_NFCCradleEndpointLost "Vehicle security controller: a404 NFC cradle endpoint lost comm";
CM_ SG_ 1017 VCSEC_a406_hciDebugRL "Vehicle security controller: a406 hci debug RL";
CM_ SG_ 1017 VCSEC_a407_hciDebugRR "Vehicle security controller: a407 hci debug RR";
CM_ SG_ 1017 VCSEC_a408_hciDebugNFCC "Vehicle security controller: a408 hci debug NFCC";
CM_ SG_ 1017 VCSEC_a411_leftRearEndpointBusy "Vehicle security controller: a411 left rear endpoint busy";
CM_ SG_ 1017 VCSEC_a412_rightRearEndpointBusy "Vehicle security controller: a412 right rear endpoint busy";
CM_ SG_ 1017 VCSEC_a413_NFCCradleEndpointBusy "Vehicle security controller: a413 NFC cradle endpoint busy";
CM_ SG_ 1017 VCSEC_a416_BLECradleNFCSoftReset "Vehicle security controller: a416 BLE cradle NFC soft reset";
CM_ SG_ 1017 VCSEC_a417_BLERearLeftSoftReset "Vehicle security controller: a417 BLE rear left soft reset";
CM_ SG_ 1017 VCSEC_a418_BLERearRightSoftReset "Vehicle security controller: a418 BLE rear right soft reset";
CM_ SG_ 1017 VCSEC_a420_BLEUnexpectedResetNFC "Vehicle security controller: a420 BLE unexpected reset NFC cradle";
CM_ SG_ 1017 VCSEC_a421_BLEUnexpectedResetRL "Vehicle security controller: a421 BLE unexpected reset RL";
CM_ SG_ 1017 VCSEC_a422_BLEUnexpectedResetRR "Vehicle security controller: a422 BLE unexpected reset RR";
CM_ SG_ 1017 VCSEC_a425_BLENFCCradleAssertFai "Vehicle security controller: a425 BLENFC cradle assert failure";
CM_ SG_ 1017 VCSEC_a426_BLERearLeftAssertFail "Vehicle security controller: a426 BLE rear left assert failure";
CM_ SG_ 1017 VCSEC_a427_BLERearRightAssertFai "Vehicle security controller: a427 BLE rear right assert failure";
CM_ SG_ 1017 VCSEC_a428_UWBCenterUpdateInterr "Vehicle security controller: a428 UWB center update interrupted";
CM_ SG_ 1017 VCSEC_a429_UWBLeftUpdateInterrup "Vehicle security controller: a429 UWB left update interrupted";
CM_ SG_ 1017 VCSEC_a430_UWBRightUpdateInterru "Vehicle security controller: a430 UWB right update interrupted";
CM_ SG_ 1017 VCSEC_a432_UWBRearLeftUpdateInte "Vehicle security controller: a432 UWB rear left update interrupted";
CM_ SG_ 1017 VCSEC_a433_UWBRearRightUpdateInt "Vehicle security controller: a433 UWB rear right update interrupted";
CM_ SG_ 1017 VCSEC_a434_UWBRadioConfigUpdated "Vehicle security controller: a434 UWB radio config updated";
CM_ SG_ 1017 VCSEC_a435_NFCCardPresentWhileCh "Vehicle security controller: a435 NFC card present while charging";
CM_ SG_ 1017 VCSEC_a436_uhfHWDoesNotMatchCoun "Vehicle security controller: a436 uhf HW does not match country";
CM_ SG_ 1017 VCSEC_a437_NearbyInteractionDebu "Vehicle security controller: a437 nearby interaction debug";
CM_ SG_ 1017 VCSEC_a438_UWBRearUpdateInterrup "Vehicle security controller: a438 UWB rear update interrupted";
CM_ SG_ 1017 VCSEC_a453_passiveDisabled "Vehicle security controller: a453 passive disabled";
CM_ SG_ 1017 VCSEC_a454_TPMSOverPressureWarni "Vehicle security controller: a454 TPMS over pressure warning";
CM_ SG_ 1017 VCSEC_a455_TPMSOverPressureWarni "Vehicle security controller: a455 TPMS over pressure warning front left";
CM_ SG_ 1017 VCSEC_a456_TPMSOverPressureWarni "Vehicle security controller: a456 TPMS over pressure warning front right";
CM_ SG_ 1017 VCSEC_a457_TPMSOverPressureWarni "Vehicle security controller: a457 TPMS over pressure warning rear left";
CM_ SG_ 1017 VCSEC_a458_TPMSOverPressureWarni "Vehicle security controller: a458 TPMS over pressure warning rear right";
CM_ SG_ 1017 VCSEC_a459_TPMSCertCheckFailedSe "Vehicle security controller: a459 TPMS cert check failed sensor0";
CM_ SG_ 1017 VCSEC_a460_TPMSCertCheckFailedSe "Vehicle security controller: a460 TPMS cert check failed sensor1";
CM_ SG_ 1017 VCSEC_a461_TPMSCertCheckFailedSe "Vehicle security controller: a461 TPMS cert check failed sensor2";
CM_ SG_ 1017 VCSEC_a462_TPMSCertCheckFailedSe "Vehicle security controller: a462 TPMS cert check failed sensor3";
CM_ SG_ 1017 VCSEC_a465_UWBRearLeftKeyVerific "Vehicle security controller: a465 UWB rear left key verification failure";
CM_ SG_ 1017 VCSEC_a466_UWBRearRightKeyVerifi "Vehicle security controller: a466 UWB rear right key verification failure";
CM_ SG_ 1017 VCSEC_a467_UWBCenterKeyVerificat "Vehicle security controller: a467 UWB center key verification failure";
CM_ SG_ 1017 VCSEC_a468_UWBRearKeyVerificatio "Vehicle security controller: a468 UWB rear key verification failure";
CM_ SG_ 1017 VCSEC_a469_UWBLeftKeyVerificatio "Vehicle security controller: a469 UWB left key verification failure";
CM_ SG_ 1017 VCSEC_a470_UWBRightKeyVerificati "Vehicle security controller: a470 UWB right key verification failure";
CM_ SG_ 1017 VCSEC_a472_peerRemovedInformatio "Vehicle security controller: a472 peer removed information";
CM_ SG_ 1017 VCSEC_a473_handlePullWithoutAuth "Vehicle security controller: a473 handle pull without auth3";
CM_ SG_ 1017 VCSEC_a474_handlePullWithoutAuth "Vehicle security controller: a474 handle pull without auth4";
CM_ SG_ 1017 VCSEC_a475_handlePullWithoutAuth "Vehicle security controller: a475 handle pull without auth5";
CM_ SG_ 1017 VCSEC_a476_handlePullWithoutAuth "Vehicle security controller: a476 handle pull without auth6";
CM_ SG_ 1017 VCSEC_a477_phoneStartedBonding "Vehicle security controller: a477 phone started bonding";
CM_ SG_ 1017 VCSEC_a478_handlePullWithoutAuth "Vehicle security controller: a478 handle pull without auth7";
CM_ SG_ 1017 VCSEC_a479_handlePullWithoutAuth "Vehicle security controller: a479 handle pull without auth NI state dev0";
CM_ SG_ 1017 VCSEC_a480_handlePullWithoutAuth "Vehicle security controller: a480 handle pull without auth NI state dev1";
CM_ SG_ 1017 VCSEC_a481_handlePullWithoutAuth "Vehicle security controller: a481 handle pull without auth NI state dev2";
CM_ SG_ 1017 VCSEC_a482_VINChanged "Vehicle security controller: a482 VIN changed";
CM_ SG_ 1017 VCSEC_a483_highThermalGradiantDe "Vehicle security controller: a483 high thermal gradiant detected";
CM_ SG_ 1017 VCSEC_a484_UWBLeftUpdateTriggere "Vehicle security controller: a484 UWB left update triggered";
CM_ SG_ 1017 VCSEC_a485_UWBCenterUpdateTrigge "Vehicle security controller: a485 UWB center update triggered";
CM_ SG_ 1017 VCSEC_a486_UWBRightUpdateTrigger "Vehicle security controller: a486 UWB right update triggered";
CM_ SG_ 1017 VCSEC_a487_unrecognizedProto "Vehicle security controller: a487 unrecognized proto";
CM_ SG_ 1017 VCSEC_a488_FiraRangingRejected "Vehicle security controller: a488 fira ranging rejected";
CM_ SG_ 1017 VCSEC_a489_UWBRearLeftUpdateTrig "Vehicle security controller: a489 UWB rear left update triggered";
CM_ SG_ 1017 VCSEC_a490_UWBRearRightUpdateTri "Vehicle security controller: a490 UWB rear right update triggered";
CM_ SG_ 1017 VCSEC_a494_UWBRearUpdateTriggere "Vehicle security controller: a494 UWB rear update triggered";
CM_ SG_ 1017 VCSEC_a495_handlePullWithoutAuth "Vehicle security controller: a495 handle pull without auth i OS";
CM_ SG_ 1017 VCSEC_a496_handlePullWithoutAuth "Vehicle security controller: a496 handle pull without auth android";
CM_ SG_ 1017 VCSEC_a497_incorrectEndpointInst "Vehicle security controller: a497 incorrect endpoint installation";
CM_ SG_ 1017 VCSEC_a498_TPMSFeature0Reached "Vehicle security controller: a498 TPMS feature0 reached";
CM_ SG_ 1017 VCSEC_a499_TPMSAssertFailure0 "Vehicle security controller: a499 TPMS assert failure0";
CM_ SG_ 1017 VCSEC_a500_TPMSAssertFailure1 "Vehicle security controller: a500 TPMS assert failure1";
CM_ SG_ 1017 VCSEC_a501_TPMSAssertFailure2 "Vehicle security controller: a501 TPMS assert failure2";
CM_ SG_ 1017 VCSEC_a502_TPMSAssertFailure3 "Vehicle security controller: a502 TPMS assert failure3";
CM_ SG_ 1017 VCSEC_a503_CANMsgMACVerification "Vehicle security controller: a503 CAN msg MAC verification failure";
CM_ SG_ 1017 VCSEC_a504_CANMsgMACVerification "Vehicle security controller: a504 CAN msg MAC verification key not provisioned";
CM_ SG_ 1017 VCSEC_a505_CANMsgMACVerification "Vehicle security controller: a505 CAN msg MAC verification key mismatch";
CM_ SG_ 1017 VCSEC_a510_watchKeyOffWrist "Vehicle security controller: a510 watch key off wrist";
CM_ SG_ 1017 VCSEC_a511_phoneKeyStationary "Vehicle security controller: a511 phone key stationary";
CM_ SG_ 1017 VCSEC_a513_TPMSConnectionStatsNo "Vehicle security controller: a513 TPMS connection stats not received0";
CM_ SG_ 1017 VCSEC_a514_TPMSConnectionStatsNo "Vehicle security controller: a514 TPMS connection stats not received1";
CM_ SG_ 1017 VCSEC_a515_TPMSConnectionStatsNo "Vehicle security controller: a515 TPMS connection stats not received2";
CM_ SG_ 1017 VCSEC_a516_TPMSConnectionStatsNo "Vehicle security controller: a516 TPMS connection stats not received3";
CM_ SG_ 1017 VCSEC_a517_TPMSOutOfRangePressur "Vehicle security controller: a517 TPMS out of range pressure received0";
CM_ SG_ 1017 VCSEC_a518_TPMSOutOfRangePressur "Vehicle security controller: a518 TPMS out of range pressure received1";
CM_ SG_ 1017 VCSEC_a519_TPMSOutOfRangePressur "Vehicle security controller: a519 TPMS out of range pressure received2";
CM_ SG_ 1017 VCSEC_a520_TPMSOutOfRangePressur "Vehicle security controller: a520 TPMS out of range pressure received3";
CM_ SG_ 1017 VCSEC_a521_TPMSSensorLowConfiden "Vehicle security controller: a521 TPMS sensor low confidence sensor localization0";
CM_ SG_ 1017 VCSEC_a522_TPMSSensorLowConfiden "Vehicle security controller: a522 TPMS sensor low confidence sensor localization1";
CM_ SG_ 1017 VCSEC_a523_TPMSSensorLowConfiden "Vehicle security controller: a523 TPMS sensor low confidence sensor localization2";
CM_ SG_ 1017 VCSEC_a524_TPMSSensorLowConfiden "Vehicle security controller: a524 TPMS sensor low confidence sensor localization3";
CM_ SG_ 1017 VCSEC_a525_TPMSLocalizationMulti "Vehicle security controller: a525 TPMS localization multiple sensors for position FL";
CM_ SG_ 1017 VCSEC_a526_TPMSLocalizationMulti "Vehicle security controller: a526 TPMS localization multiple sensors for position FR";
CM_ SG_ 1017 VCSEC_a527_TPMSLocalizationMulti "Vehicle security controller: a527 TPMS localization multiple sensors for position RL";
CM_ SG_ 1017 VCSEC_a528_TPMSLocalizationMulti "Vehicle security controller: a528 TPMS localization multiple sensors for position RR";
CM_ SG_ 1017 VCSEC_a529_TPMSTireServiceDetect "Vehicle security controller: a529 TPMS tire service detected";
CM_ SG_ 1017 VCSEC_a540_dummyAlertMax "Vehicle security controller: a540 dummy alert max";
CM_ BO_ 825 "Vehicle security controller message: authentication";
CM_ SG_ 825 VCSEC_BLEConnectionCounter "The number of devices connected to the host Bluetooth endpoint.";
CM_ SG_ 825 VCSEC_authRejectionReason "Reason it was rejected";
CM_ SG_ 825 VCSEC_IDRequested "Vehicle security controller: ID requested";
CM_ SG_ 825 VCSEC_operationMode "Reports the operation mode of the vehicle.";
CM_ SG_ 825 VCSEC_vehicleLockStatus "Lock status of the vehicle.";
CM_ SG_ 825 VCSEC_authenticationStatus "Reports the vehicle authentication status.";
CM_ SG_ 825 VCSEC_chargePortLockStatus "Lock status of the charge port.";
CM_ SG_ 825 VCSEC_leftFrontLockStatus "Lock status of the left front door.";
CM_ SG_ 825 VCSEC_leftRearLockStatus "Lock status of the left rear door.";
CM_ SG_ 825 VCSEC_rightFrontLockStatus "Lock status of the right front door.";
CM_ SG_ 825 VCSEC_rightRearLockStatus "Lock status of right rear door.";
CM_ SG_ 825 VCSEC_trunkLockStatus "Lock status of the trunk.";
CM_ SG_ 825 VCSEC_lockRequestType "Reports the type of lock and unlock request received.";
CM_ SG_ 825 VCSEC_summonRequest "Reports the Summon request state.";
CM_ SG_ 825 VCSEC_3rdPartyPLGRequest "Vehicle security controller: 3rd party PLG request";
CM_ SG_ 825 VCSEC_3rdPartyFrunkPLGRequest "Vehicle security controller: 3rd party frunk PLG request";
CM_ SG_ 825 VCSEC_MCUCommandType "Vehicle security controller: MCU command type";
CM_ SG_ 825 VCSEC_frunkLockStatus "Lock status of the frunk";
CM_ SG_ 825 VCSEC_usingModifiedMACAddress "Vehicle security controller: using modified MAC address";
CM_ SG_ 825 VCSEC_isKeyWithinSummonRange "Key is within the range of the car where summon can be enabled";
CM_ SG_ 825 VCSEC_isBLEDeviceWithinSummonRan "Indicates whether a Bluetooth Low Energy (BLE) device is within the range where Summon can be enabled.";
CM_ SG_ 825 VCSEC_alarmStatus "Reports the vehicle alarm status.";
CM_ SG_ 825 VCSEC_serviceDiagnosticRequest "Vehicle security controller: service diagnostic request";
CM_ SG_ 825 VCSEC_immobilizerState "State of the immobilizer.";
CM_ SG_ 825 VCSEC_lockIndicationRequest "Requests to turn on vehicle turn indicators based on lock and unlock states.";
CM_ SG_ 825 VCSEC_simpleLockStatus "Vehicle lock status with simplfied two states: lock and unlock.";
CM_ SG_ 825 VCSEC_keyChannelIndexed "Vehicle security controller: key channel indexed";
CM_ SG_ 825 VCSEC_authRequested "An authentication request was sent from the security controller to the authentication device.";
CM_ SG_ 825 VCSEC_remoteStartActive "Indicates when a remote start request terminated by the Vehicle Security Controller (VCSEC) is active.";
CM_ SG_ 825 VCSEC_keyPairDesired "Vehicle security controller: key pair desired";
CM_ BO_ 1817 "Vehicle security controller message: debug100ms";
CM_ SG_ 1817 VCSEC_debug100msIndex "Vehicle security controller: debug100ms index";
CM_ SG_ 1817 VCSEC_walkAwayLockKeyState "Walk away lock key state of the vehicle";
CM_ SG_ 1817 VCSEC_thresholdOffsetVersion "Vehicle security controller: threshold offset version";
CM_ SG_ 1817 VCSEC_walkAwayLockState "Walk away lock state of the vehicle";
CM_ SG_ 1817 VCSEC_rssi0WLEntry "Whitelist entry of the rssi0 device";
CM_ SG_ 1817 VCSEC_endpointLayout "Vehicle security controller: endpoint layout";
CM_ SG_ 1817 VCSEC_rssi1WLEntry "Whitelist entry of the rssi1 device";
CM_ SG_ 1817 VCSEC_rssi2WLEntry "Whitelist entry of the rssi2 device";
CM_ SG_ 1817 VCSEC_walkUpUnlockState "Status of walk up unlock state";
CM_ SG_ 1817 VCSEC_algoHighThreshLeft "Vehicle security controller: algo high thresh left";
CM_ SG_ 1817 VCSEC_algoHighThreshRight "Vehicle security controller: algo high thresh right";
CM_ SG_ 1817 VCSEC_algoHighThreshCenter "Vehicle security controller: algo high thresh center";
CM_ SG_ 1817 VCSEC_pollingReason "Reason that the vehicle is currently polling for location";
CM_ SG_ 1817 VCSEC_numberOfPubKeysOnWhitelist "Number of public keys on keys whitelist.";
CM_ SG_ 1817 VCSEC_thermalDetectState "Reports the current state of thermal detection.";
CM_ SG_ 1817 VCSEC_chargeHandleMitigationActi "Vehicle security controller: charge handle mitigation active";
CM_ SG_ 1817 VCSEC_smartTrunkMitigatedKeyCoun "Vehicle security controller: smart trunk mitigated key count";
CM_ SG_ 1817 VCSEC_UWB3WLEntry "Whitelist entry of UWB3 device, phone that requested robotaxi and is not connected over BLE";
CM_ SG_ 1817 VCSEC_device0Offset "Vehicle security controller: device0 offset";
CM_ SG_ 1817 VCSEC_device1Offset "Vehicle security controller: device1 offset";
CM_ SG_ 1817 VCSEC_device2Offset "Vehicle security controller: device2 offset";
CM_ SG_ 1817 VCSEC_connection0BondingState "state of the GAP bonding statemachine";
CM_ SG_ 1817 VCSEC_connection1BondingState "state of the GAP bonding statemachine";
CM_ SG_ 1817 VCSEC_connection2BondingState "state of the GAP bonding statemachine";
CM_ SG_ 1817 VCSEC_connection0UWBAvailability "state of the UWB availability on the BLE connection";
CM_ SG_ 1817 VCSEC_connection1UWBAvailability "state of the UWB availability on the BLE connection";
CM_ SG_ 1817 VCSEC_connection2UWBAvailability "state of the UWB availability on the BLE connection";
CM_ SG_ 1817 VCSEC_NISessionStateCenter0 "Vehicle security controller: NI session state center0";
CM_ SG_ 1817 VCSEC_NISessionStateLeft0 "Vehicle security controller: NI session state left0";
CM_ SG_ 1817 VCSEC_NISessionStateRight0 "Vehicle security controller: NI session state right0";
CM_ SG_ 1817 VCSEC_NISessionStateRearLeft0 "Vehicle security controller: NI session state rear left0";
CM_ SG_ 1817 VCSEC_NISessionStateRearRight0 "Vehicle security controller: NI session state rear right0";
CM_ SG_ 1817 VCSEC_NISessionStateRear0 "Vehicle security controller: NI session state rear0";
CM_ SG_ 1817 VCSEC_NISessionStateCenter1 "Vehicle security controller: NI session state center1";
CM_ SG_ 1817 VCSEC_NISessionStateLeft1 "Vehicle security controller: NI session state left1";
CM_ SG_ 1817 VCSEC_NISessionStateRight1 "Vehicle security controller: NI session state right1";
CM_ SG_ 1817 VCSEC_NISessionStateRearLeft1 "Vehicle security controller: NI session state rear left1";
CM_ SG_ 1817 VCSEC_NISessionStateRearRight1 "Vehicle security controller: NI session state rear right1";
CM_ SG_ 1817 VCSEC_NISessionStateRear1 "Vehicle security controller: NI session state rear1";
CM_ SG_ 1817 VCSEC_NISessionStateCenter2 "Vehicle security controller: NI session state center2";
CM_ SG_ 1817 VCSEC_NISessionStateLeft2 "Vehicle security controller: NI session state left2";
CM_ SG_ 1817 VCSEC_NISessionStateRight2 "Vehicle security controller: NI session state right2";
CM_ SG_ 1817 VCSEC_NISessionStateRearLeft2 "Vehicle security controller: NI session state rear left2";
CM_ SG_ 1817 VCSEC_NISessionStateRearRight2 "Vehicle security controller: NI session state rear right2";
CM_ SG_ 1817 VCSEC_NISessionStateRear2 "Vehicle security controller: NI session state rear2";
CM_ SG_ 1817 VCSEC_NISessionStateLeft3 "Vehicle security controller: NI session state left3";
CM_ SG_ 1817 VCSEC_NISessionStateRight3 "Vehicle security controller: NI session state right3";
CM_ SG_ 1817 VCSEC_NISessionStateRearRight3 "Vehicle security controller: NI session state rear right3";
CM_ SG_ 1817 VCSEC_NISessionStateRearLeft3 "Vehicle security controller: NI session state rear left3";
CM_ SG_ 1817 VCSEC_NISessionStateCenter3 "Vehicle security controller: NI session state center3";
CM_ BO_ 1824 "Vehicle security controller message: ecu config";
CM_ SG_ 1824 VCSEC_ECUConfigCRC32 "Vehicle security controller: ECU config CRC32";
CM_ SG_ 1824 VCSEC_autoWriteConfig "Vehicle security controller: auto write config";
CM_ SG_ 1824 VCSEC_requestForConfig "Vehicle security controller: request for config";
CM_ BO_ 793 "Vehicle security controller message: info";
CM_ SG_ 793 VCSEC_infoIndex "Vehicle security controller: info index";
CM_ SG_ 793 VCSEC_infoBuildType "Vehicle security controller: info build type";
CM_ SG_ 793 VCSEC_infoBuildConfigId "Vehicle security controller: info build config id";
CM_ SG_ 793 VCSEC_infoHardwareId "Vehicle security controller: info hardware id";
CM_ SG_ 793 VCSEC_infoComponentId "Vehicle security controller: info component id";
CM_ SG_ 793 VCSEC_infoPcbaId "Vehicle security controller: info pcba id";
CM_ SG_ 793 VCSEC_infoAssemblyId "Vehicle security controller: info assembly id";
CM_ SG_ 793 VCSEC_infoUsageId "Vehicle security controller: info usage id";
CM_ SG_ 793 VCSEC_infoSubUsageId "Vehicle security controller: info sub usage id";
CM_ SG_ 793 VCSEC_infoAppCrc "Vehicle security controller: info app crc";
CM_ SG_ 793 VCSEC_infoSubcomponent1 "Vehicle security controller: info subcomponent1";
CM_ SG_ 793 VCSEC_infoAppGitHash "Vehicle security controller: info app git hash";
CM_ SG_ 793 VCSEC_infoBootGitHash "Vehicle security controller: info boot git hash";
CM_ SG_ 793 VCSEC_infoPlatformType "Vehicle security controller: info platform type";
CM_ SG_ 793 VCSEC_infoBootUdsProtoVersion "Vehicle security controller: info boot uds proto version";
CM_ SG_ 793 VCSEC_infoBootCrc "Vehicle security controller: info boot crc";
CM_ SG_ 793 VCSEC_infoSubcomponent2 "Vehicle security controller: info subcomponent2";
CM_ SG_ 793 VCSEC_infoSubcomponent3 "Vehicle security controller: info subcomponent3";
CM_ SG_ 793 VCSEC_infoSubcomponent4 "Vehicle security controller: info subcomponent4";
BA_DEF_ BO_ "GenMsgCycleTime" INT 0 3600000;
BA_DEF_ BO_ "GenMsgSendType" ENUM "Cyclic","NotUsed","NotUsed","NotUsed","NotUsed","NotUsed","NotUsed","IfActive","NoMsgSendType","NotUsed";
BA_DEF_ BO_ "VFrameFormat" ENUM "StandardCAN","ExtendedCAN","reserved","J1939PG","reserved","reserved","reserved","reserved","reserved","reserved","reserved","reserved","reserved","reserved","StandardCAN_FD","ExtendedCAN_FD";
BA_DEF_ BO_ "CANFD_BRS" ENUM "0","1";
BA_DEF_ SG_ "SystemSignalLongSymbol" STRING;
BA_DEF_ SG_ "Confidence" ENUM "layout-only","plausible","validated";
BA_DEF_DEF_ "GenMsgCycleTime" 0;
BA_DEF_DEF_ "GenMsgSendType" "NoMsgSendType";
BA_DEF_DEF_ "VFrameFormat" "StandardCAN";
BA_DEF_DEF_ "CANFD_BRS" "1";
BA_DEF_DEF_ "SystemSignalLongSymbol" "";
BA_DEF_DEF_ "Confidence" "layout-only";
BA_ "SystemSignalLongSymbol" SG_ 1328 VCSEC_a101_LIPC_externalWatchdog "VCSEC_a101_LIPC_externalWatchdogHeartBeat";
BA_ "SystemSignalLongSymbol" SG_ 1328 VCSEC_a110_VEH_canLogAvailabilit "VCSEC_a110_VEH_canLogAvailability";
BA_ "SystemSignalLongSymbol" SG_ 1328 VCSEC_a115_UI_corianderVehicleCo "VCSEC_a115_UI_corianderVehicleControl";
BA_ "SystemSignalLongSymbol" SG_ 1328 VCSEC_a117_BDY_falconSwitchStatu "VCSEC_a117_BDY_falconSwitchStatus";
BA_ "SystemSignalLongSymbol" SG_ 1328 VCSEC_a117_VEH_intrusionSensorSt "VCSEC_a117_VEH_intrusionSensorStatus";
BA_ "SystemSignalLongSymbol" SG_ 1328 VCSEC_a117_PARTY_lightingSeconda "VCSEC_a117_PARTY_lightingSecondary";
BA_ "SystemSignalLongSymbol" SG_ 1328 VCSEC_a118_PARTY_outputPowerStat "VCSEC_a118_PARTY_outputPowerStatus";
BA_ "SystemSignalLongSymbol" SG_ 1328 VCSEC_a118_VEH_interNodeResistan "VCSEC_a118_VEH_interNodeResistance";
BA_ "SystemSignalLongSymbol" SG_ 1328 VCSEC_a118_PARTY_AP_vehicleState "VCSEC_a118_PARTY_AP_vehicleState1HzMuxed";
BA_ "SystemSignalLongSymbol" SG_ 1328 VCSEC_a118_BDY_AP_vehicleState1H "VCSEC_a118_BDY_AP_vehicleState1HzMuxed";
BA_ "SystemSignalLongSymbol" SG_ 1328 VCSEC_a118_PARTY_VCFRONT_cameraC "VCSEC_a118_PARTY_VCFRONT_cameraCleaningStatus";
BA_ "SystemSignalLongSymbol" SG_ 1328 VCSEC_a120_PARTY_vehicleEstimate "VCSEC_a120_PARTY_vehicleEstimates";
BA_ "SystemSignalLongSymbol" SG_ 1328 VCSEC_a120_VEH_aggregatedAxleSpe "VCSEC_a120_VEH_aggregatedAxleSpeed";
BA_ "SystemSignalLongSymbol" SG_ 1328 VCSEC_a120_PARTY_aggregatedAxleS "VCSEC_a120_PARTY_aggregatedAxleSpeed";
BA_ "SystemSignalLongSymbol" SG_ 1328 VCSEC_a120_PARTY_stalklessInterf "VCSEC_a120_PARTY_stalklessInterfaces";
BA_ "SystemSignalLongSymbol" SG_ 1328 VCSEC_a120_VEH_estimatedBrakeTem "VCSEC_a120_VEH_estimatedBrakeTemp";
BA_ "SystemSignalLongSymbol" SG_ 1328 VCSEC_a140_cardRmvdB4AuthComplet "VCSEC_a140_cardRmvdB4AuthComplete";
BA_ "SystemSignalLongSymbol" SG_ 1328 VCSEC_a140_cardRmvdB4SndingChaln "VCSEC_a140_cardRmvdB4SndingChalng";
BA_ "SystemSignalLongSymbol" SG_ 1328 VCSEC_a497_centerEndpointMismatc "VCSEC_a497_centerEndpointMismatch";
BA_ "SystemSignalLongSymbol" SG_ 1328 VCSEC_a497_cradleEndpointMismatc "VCSEC_a497_cradleEndpointMismatch";
BA_ "SystemSignalLongSymbol" SG_ 1328 VCSEC_a497_rearLeftEndpointMisma "VCSEC_a497_rearLeftEndpointMismatch";
BA_ "SystemSignalLongSymbol" SG_ 1328 VCSEC_a497_rearRightEndpointMism "VCSEC_a497_rearRightEndpointMismatch";
BA_ "SystemSignalLongSymbol" SG_ 1328 VCSEC_a497_endpointExpectedPcbaI "VCSEC_a497_endpointExpectedPcbaId";
BA_ "SystemSignalLongSymbol" SG_ 1328 VCSEC_a497_endpointExpectedAssem "VCSEC_a497_endpointExpectedAssemblyId";
BA_ "SystemSignalLongSymbol" SG_ 1328 VCSEC_a497_endpointExpectedUsage "VCSEC_a497_endpointExpectedUsageId";
BA_ "SystemSignalLongSymbol" SG_ 1328 VCSEC_a497_endpointActualAssembl "VCSEC_a497_endpointActualAssemblyId";
BA_ "SystemSignalLongSymbol" SG_ 1017 VCSEC_a180_wlistRemovedPermissio "VCSEC_a180_wlistRemovedPermission";
BA_ "SystemSignalLongSymbol" SG_ 1017 VCSEC_a185_passengerEndpointRFMi "VCSEC_a185_passengerEndpointRFMia";
BA_ "SystemSignalLongSymbol" SG_ 1017 VCSEC_a189_protoExpLengthTooLarg "VCSEC_a189_protoExpLengthTooLarge";
BA_ "SystemSignalLongSymbol" SG_ 1017 VCSEC_a200_centerEndpointLostCom "VCSEC_a200_centerEndpointLostComm";
BA_ "SystemSignalLongSymbol" SG_ 1017 VCSEC_a209_BLECenterAssertFailur "VCSEC_a209_BLECenterAssertFailure";
BA_ "SystemSignalLongSymbol" SG_ 1017 VCSEC_a213_gattTimeoutWithExptdC "VCSEC_a213_gattTimeoutWithExptdCount";
BA_ "SystemSignalLongSymbol" SG_ 1017 VCSEC_a214_gattServFalseWaitToBo "VCSEC_a214_gattServFalseWaitToBoot";
BA_ "SystemSignalLongSymbol" SG_ 1017 VCSEC_a215_TPMSUnexpectedDisconn "VCSEC_a215_TPMSUnexpectedDisconnectSensor0";
BA_ "SystemSignalLongSymbol" SG_ 1017 VCSEC_a216_TPMSUnexpectedDisconn "VCSEC_a216_TPMSUnexpectedDisconnectSensor1";
BA_ "SystemSignalLongSymbol" SG_ 1017 VCSEC_a217_TPMSUnexpectedDisconn "VCSEC_a217_TPMSUnexpectedDisconnectSensor2";
BA_ "SystemSignalLongSymbol" SG_ 1017 VCSEC_a218_TPMSUnexpectedDisconn "VCSEC_a218_TPMSUnexpectedDisconnectSensor3";
BA_ "SystemSignalLongSymbol" SG_ 1017 VCSEC_a219_TPMSSensorPairingRemo "VCSEC_a219_TPMSSensorPairingRemoved";
BA_ "SystemSignalLongSymbol" SG_ 1017 VCSEC_a220_TPMSSensorPairingNotC "VCSEC_a220_TPMSSensorPairingNotCompleted";
BA_ "SystemSignalLongSymbol" SG_ 1017 VCSEC_a223_TPMSSensorConnectionC "VCSEC_a223_TPMSSensorConnectionCycling0";
BA_ "SystemSignalLongSymbol" SG_ 1017 VCSEC_a224_TPMSSensorConnectionC "VCSEC_a224_TPMSSensorConnectionCycling1";
BA_ "SystemSignalLongSymbol" SG_ 1017 VCSEC_a225_TPMSSensorConnectionC "VCSEC_a225_TPMSSensorConnectionCycling2";
BA_ "SystemSignalLongSymbol" SG_ 1017 VCSEC_a226_TPMSSensorConnectionC "VCSEC_a226_TPMSSensorConnectionCycling3";
BA_ "SystemSignalLongSymbol" SG_ 1017 VCSEC_a227_connectionWithoutLink "VCSEC_a227_connectionWithoutLinkEvent";
BA_ "SystemSignalLongSymbol" SG_ 1017 VCSEC_a235_presentWithoutHandleP "VCSEC_a235_presentWithoutHandlePull";
BA_ "SystemSignalLongSymbol" SG_ 1017 VCSEC_a236_keyIdentificationMaxA "VCSEC_a236_keyIdentificationMaxAttemptReached";
BA_ "SystemSignalLongSymbol" SG_ 1017 VCSEC_a237_keyNotReadyToReceiveI "VCSEC_a237_keyNotReadyToReceiveIDRequests";
BA_ "SystemSignalLongSymbol" SG_ 1017 VCSEC_a241_TPMSUpdateStartedSens "VCSEC_a241_TPMSUpdateStartedSensor0";
BA_ "SystemSignalLongSymbol" SG_ 1017 VCSEC_a242_TPMSUpdateStartedSens "VCSEC_a242_TPMSUpdateStartedSensor1";
BA_ "SystemSignalLongSymbol" SG_ 1017 VCSEC_a243_TPMSUpdateStartedSens "VCSEC_a243_TPMSUpdateStartedSensor2";
BA_ "SystemSignalLongSymbol" SG_ 1017 VCSEC_a244_TPMSUpdateStartedSens "VCSEC_a244_TPMSUpdateStartedSensor3";
BA_ "SystemSignalLongSymbol" SG_ 1017 VCSEC_a245_TPMSUpdateInterrupted "VCSEC_a245_TPMSUpdateInterruptedSensor0";
BA_ "SystemSignalLongSymbol" SG_ 1017 VCSEC_a246_TPMSUpdateInterrupted "VCSEC_a246_TPMSUpdateInterruptedSensor1";
BA_ "SystemSignalLongSymbol" SG_ 1017 VCSEC_a247_TPMSUpdateInterrupted "VCSEC_a247_TPMSUpdateInterruptedSensor2";
BA_ "SystemSignalLongSymbol" SG_ 1017 VCSEC_a248_TPMSUpdateInterrupted "VCSEC_a248_TPMSUpdateInterruptedSensor3";
BA_ "SystemSignalLongSymbol" SG_ 1017 VCSEC_a249_TPMSUpdateCompleteSen "VCSEC_a249_TPMSUpdateCompleteSensor0";
BA_ "SystemSignalLongSymbol" SG_ 1017 VCSEC_a250_TPMSUpdateCompleteSen "VCSEC_a250_TPMSUpdateCompleteSensor1";
BA_ "SystemSignalLongSymbol" SG_ 1017 VCSEC_a251_TPMSUpdateCompleteSen "VCSEC_a251_TPMSUpdateCompleteSensor2";
BA_ "SystemSignalLongSymbol" SG_ 1017 VCSEC_a252_TPMSUpdateCompleteSen "VCSEC_a252_TPMSUpdateCompleteSensor3";
BA_ "SystemSignalLongSymbol" SG_ 1017 VCSEC_a255_wlistUpdatedPermissio "VCSEC_a255_wlistUpdatedPermission";
BA_ "SystemSignalLongSymbol" SG_ 1017 VCSEC_a256_whitelistOperationFai "VCSEC_a256_whitelistOperationFail";
BA_ "SystemSignalLongSymbol" SG_ 1017 VCSEC_a257_connectedKeyIsExpirin "VCSEC_a257_connectedKeyIsExpiring";
BA_ "SystemSignalLongSymbol" SG_ 1017 VCSEC_a260_prsntPhoneKeyDisconne "VCSEC_a260_prsntPhoneKeyDisconnected";
BA_ "SystemSignalLongSymbol" SG_ 1017 VCSEC_a261_TPMSFactoryLearnActiv "VCSEC_a261_TPMSFactoryLearnActive";
BA_ "SystemSignalLongSymbol" SG_ 1017 VCSEC_a263_dispatchCouldNotBeCom "VCSEC_a263_dispatchCouldNotBeCompleted";
BA_ "SystemSignalLongSymbol" SG_ 1017 VCSEC_a265_tooManyPopulatedMessa "VCSEC_a265_tooManyPopulatedMessage";
BA_ "SystemSignalLongSymbol" SG_ 1017 VCSEC_a266_TPMSSoftWarningFrontL "VCSEC_a266_TPMSSoftWarningFrontLeft";
BA_ "SystemSignalLongSymbol" SG_ 1017 VCSEC_a267_TPMSSoftWarningFrontR "VCSEC_a267_TPMSSoftWarningFrontRight";
BA_ "SystemSignalLongSymbol" SG_ 1017 VCSEC_a268_TPMSSoftWarningRearLe "VCSEC_a268_TPMSSoftWarningRearLeft";
BA_ "SystemSignalLongSymbol" SG_ 1017 VCSEC_a269_TPMSSoftWarningRearRi "VCSEC_a269_TPMSSoftWarningRearRight";
BA_ "SystemSignalLongSymbol" SG_ 1017 VCSEC_a270_TPMSHardWarningFrontL "VCSEC_a270_TPMSHardWarningFrontLeft";
BA_ "SystemSignalLongSymbol" SG_ 1017 VCSEC_a271_TPMSHardWarningFrontR "VCSEC_a271_TPMSHardWarningFrontRight";
BA_ "SystemSignalLongSymbol" SG_ 1017 VCSEC_a272_TPMSHardWarningRearLe "VCSEC_a272_TPMSHardWarningRearLeft";
BA_ "SystemSignalLongSymbol" SG_ 1017 VCSEC_a273_TPMSHardWarningRearRi "VCSEC_a273_TPMSHardWarningRearRight";
BA_ "SystemSignalLongSymbol" SG_ 1017 VCSEC_a274_handlePullWithoutAuth "VCSEC_a274_handlePullWithoutAuth2";
BA_ "SystemSignalLongSymbol" SG_ 1017 VCSEC_a275_childSeatNotConnected "VCSEC_a275_childSeatNotConnectedAtStartOfDrive";
BA_ "SystemSignalLongSymbol" SG_ 1017 VCSEC_a276_childSeatNotConnected "VCSEC_a276_childSeatNotConnectedAtEndOfDrive";
BA_ "SystemSignalLongSymbol" SG_ 1017 VCSEC_a303_KeyfobUpdateInterrupt "VCSEC_a303_KeyfobUpdateInterrupted";
BA_ "SystemSignalLongSymbol" SG_ 1017 VCSEC_a305_ATTFlowControlViolate "VCSEC_a305_ATTFlowControlViolatedC";
BA_ "SystemSignalLongSymbol" SG_ 1017 VCSEC_a306_KeyfobAdvReceivedWhil "VCSEC_a306_KeyfobAdvReceivedWhileConnected";
BA_ "SystemSignalLongSymbol" SG_ 1017 VCSEC_a308_NonConnectableAdvRece "VCSEC_a308_NonConnectableAdvReceived";
BA_ "SystemSignalLongSymbol" SG_ 1017 VCSEC_a309_serviceKeyConditionsN "VCSEC_a309_serviceKeyConditionsNotMet";
BA_ "SystemSignalLongSymbol" SG_ 1017 VCSEC_a310_chargePortFilterFalse "VCSEC_a310_chargePortFilterFalsePositive";
BA_ "SystemSignalLongSymbol" SG_ 1017 VCSEC_a311_moreThanThreeKeysPres "VCSEC_a311_moreThanThreeKeysPresent";
BA_ "SystemSignalLongSymbol" SG_ 1017 VCSEC_a312_unexpectedBLEDisconne "VCSEC_a312_unexpectedBLEDisconnect";
BA_ "SystemSignalLongSymbol" SG_ 1017 VCSEC_a401_rearLeftEndpointLostC "VCSEC_a401_rearLeftEndpointLostComm";
BA_ "SystemSignalLongSymbol" SG_ 1017 VCSEC_a402_rearRightEndpointLost "VCSEC_a402_rearRightEndpointLostComm";
BA_ "SystemSignalLongSymbol" SG_ 1017 VCSEC_a404_NFCCradleEndpointLost "VCSEC_a404_NFCCradleEndpointLostComm";
BA_ "SystemSignalLongSymbol" SG_ 1017 VCSEC_a420_BLEUnexpectedResetNFC "VCSEC_a420_BLEUnexpectedResetNFCCradle";
BA_ "SystemSignalLongSymbol" SG_ 1017 VCSEC_a425_BLENFCCradleAssertFai "VCSEC_a425_BLENFCCradleAssertFailure";
BA_ "SystemSignalLongSymbol" SG_ 1017 VCSEC_a426_BLERearLeftAssertFail "VCSEC_a426_BLERearLeftAssertFailure";
BA_ "SystemSignalLongSymbol" SG_ 1017 VCSEC_a427_BLERearRightAssertFai "VCSEC_a427_BLERearRightAssertFailure";
BA_ "SystemSignalLongSymbol" SG_ 1017 VCSEC_a428_UWBCenterUpdateInterr "VCSEC_a428_UWBCenterUpdateInterrupted";
BA_ "SystemSignalLongSymbol" SG_ 1017 VCSEC_a429_UWBLeftUpdateInterrup "VCSEC_a429_UWBLeftUpdateInterrupted";
BA_ "SystemSignalLongSymbol" SG_ 1017 VCSEC_a430_UWBRightUpdateInterru "VCSEC_a430_UWBRightUpdateInterrupted";
BA_ "SystemSignalLongSymbol" SG_ 1017 VCSEC_a432_UWBRearLeftUpdateInte "VCSEC_a432_UWBRearLeftUpdateInterrupted";
BA_ "SystemSignalLongSymbol" SG_ 1017 VCSEC_a433_UWBRearRightUpdateInt "VCSEC_a433_UWBRearRightUpdateInterrupted";
BA_ "SystemSignalLongSymbol" SG_ 1017 VCSEC_a435_NFCCardPresentWhileCh "VCSEC_a435_NFCCardPresentWhileCharging";
BA_ "SystemSignalLongSymbol" SG_ 1017 VCSEC_a436_uhfHWDoesNotMatchCoun "VCSEC_a436_uhfHWDoesNotMatchCountry";
BA_ "SystemSignalLongSymbol" SG_ 1017 VCSEC_a437_NearbyInteractionDebu "VCSEC_a437_NearbyInteractionDebug";
BA_ "SystemSignalLongSymbol" SG_ 1017 VCSEC_a438_UWBRearUpdateInterrup "VCSEC_a438_UWBRearUpdateInterrupted";
BA_ "SystemSignalLongSymbol" SG_ 1017 VCSEC_a454_TPMSOverPressureWarni "VCSEC_a454_TPMSOverPressureWarning";
BA_ "SystemSignalLongSymbol" SG_ 1017 VCSEC_a455_TPMSOverPressureWarni "VCSEC_a455_TPMSOverPressureWarningFrontLeft";
BA_ "SystemSignalLongSymbol" SG_ 1017 VCSEC_a456_TPMSOverPressureWarni "VCSEC_a456_TPMSOverPressureWarningFrontRight";
BA_ "SystemSignalLongSymbol" SG_ 1017 VCSEC_a457_TPMSOverPressureWarni "VCSEC_a457_TPMSOverPressureWarningRearLeft";
BA_ "SystemSignalLongSymbol" SG_ 1017 VCSEC_a458_TPMSOverPressureWarni "VCSEC_a458_TPMSOverPressureWarningRearRight";
BA_ "SystemSignalLongSymbol" SG_ 1017 VCSEC_a459_TPMSCertCheckFailedSe "VCSEC_a459_TPMSCertCheckFailedSensor0";
BA_ "SystemSignalLongSymbol" SG_ 1017 VCSEC_a460_TPMSCertCheckFailedSe "VCSEC_a460_TPMSCertCheckFailedSensor1";
BA_ "SystemSignalLongSymbol" SG_ 1017 VCSEC_a461_TPMSCertCheckFailedSe "VCSEC_a461_TPMSCertCheckFailedSensor2";
BA_ "SystemSignalLongSymbol" SG_ 1017 VCSEC_a462_TPMSCertCheckFailedSe "VCSEC_a462_TPMSCertCheckFailedSensor3";
BA_ "SystemSignalLongSymbol" SG_ 1017 VCSEC_a465_UWBRearLeftKeyVerific "VCSEC_a465_UWBRearLeftKeyVerificationFailure";
BA_ "SystemSignalLongSymbol" SG_ 1017 VCSEC_a466_UWBRearRightKeyVerifi "VCSEC_a466_UWBRearRightKeyVerificationFailure";
BA_ "SystemSignalLongSymbol" SG_ 1017 VCSEC_a467_UWBCenterKeyVerificat "VCSEC_a467_UWBCenterKeyVerificationFailure";
BA_ "SystemSignalLongSymbol" SG_ 1017 VCSEC_a468_UWBRearKeyVerificatio "VCSEC_a468_UWBRearKeyVerificationFailure";
BA_ "SystemSignalLongSymbol" SG_ 1017 VCSEC_a469_UWBLeftKeyVerificatio "VCSEC_a469_UWBLeftKeyVerificationFailure";
BA_ "SystemSignalLongSymbol" SG_ 1017 VCSEC_a470_UWBRightKeyVerificati "VCSEC_a470_UWBRightKeyVerificationFailure";
BA_ "SystemSignalLongSymbol" SG_ 1017 VCSEC_a472_peerRemovedInformatio "VCSEC_a472_peerRemovedInformation";
BA_ "SystemSignalLongSymbol" SG_ 1017 VCSEC_a473_handlePullWithoutAuth "VCSEC_a473_handlePullWithoutAuth3";
BA_ "SystemSignalLongSymbol" SG_ 1017 VCSEC_a474_handlePullWithoutAuth "VCSEC_a474_handlePullWithoutAuth4";
BA_ "SystemSignalLongSymbol" SG_ 1017 VCSEC_a475_handlePullWithoutAuth "VCSEC_a475_handlePullWithoutAuth5";
BA_ "SystemSignalLongSymbol" SG_ 1017 VCSEC_a476_handlePullWithoutAuth "VCSEC_a476_handlePullWithoutAuth6";
BA_ "SystemSignalLongSymbol" SG_ 1017 VCSEC_a478_handlePullWithoutAuth "VCSEC_a478_handlePullWithoutAuth7";
BA_ "SystemSignalLongSymbol" SG_ 1017 VCSEC_a479_handlePullWithoutAuth "VCSEC_a479_handlePullWithoutAuthNIStateDev0";
BA_ "SystemSignalLongSymbol" SG_ 1017 VCSEC_a480_handlePullWithoutAuth "VCSEC_a480_handlePullWithoutAuthNIStateDev1";
BA_ "SystemSignalLongSymbol" SG_ 1017 VCSEC_a481_handlePullWithoutAuth "VCSEC_a481_handlePullWithoutAuthNIStateDev2";
BA_ "SystemSignalLongSymbol" SG_ 1017 VCSEC_a483_highThermalGradiantDe "VCSEC_a483_highThermalGradiantDetected";
BA_ "SystemSignalLongSymbol" SG_ 1017 VCSEC_a484_UWBLeftUpdateTriggere "VCSEC_a484_UWBLeftUpdateTriggered";
BA_ "SystemSignalLongSymbol" SG_ 1017 VCSEC_a485_UWBCenterUpdateTrigge "VCSEC_a485_UWBCenterUpdateTriggered";
BA_ "SystemSignalLongSymbol" SG_ 1017 VCSEC_a486_UWBRightUpdateTrigger "VCSEC_a486_UWBRightUpdateTriggered";
BA_ "SystemSignalLongSymbol" SG_ 1017 VCSEC_a489_UWBRearLeftUpdateTrig "VCSEC_a489_UWBRearLeftUpdateTriggered";
BA_ "SystemSignalLongSymbol" SG_ 1017 VCSEC_a490_UWBRearRightUpdateTri "VCSEC_a490_UWBRearRightUpdateTriggered";
BA_ "SystemSignalLongSymbol" SG_ 1017 VCSEC_a494_UWBRearUpdateTriggere "VCSEC_a494_UWBRearUpdateTriggered";
BA_ "SystemSignalLongSymbol" SG_ 1017 VCSEC_a495_handlePullWithoutAuth "VCSEC_a495_handlePullWithoutAuth_iOS";
BA_ "SystemSignalLongSymbol" SG_ 1017 VCSEC_a496_handlePullWithoutAuth "VCSEC_a496_handlePullWithoutAuth_Android";
BA_ "SystemSignalLongSymbol" SG_ 1017 VCSEC_a497_incorrectEndpointInst "VCSEC_a497_incorrectEndpointInstallation";
BA_ "SystemSignalLongSymbol" SG_ 1017 VCSEC_a503_CANMsgMACVerification "VCSEC_a503_CANMsgMACVerificationFailure";
BA_ "SystemSignalLongSymbol" SG_ 1017 VCSEC_a504_CANMsgMACVerification "VCSEC_a504_CANMsgMACVerificationKeyNotProvisioned";
BA_ "SystemSignalLongSymbol" SG_ 1017 VCSEC_a505_CANMsgMACVerification "VCSEC_a505_CANMsgMACVerificationKeyMismatch";
BA_ "SystemSignalLongSymbol" SG_ 1017 VCSEC_a513_TPMSConnectionStatsNo "VCSEC_a513_TPMSConnectionStatsNotReceived0";
BA_ "SystemSignalLongSymbol" SG_ 1017 VCSEC_a514_TPMSConnectionStatsNo "VCSEC_a514_TPMSConnectionStatsNotReceived1";
BA_ "SystemSignalLongSymbol" SG_ 1017 VCSEC_a515_TPMSConnectionStatsNo "VCSEC_a515_TPMSConnectionStatsNotReceived2";
BA_ "SystemSignalLongSymbol" SG_ 1017 VCSEC_a516_TPMSConnectionStatsNo "VCSEC_a516_TPMSConnectionStatsNotReceived3";
BA_ "SystemSignalLongSymbol" SG_ 1017 VCSEC_a517_TPMSOutOfRangePressur "VCSEC_a517_TPMSOutOfRangePressureReceived0";
BA_ "SystemSignalLongSymbol" SG_ 1017 VCSEC_a518_TPMSOutOfRangePressur "VCSEC_a518_TPMSOutOfRangePressureReceived1";
BA_ "SystemSignalLongSymbol" SG_ 1017 VCSEC_a519_TPMSOutOfRangePressur "VCSEC_a519_TPMSOutOfRangePressureReceived2";
BA_ "SystemSignalLongSymbol" SG_ 1017 VCSEC_a520_TPMSOutOfRangePressur "VCSEC_a520_TPMSOutOfRangePressureReceived3";
BA_ "SystemSignalLongSymbol" SG_ 1017 VCSEC_a521_TPMSSensorLowConfiden "VCSEC_a521_TPMSSensorLowConfidenceSensorLocalization0";
BA_ "SystemSignalLongSymbol" SG_ 1017 VCSEC_a522_TPMSSensorLowConfiden "VCSEC_a522_TPMSSensorLowConfidenceSensorLocalization1";
BA_ "SystemSignalLongSymbol" SG_ 1017 VCSEC_a523_TPMSSensorLowConfiden "VCSEC_a523_TPMSSensorLowConfidenceSensorLocalization2";
BA_ "SystemSignalLongSymbol" SG_ 1017 VCSEC_a524_TPMSSensorLowConfiden "VCSEC_a524_TPMSSensorLowConfidenceSensorLocalization3";
BA_ "SystemSignalLongSymbol" SG_ 1017 VCSEC_a525_TPMSLocalizationMulti "VCSEC_a525_TPMSLocalizationMultipleSensorsForPositionFL";
BA_ "SystemSignalLongSymbol" SG_ 1017 VCSEC_a526_TPMSLocalizationMulti "VCSEC_a526_TPMSLocalizationMultipleSensorsForPositionFR";
BA_ "SystemSignalLongSymbol" SG_ 1017 VCSEC_a527_TPMSLocalizationMulti "VCSEC_a527_TPMSLocalizationMultipleSensorsForPositionRL";
BA_ "SystemSignalLongSymbol" SG_ 1017 VCSEC_a528_TPMSLocalizationMulti "VCSEC_a528_TPMSLocalizationMultipleSensorsForPositionRR";
BA_ "SystemSignalLongSymbol" SG_ 1017 VCSEC_a529_TPMSTireServiceDetect "VCSEC_a529_TPMSTireServiceDetected";
BA_ "Confidence" SG_ 825 VCSEC_BLEConnectionCounter 1;
BA_ "Confidence" SG_ 825 VCSEC_authRejectionReason 1;
BA_ "Confidence" SG_ 825 VCSEC_operationMode 1;
BA_ "Confidence" SG_ 825 VCSEC_vehicleLockStatus 1;
BA_ "Confidence" SG_ 825 VCSEC_authenticationStatus 1;
BA_ "Confidence" SG_ 825 VCSEC_chargePortLockStatus 1;
BA_ "Confidence" SG_ 825 VCSEC_leftFrontLockStatus 1;
BA_ "Confidence" SG_ 825 VCSEC_leftRearLockStatus 1;
BA_ "Confidence" SG_ 825 VCSEC_rightFrontLockStatus 1;
BA_ "Confidence" SG_ 825 VCSEC_rightRearLockStatus 1;
BA_ "Confidence" SG_ 825 VCSEC_trunkLockStatus 1;
BA_ "Confidence" SG_ 825 VCSEC_lockRequestType 1;
BA_ "Confidence" SG_ 825 VCSEC_summonRequest 1;
BA_ "Confidence" SG_ 825 VCSEC_3rdPartyPLGRequest 1;
BA_ "Confidence" SG_ 825 VCSEC_3rdPartyFrunkPLGRequest 1;
BA_ "Confidence" SG_ 825 VCSEC_MCUCommandType 1;
BA_ "Confidence" SG_ 825 VCSEC_frunkLockStatus 1;
BA_ "Confidence" SG_ 825 VCSEC_isKeyWithinSummonRange 1;
BA_ "Confidence" SG_ 825 VCSEC_isBLEDeviceWithinSummonRan 1;
BA_ "SystemSignalLongSymbol" SG_ 825 VCSEC_isBLEDeviceWithinSummonRan "VCSEC_isBLEDeviceWithinSummonRange";
BA_ "Confidence" SG_ 825 VCSEC_alarmStatus 1;
BA_ "Confidence" SG_ 825 VCSEC_immobilizerState 1;
BA_ "Confidence" SG_ 825 VCSEC_lockIndicationRequest 1;
BA_ "Confidence" SG_ 825 VCSEC_simpleLockStatus 1;
BA_ "Confidence" SG_ 825 VCSEC_authRequested 1;
BA_ "Confidence" SG_ 825 VCSEC_remoteStartActive 1;
BA_ "Confidence" SG_ 1817 VCSEC_walkAwayLockKeyState 1;
BA_ "Confidence" SG_ 1817 VCSEC_walkAwayLockState 1;
BA_ "Confidence" SG_ 1817 VCSEC_rssi0WLEntry 1;
BA_ "Confidence" SG_ 1817 VCSEC_endpointLayout 1;
BA_ "Confidence" SG_ 1817 VCSEC_rssi1WLEntry 1;
BA_ "Confidence" SG_ 1817 VCSEC_rssi2WLEntry 1;
BA_ "Confidence" SG_ 1817 VCSEC_walkUpUnlockState 1;
BA_ "Confidence" SG_ 1817 VCSEC_pollingReason 1;
BA_ "Confidence" SG_ 1817 VCSEC_numberOfPubKeysOnWhitelist 1;
BA_ "Confidence" SG_ 1817 VCSEC_thermalDetectState 1;
BA_ "SystemSignalLongSymbol" SG_ 1817 VCSEC_chargeHandleMitigationActi "VCSEC_chargeHandleMitigationActive";
BA_ "SystemSignalLongSymbol" SG_ 1817 VCSEC_smartTrunkMitigatedKeyCoun "VCSEC_smartTrunkMitigatedKeyCount";
BA_ "Confidence" SG_ 1817 VCSEC_UWB3WLEntry 1;
BA_ "Confidence" SG_ 1817 VCSEC_device0Offset 1;
BA_ "Confidence" SG_ 1817 VCSEC_device1Offset 1;
BA_ "Confidence" SG_ 1817 VCSEC_device2Offset 1;
BA_ "Confidence" SG_ 1817 VCSEC_connection0BondingState 1;
BA_ "Confidence" SG_ 1817 VCSEC_connection1BondingState 1;
BA_ "Confidence" SG_ 1817 VCSEC_connection2BondingState 1;
BA_ "Confidence" SG_ 1817 VCSEC_connection0UWBAvailability 1;
BA_ "Confidence" SG_ 1817 VCSEC_connection1UWBAvailability 1;
BA_ "Confidence" SG_ 1817 VCSEC_connection2UWBAvailability 1;
BA_ "Confidence" SG_ 1817 VCSEC_NISessionStateCenter0 1;
BA_ "Confidence" SG_ 1817 VCSEC_NISessionStateLeft0 1;
BA_ "Confidence" SG_ 1817 VCSEC_NISessionStateRight0 1;
BA_ "Confidence" SG_ 1817 VCSEC_NISessionStateRearLeft0 1;
BA_ "Confidence" SG_ 1817 VCSEC_NISessionStateRearRight0 1;
BA_ "Confidence" SG_ 1817 VCSEC_NISessionStateRear0 1;
BA_ "Confidence" SG_ 1817 VCSEC_NISessionStateCenter1 1;
BA_ "Confidence" SG_ 1817 VCSEC_NISessionStateLeft1 1;
BA_ "Confidence" SG_ 1817 VCSEC_NISessionStateRight1 1;
BA_ "Confidence" SG_ 1817 VCSEC_NISessionStateRearLeft1 1;
BA_ "Confidence" SG_ 1817 VCSEC_NISessionStateRearRight1 1;
BA_ "Confidence" SG_ 1817 VCSEC_NISessionStateRear1 1;
BA_ "Confidence" SG_ 1817 VCSEC_NISessionStateCenter2 1;
BA_ "Confidence" SG_ 1817 VCSEC_NISessionStateLeft2 1;
BA_ "Confidence" SG_ 1817 VCSEC_NISessionStateRight2 1;
BA_ "Confidence" SG_ 1817 VCSEC_NISessionStateRearLeft2 1;
BA_ "Confidence" SG_ 1817 VCSEC_NISessionStateRearRight2 1;
BA_ "Confidence" SG_ 1817 VCSEC_NISessionStateRear2 1;
BA_ "Confidence" SG_ 1817 VCSEC_NISessionStateLeft3 1;
BA_ "Confidence" SG_ 1817 VCSEC_NISessionStateRight3 1;
BA_ "Confidence" SG_ 1817 VCSEC_NISessionStateRearRight3 1;
BA_ "Confidence" SG_ 1817 VCSEC_NISessionStateRearLeft3 1;
BA_ "Confidence" SG_ 1817 VCSEC_NISessionStateCenter3 1;
BA_ "Confidence" SG_ 793 VCSEC_infoBuildType 1;
VAL_ 825 VCSEC_authRejectionReason 5 "AUTHENTICATIONREJECTION_DEVICE_NOT_UNLOCKED_ON_WRIST" 4 "AUTHENTICATIONREJECTION_PASSIVE_DISABLED_AUTOMATION" 3 "AUTHENTICATIONREJECTION_NO_TOKEN" 2 "AUTHENTICATIONREJECTION_PASSIVE_DISABLED" 1 "AUTHENTICATIONREJECTION_DEVICE_STATIONARY" 0 "AUTHENTICATIONREJECTION_NONE" ;
VAL_ 825 VCSEC_operationMode 2 "OPERATION_MODE_FLEET" 1 "OPERATION_MODE_OWNER" 0 "OPERATION_MODE_UNKNOWN" ;
VAL_ 825 VCSEC_vehicleLockStatus 15 "LOCK_STATUS_PASSIVE_INTERNAL_LOCKED" 14 "LOCK_STATUS_PASSIVE_INTERNAL_UNLOCKED" 13 "LOCK_STATUS_CRASH_UNLOCKED" 12 "LOCK_STATUS_ACTIVE_REMOTE_LOCKED" 11 "LOCK_STATUS_ACTIVE_REMOTE_UNLOCKED" 10 "LOCK_STATUS_ACTIVE_UI_LOCKED" 9 "LOCK_STATUS_ACTIVE_UI_UNLOCKED" 8 "LOCK_STATUS_ACTIVE_BLE_LOCKED" 7 "LOCK_STATUS_ACTIVE_BLE_UNLOCKED" 6 "LOCK_STATUS_ACTIVE_SELECTIVE_UNLOCKED" 5 "LOCK_STATUS_PASSIVE_BLE_LOCKED" 4 "LOCK_STATUS_PASSIVE_BLE_UNLOCKED" 3 "LOCK_STATUS_PASSIVE_SELECTIVE_UNLOCKED" 2 "LOCK_STATUS_ACTIVE_NFC_LOCKED" 1 "LOCK_STATUS_ACTIVE_NFC_UNLOCKED" 0 "LOCK_STATUS_SNA" ;
VAL_ 825 VCSEC_authenticationStatus 2 "AUTHENTICATION_AUTHENTICATED_FOR_DRIVE" 1 "AUTHENTICATION_AUTHENTICATED_FOR_UNLOCK" 0 "AUTHENTICATION_NONE" ;
VAL_ 825 VCSEC_chargePortLockStatus 1 "CLOSURE_LOCKED" 0 "CLOSURE_UNLOCKED" ;
VAL_ 825 VCSEC_leftFrontLockStatus 1 "CLOSURE_LOCKED" 0 "CLOSURE_UNLOCKED" ;
VAL_ 825 VCSEC_leftRearLockStatus 1 "CLOSURE_LOCKED" 0 "CLOSURE_UNLOCKED" ;
VAL_ 825 VCSEC_rightFrontLockStatus 1 "CLOSURE_LOCKED" 0 "CLOSURE_UNLOCKED" ;
VAL_ 825 VCSEC_rightRearLockStatus 1 "CLOSURE_LOCKED" 0 "CLOSURE_UNLOCKED" ;
VAL_ 825 VCSEC_trunkLockStatus 1 "CLOSURE_LOCKED" 0 "CLOSURE_UNLOCKED" ;
VAL_ 825 VCSEC_lockRequestType 21 "LOCK_REQUEST_KEYFOB_OPEN_DOOR_REQUEST" 20 "LOCK_REQUEST_PASSIVE_AUTO_PRESENT_DOOR_REQUEST" 19 "LOCK_REQUEST_PASSIVE_INTERNAL_LOCK_PROMOTION" 18 "LOCK_REQUEST_ACTIVE_BLE_LOCK" 17 "LOCK_REQUEST_ACTIVE_BLE_UNLOCK" 16 "LOCK_REQUEST_ACTIVE_NFC_LOCK" 15 "LOCK_REQUEST_ACTIVE_NFC_UNLOCK" 14 "LOCK_REQUEST_ACTIVE_REMOTE_LOCK" 13 "LOCK_REQUEST_ACTIVE_REMOTE_UNLOCK" 12 "LOCK_REQUEST_ACTIVE_UI_BUTTON_LOCK" 11 "LOCK_REQUEST_ACTIVE_UI_BUTTON_UNLOCK" 10 "LOCK_REQUEST_CRASH_UNLOCK" 9 "LOCK_REQUEST_PASSIVE_BLE_LOCK" 8 "LOCK_REQUEST_PASSIVE_BLE_INTERIOR_HANDLE_UNLOCK" 7 "LOCK_REQUEST_PASSIVE_BLE_EXTERIOR_HANDLE_UNLOCK" 6 "LOCK_REQUEST_PASSIVE_BLE_EXTERIOR_CHARGEHANDLEBUTTON_UNLOCK" 5 "LOCK_REQUEST_PASSIVE_BLE_WALKUP_UNLOCK" 4 "LOCK_REQUEST_PASSIVE_DRIVE_AWAY_LOCK" 3 "LOCK_REQUEST_PASSIVE_INTERNAL_HANDLE_UNLOCK" 2 "LOCK_REQUEST_PASSIVE_PARKBUTTON_UNLOCK" 1 "LOCK_REQUEST_PASSIVE_SHIFT_TO_P_UNLOCK" 0 "LOCK_REQUEST_NONE" ;
VAL_ 825 VCSEC_summonRequest 5 "SUMMON_REQUEST_SNA" 4 "SUMMON_REQUEST_STOP" 3 "SUMMON_REQUEST_BACKWARD" 2 "SUMMON_REQUEST_FORWARD" 1 "SUMMON_REQUEST_PRIME" 0 "SUMMON_REQUEST_IDLE" ;
VAL_ 825 VCSEC_3rdPartyPLGRequest 3 "CLOSURE_REQUEST_SNA" 2 "CLOSURE_REQUEST_STOP" 1 "CLOSURE_REQUEST_MOVE" 0 "CLOSURE_REQUEST_NONE" ;
VAL_ 825 VCSEC_3rdPartyFrunkPLGRequest 3 "CLOSURE_REQUEST_SNA" 2 "CLOSURE_REQUEST_STOP" 1 "CLOSURE_REQUEST_MOVE" 0 "CLOSURE_REQUEST_NONE" ;
VAL_ 825 VCSEC_MCUCommandType 5 "MCU_COMMAND_COMMAND5" 4 "MCU_COMMAND_COMMAND4" 3 "MCU_COMMAND_COMMAND3" 2 "MCU_COMMAND_REMOTE_START" 1 "MCU_COMMAND_REMOTE_UNLOCK" 0 "MCU_COMMAND_NONE" ;
VAL_ 825 VCSEC_frunkLockStatus 1 "CLOSURE_LOCKED" 0 "CLOSURE_UNLOCKED" ;
VAL_ 825 VCSEC_alarmStatus 15 "ALARM_STATUS_SNA" 7 "ALARM_STATUS_DEFAULT" 6 "ALARM_STATUS_IMMINENT" 5 "ALARM_STATUS_TRIGGERED_FLASH_INACTIVE" 4 "ALARM_STATUS_ERROR" 3 "ALARM_STATUS_TRIGGERED_FLASH_ACTIVE" 2 "ALARM_STATUS_PARTIAL_ARMED" 1 "ALARM_STATUS_ARMED" 0 "ALARM_STATUS_DISARMED" ;
VAL_ 825 VCSEC_immobilizerState 6 "IMMOBILIZER_STATE_IMMOBILIZED" 5 "IMMOBILIZER_STATE_SEND_NO_GO_AUTH_RESPONSE" 4 "IMMOBILIZER_STATE_SEND_AUTH_RESPONSE" 3 "IMMOBILIZER_STATE_ENCRYPT" 2 "IMMOBILIZER_STATE_ENCRYPT_BEGIN" 1 "IMMOBILIZER_STATE_PREPARE" 0 "IMMOBILIZER_STATE_IDLE" ;
VAL_ 825 VCSEC_lockIndicationRequest 4 "INDICATION_HOLD" 3 "INDICATION_TRIPLE" 2 "INDICATION_DOUBLE" 1 "INDICATION_SINGLE" 0 "INDICATION_NONE_SNA" ;
VAL_ 825 VCSEC_simpleLockStatus 2 "SIMPLE_LOCK_STATUS_LOCKED" 1 "SIMPLE_LOCK_STATUS_UNLOCKED" 0 "SIMPLE_LOCK_STATUS_SNA" ;
VAL_ 825 VCSEC_remoteStartActive 3 "VCSEC_REMOTE_START_TYPE_SIGNED_COMMAND_PIN_REQUIRED" 2 "VCSEC_REMOTE_START_TYPE_SIGNED_COMMAND" 1 "VCSEC_REMOTE_START_TYPE_LEGACY" 0 "VCSEC_REMOTE_START_TYPE_NONE" ;
VAL_ 1817 VCSEC_walkAwayLockKeyState 3 "SECURITY_WALKAWAYLOCKING_NO_KEYS_PRESENT" 2 "SECURITY_WALKAWAYLOCKING_KEY_WAIT_FOR_NO_KEYS_PRESENT" 1 "SECURITY_WALKAWAYLOCKING_KEY_STATE_AWAITING_KEY_LEAVING" 0 "SECURITY_WALKAWAYLOCKING_KEY_STATE_IDLE" ;
VAL_ 1817 VCSEC_walkAwayLockState 5 "SECURITY_WALKAWAYLOCKING_STATE_INHIBITED" 4 "SECURITY_WALKAWAYLOCKING_STATE_DISABLED_DUE_TO_KEY_PRESENT" 3 "SECURITY_WALKAWAYLOCKING_STATE_LOCK_DESIRED" 2 "SECURITY_WALKAWAYLOCKING_STATE_WAITING_FOR_KEY_LEAVING" 1 "SECURITY_WALKAWAYLOCKING_STATE_WALK_AWAY_LOCK_ARMING" 0 "SECURITY_WALKAWAYLOCKING_STATE_IDLE" ;
VAL_ 1817 VCSEC_endpointLayout 2 "VCSEC_ENDPOINT_LAYOUT_3" 1 "VCSEC_ENDPOINT_LAYOUT_2" 0 "VCSEC_ENDPOINT_LAYOUT_1" ;
VAL_ 1817 VCSEC_walkUpUnlockState 4 "WALK_UP_UNLOCK_STATE_DISABLED" 3 "WALK_UP_UNLOCK_STATE_UNLOCK_DESIRED" 2 "WALK_UP_UNLOCK_STATE_AWAITING_KEY" 1 "WALK_UP_UNLOCK_STATE_ARMING" 0 "WALK_UP_UNLOCK_STATE_IDLE" ;
VAL_ 1817 VCSEC_pollingReason 13 "POLLINGREASON_MULTIPLE" 12 "POLLINGREASON_AUTOPILOT" 11 "POLLINGREASON_APPROACH_LIGHTING" 10 "POLLINGREASON_AUTO_PRESENT_HANDLES" 9 "POLLINGREASON_AUTORELOCK" 8 "POLLINGREASON_DRIVE_AWAY_CHECK_FOR_KEY" 7 "POLLINGREASON_AUTO_PRESENT_DOOR" 6 "POLLINGREASON_ACCESSORY_RAIL" 5 "POLLINGREASON_WALK_UP_UNLOCK" 4 "POLLINGREASON_WALK_AWAY_LOCK" 3 "POLLINGREASON_PASSIVE_UNLOCK" 2 "POLLINGREASON_PASSIVE_AUTHENTICATION" 1 "POLLINGREASON_IMMOBILIZER" 0 "POLLINGREASON_NONE" ;
VAL_ 1817 VCSEC_thermalDetectState 3 "VCSEC_THERMALDETECTIONSTATE_TRIPPED" 2 "VCSEC_THERMALDETECTIONSTATE_CONFIRMING_THRESHOLD" 1 "VCSEC_THERMALDETECTIONSTATE_MONITORING" 0 "VCSEC_THERMALDETECTIONSTATE_DISABLED" ;
VAL_ 1817 VCSEC_connection0BondingState 15 "WAIT_FOR_BOND_REJECTED" 14 "BOND" 13 "WAIT_FOR_BOND_REQUEST" 12 "BOND_FAILURE" 11 "PAIRING_REQUESTED" 10 "REJECT_BOND" 9 "WAIT_FOR_SIGNABLE" 8 "SEND_SIGNABLE" 7 "WAIT_FOR_BOND" 6 "WAIT_FOR_PAIRING" 5 "WAIT_FOR_AUTHENTICATE" 4 "SHOULD_BE_BONDED" 3 "BONDED" 2 "NOT_BONDED" 1 "CONNECTED" 0 "NOT_CONNECTED" ;
VAL_ 1817 VCSEC_connection1BondingState 15 "WAIT_FOR_BOND_REJECTED" 14 "BOND" 13 "WAIT_FOR_BOND_REQUEST" 12 "BOND_FAILURE" 11 "PAIRING_REQUESTED" 10 "REJECT_BOND" 9 "WAIT_FOR_SIGNABLE" 8 "SEND_SIGNABLE" 7 "WAIT_FOR_BOND" 6 "WAIT_FOR_PAIRING" 5 "WAIT_FOR_AUTHENTICATE" 4 "SHOULD_BE_BONDED" 3 "BONDED" 2 "NOT_BONDED" 1 "CONNECTED" 0 "NOT_CONNECTED" ;
VAL_ 1817 VCSEC_connection2BondingState 15 "WAIT_FOR_BOND_REJECTED" 14 "BOND" 13 "WAIT_FOR_BOND_REQUEST" 12 "BOND_FAILURE" 11 "PAIRING_REQUESTED" 10 "REJECT_BOND" 9 "WAIT_FOR_SIGNABLE" 8 "SEND_SIGNABLE" 7 "WAIT_FOR_BOND" 6 "WAIT_FOR_PAIRING" 5 "WAIT_FOR_AUTHENTICATE" 4 "SHOULD_BE_BONDED" 3 "BONDED" 2 "NOT_BONDED" 1 "CONNECTED" 0 "NOT_CONNECTED" ;
VAL_ 1817 VCSEC_connection0UWBAvailability 16 "UNAVAILABLE_UNKNOWN_REASON" 15 "UNAVAILABLE_UWB_DISABLED_BY_USER" 14 "PHONE_ERROR" 13 "RADIOCONFIG_NOT_READY" 12 "UPDATE_NOT_READY" 11 "GENEALOGY_NOT_READY" 10 "BLE_CHIP_NOT_READY" 9 "UWB_CHIP_NOT_READY" 8 "UNAVAILABLE_NOT_SELECTED" 7 "UWB_NOT_ENABLED_ON_THE_VEHICLE" 6 "AVAILBLE_BUT_NOT_GAP_BONDED" 5 "UNAVAILABLE_PERMISSION_DENIED" 4 "UNAVAILABLE_UNSUPPORTED_DEVICE" 3 "TEMPORARILY_UNAVAILABLE" 2 "AVAILABLE_BUT_NOT_RANGING_ON_DRIVER_ENDPOINT" 1 "AVAILABLE" 0 "NONE" ;
VAL_ 1817 VCSEC_connection1UWBAvailability 16 "UNAVAILABLE_UNKNOWN_REASON" 15 "UNAVAILABLE_UWB_DISABLED_BY_USER" 14 "PHONE_ERROR" 13 "RADIOCONFIG_NOT_READY" 12 "UPDATE_NOT_READY" 11 "GENEALOGY_NOT_READY" 10 "BLE_CHIP_NOT_READY" 9 "UWB_CHIP_NOT_READY" 8 "UNAVAILABLE_NOT_SELECTED" 7 "UWB_NOT_ENABLED_ON_THE_VEHICLE" 6 "AVAILBLE_BUT_NOT_GAP_BONDED" 5 "UNAVAILABLE_PERMISSION_DENIED" 4 "UNAVAILABLE_UNSUPPORTED_DEVICE" 3 "TEMPORARILY_UNAVAILABLE" 2 "AVAILABLE_BUT_NOT_RANGING_ON_DRIVER_ENDPOINT" 1 "AVAILABLE" 0 "NONE" ;
VAL_ 1817 VCSEC_connection2UWBAvailability 16 "UNAVAILABLE_UNKNOWN_REASON" 15 "UNAVAILABLE_UWB_DISABLED_BY_USER" 14 "PHONE_ERROR" 13 "RADIOCONFIG_NOT_READY" 12 "UPDATE_NOT_READY" 11 "GENEALOGY_NOT_READY" 10 "BLE_CHIP_NOT_READY" 9 "UWB_CHIP_NOT_READY" 8 "UNAVAILABLE_NOT_SELECTED" 7 "UWB_NOT_ENABLED_ON_THE_VEHICLE" 6 "AVAILBLE_BUT_NOT_GAP_BONDED" 5 "UNAVAILABLE_PERMISSION_DENIED" 4 "UNAVAILABLE_UNSUPPORTED_DEVICE" 3 "TEMPORARILY_UNAVAILABLE" 2 "AVAILABLE_BUT_NOT_RANGING_ON_DRIVER_ENDPOINT" 1 "AVAILABLE" 0 "NONE" ;
VAL_ 1817 VCSEC_NISessionStateCenter0 21 "COUNT" 20 "SESSION_INITIATE" 19 "WAIT_FOR_SESSION_INITIATE" 18 "WAIT_FOR_SESSION_STATE_ACTIVE" 17 "UNRECOVERABLE_DEVICE_ERROR" 16 "ERROR_WAIT_FOR_RESET" 15 "WAIT_FOR_RETRY_AFTER_ERROR" 14 "WAIT_FOR_SESSION_DEINIT" 13 "DEINIT_SESSION" 12 "WAIT_FOR_SESSION_STOP" 11 "STOP_SESSION" 10 "RANGING" 9 "WAIT_FOR_RANGING_STARTED_CONFIRMATION" 8 "WAIT_FOR_APPLE_SESSION_INITIATE" 7 "APPLE_SESSION_INITIATE" 6 "WAIT_FOR_APPLE_SHAREABLE_CONFIGURATION_DATA" 5 "SEND_CONFIGURATION_DATA_TO_PHONE" 4 "WAIT_FOR_CONFIGURATION_DATA" 3 "REQUEST_CONFIGURATION_DATA" 2 "WAIT_FOR_CORE_CONFIG_DATA" 1 "APPLY_CORE_CONFIG_DATA" 0 "IDLE" ;
VAL_ 1817 VCSEC_NISessionStateLeft0 21 "COUNT" 20 "SESSION_INITIATE" 19 "WAIT_FOR_SESSION_INITIATE" 18 "WAIT_FOR_SESSION_STATE_ACTIVE" 17 "UNRECOVERABLE_DEVICE_ERROR" 16 "ERROR_WAIT_FOR_RESET" 15 "WAIT_FOR_RETRY_AFTER_ERROR" 14 "WAIT_FOR_SESSION_DEINIT" 13 "DEINIT_SESSION" 12 "WAIT_FOR_SESSION_STOP" 11 "STOP_SESSION" 10 "RANGING" 9 "WAIT_FOR_RANGING_STARTED_CONFIRMATION" 8 "WAIT_FOR_APPLE_SESSION_INITIATE" 7 "APPLE_SESSION_INITIATE" 6 "WAIT_FOR_APPLE_SHAREABLE_CONFIGURATION_DATA" 5 "SEND_CONFIGURATION_DATA_TO_PHONE" 4 "WAIT_FOR_CONFIGURATION_DATA" 3 "REQUEST_CONFIGURATION_DATA" 2 "WAIT_FOR_CORE_CONFIG_DATA" 1 "APPLY_CORE_CONFIG_DATA" 0 "IDLE" ;
VAL_ 1817 VCSEC_NISessionStateRight0 21 "COUNT" 20 "SESSION_INITIATE" 19 "WAIT_FOR_SESSION_INITIATE" 18 "WAIT_FOR_SESSION_STATE_ACTIVE" 17 "UNRECOVERABLE_DEVICE_ERROR" 16 "ERROR_WAIT_FOR_RESET" 15 "WAIT_FOR_RETRY_AFTER_ERROR" 14 "WAIT_FOR_SESSION_DEINIT" 13 "DEINIT_SESSION" 12 "WAIT_FOR_SESSION_STOP" 11 "STOP_SESSION" 10 "RANGING" 9 "WAIT_FOR_RANGING_STARTED_CONFIRMATION" 8 "WAIT_FOR_APPLE_SESSION_INITIATE" 7 "APPLE_SESSION_INITIATE" 6 "WAIT_FOR_APPLE_SHAREABLE_CONFIGURATION_DATA" 5 "SEND_CONFIGURATION_DATA_TO_PHONE" 4 "WAIT_FOR_CONFIGURATION_DATA" 3 "REQUEST_CONFIGURATION_DATA" 2 "WAIT_FOR_CORE_CONFIG_DATA" 1 "APPLY_CORE_CONFIG_DATA" 0 "IDLE" ;
VAL_ 1817 VCSEC_NISessionStateRearLeft0 21 "COUNT" 20 "SESSION_INITIATE" 19 "WAIT_FOR_SESSION_INITIATE" 18 "WAIT_FOR_SESSION_STATE_ACTIVE" 17 "UNRECOVERABLE_DEVICE_ERROR" 16 "ERROR_WAIT_FOR_RESET" 15 "WAIT_FOR_RETRY_AFTER_ERROR" 14 "WAIT_FOR_SESSION_DEINIT" 13 "DEINIT_SESSION" 12 "WAIT_FOR_SESSION_STOP" 11 "STOP_SESSION" 10 "RANGING" 9 "WAIT_FOR_RANGING_STARTED_CONFIRMATION" 8 "WAIT_FOR_APPLE_SESSION_INITIATE" 7 "APPLE_SESSION_INITIATE" 6 "WAIT_FOR_APPLE_SHAREABLE_CONFIGURATION_DATA" 5 "SEND_CONFIGURATION_DATA_TO_PHONE" 4 "WAIT_FOR_CONFIGURATION_DATA" 3 "REQUEST_CONFIGURATION_DATA" 2 "WAIT_FOR_CORE_CONFIG_DATA" 1 "APPLY_CORE_CONFIG_DATA" 0 "IDLE" ;
VAL_ 1817 VCSEC_NISessionStateRearRight0 21 "COUNT" 20 "SESSION_INITIATE" 19 "WAIT_FOR_SESSION_INITIATE" 18 "WAIT_FOR_SESSION_STATE_ACTIVE" 17 "UNRECOVERABLE_DEVICE_ERROR" 16 "ERROR_WAIT_FOR_RESET" 15 "WAIT_FOR_RETRY_AFTER_ERROR" 14 "WAIT_FOR_SESSION_DEINIT" 13 "DEINIT_SESSION" 12 "WAIT_FOR_SESSION_STOP" 11 "STOP_SESSION" 10 "RANGING" 9 "WAIT_FOR_RANGING_STARTED_CONFIRMATION" 8 "WAIT_FOR_APPLE_SESSION_INITIATE" 7 "APPLE_SESSION_INITIATE" 6 "WAIT_FOR_APPLE_SHAREABLE_CONFIGURATION_DATA" 5 "SEND_CONFIGURATION_DATA_TO_PHONE" 4 "WAIT_FOR_CONFIGURATION_DATA" 3 "REQUEST_CONFIGURATION_DATA" 2 "WAIT_FOR_CORE_CONFIG_DATA" 1 "APPLY_CORE_CONFIG_DATA" 0 "IDLE" ;
VAL_ 1817 VCSEC_NISessionStateRear0 21 "COUNT" 20 "SESSION_INITIATE" 19 "WAIT_FOR_SESSION_INITIATE" 18 "WAIT_FOR_SESSION_STATE_ACTIVE" 17 "UNRECOVERABLE_DEVICE_ERROR" 16 "ERROR_WAIT_FOR_RESET" 15 "WAIT_FOR_RETRY_AFTER_ERROR" 14 "WAIT_FOR_SESSION_DEINIT" 13 "DEINIT_SESSION" 12 "WAIT_FOR_SESSION_STOP" 11 "STOP_SESSION" 10 "RANGING" 9 "WAIT_FOR_RANGING_STARTED_CONFIRMATION" 8 "WAIT_FOR_APPLE_SESSION_INITIATE" 7 "APPLE_SESSION_INITIATE" 6 "WAIT_FOR_APPLE_SHAREABLE_CONFIGURATION_DATA" 5 "SEND_CONFIGURATION_DATA_TO_PHONE" 4 "WAIT_FOR_CONFIGURATION_DATA" 3 "REQUEST_CONFIGURATION_DATA" 2 "WAIT_FOR_CORE_CONFIG_DATA" 1 "APPLY_CORE_CONFIG_DATA" 0 "IDLE" ;
VAL_ 1817 VCSEC_NISessionStateCenter1 21 "COUNT" 20 "SESSION_INITIATE" 19 "WAIT_FOR_SESSION_INITIATE" 18 "WAIT_FOR_SESSION_STATE_ACTIVE" 17 "UNRECOVERABLE_DEVICE_ERROR" 16 "ERROR_WAIT_FOR_RESET" 15 "WAIT_FOR_RETRY_AFTER_ERROR" 14 "WAIT_FOR_SESSION_DEINIT" 13 "DEINIT_SESSION" 12 "WAIT_FOR_SESSION_STOP" 11 "STOP_SESSION" 10 "RANGING" 9 "WAIT_FOR_RANGING_STARTED_CONFIRMATION" 8 "WAIT_FOR_APPLE_SESSION_INITIATE" 7 "APPLE_SESSION_INITIATE" 6 "WAIT_FOR_APPLE_SHAREABLE_CONFIGURATION_DATA" 5 "SEND_CONFIGURATION_DATA_TO_PHONE" 4 "WAIT_FOR_CONFIGURATION_DATA" 3 "REQUEST_CONFIGURATION_DATA" 2 "WAIT_FOR_CORE_CONFIG_DATA" 1 "APPLY_CORE_CONFIG_DATA" 0 "IDLE" ;
VAL_ 1817 VCSEC_NISessionStateLeft1 21 "COUNT" 20 "SESSION_INITIATE" 19 "WAIT_FOR_SESSION_INITIATE" 18 "WAIT_FOR_SESSION_STATE_ACTIVE" 17 "UNRECOVERABLE_DEVICE_ERROR" 16 "ERROR_WAIT_FOR_RESET" 15 "WAIT_FOR_RETRY_AFTER_ERROR" 14 "WAIT_FOR_SESSION_DEINIT" 13 "DEINIT_SESSION" 12 "WAIT_FOR_SESSION_STOP" 11 "STOP_SESSION" 10 "RANGING" 9 "WAIT_FOR_RANGING_STARTED_CONFIRMATION" 8 "WAIT_FOR_APPLE_SESSION_INITIATE" 7 "APPLE_SESSION_INITIATE" 6 "WAIT_FOR_APPLE_SHAREABLE_CONFIGURATION_DATA" 5 "SEND_CONFIGURATION_DATA_TO_PHONE" 4 "WAIT_FOR_CONFIGURATION_DATA" 3 "REQUEST_CONFIGURATION_DATA" 2 "WAIT_FOR_CORE_CONFIG_DATA" 1 "APPLY_CORE_CONFIG_DATA" 0 "IDLE" ;
VAL_ 1817 VCSEC_NISessionStateRight1 21 "COUNT" 20 "SESSION_INITIATE" 19 "WAIT_FOR_SESSION_INITIATE" 18 "WAIT_FOR_SESSION_STATE_ACTIVE" 17 "UNRECOVERABLE_DEVICE_ERROR" 16 "ERROR_WAIT_FOR_RESET" 15 "WAIT_FOR_RETRY_AFTER_ERROR" 14 "WAIT_FOR_SESSION_DEINIT" 13 "DEINIT_SESSION" 12 "WAIT_FOR_SESSION_STOP" 11 "STOP_SESSION" 10 "RANGING" 9 "WAIT_FOR_RANGING_STARTED_CONFIRMATION" 8 "WAIT_FOR_APPLE_SESSION_INITIATE" 7 "APPLE_SESSION_INITIATE" 6 "WAIT_FOR_APPLE_SHAREABLE_CONFIGURATION_DATA" 5 "SEND_CONFIGURATION_DATA_TO_PHONE" 4 "WAIT_FOR_CONFIGURATION_DATA" 3 "REQUEST_CONFIGURATION_DATA" 2 "WAIT_FOR_CORE_CONFIG_DATA" 1 "APPLY_CORE_CONFIG_DATA" 0 "IDLE" ;
VAL_ 1817 VCSEC_NISessionStateRearLeft1 21 "COUNT" 20 "SESSION_INITIATE" 19 "WAIT_FOR_SESSION_INITIATE" 18 "WAIT_FOR_SESSION_STATE_ACTIVE" 17 "UNRECOVERABLE_DEVICE_ERROR" 16 "ERROR_WAIT_FOR_RESET" 15 "WAIT_FOR_RETRY_AFTER_ERROR" 14 "WAIT_FOR_SESSION_DEINIT" 13 "DEINIT_SESSION" 12 "WAIT_FOR_SESSION_STOP" 11 "STOP_SESSION" 10 "RANGING" 9 "WAIT_FOR_RANGING_STARTED_CONFIRMATION" 8 "WAIT_FOR_APPLE_SESSION_INITIATE" 7 "APPLE_SESSION_INITIATE" 6 "WAIT_FOR_APPLE_SHAREABLE_CONFIGURATION_DATA" 5 "SEND_CONFIGURATION_DATA_TO_PHONE" 4 "WAIT_FOR_CONFIGURATION_DATA" 3 "REQUEST_CONFIGURATION_DATA" 2 "WAIT_FOR_CORE_CONFIG_DATA" 1 "APPLY_CORE_CONFIG_DATA" 0 "IDLE" ;
VAL_ 1817 VCSEC_NISessionStateRearRight1 21 "COUNT" 20 "SESSION_INITIATE" 19 "WAIT_FOR_SESSION_INITIATE" 18 "WAIT_FOR_SESSION_STATE_ACTIVE" 17 "UNRECOVERABLE_DEVICE_ERROR" 16 "ERROR_WAIT_FOR_RESET" 15 "WAIT_FOR_RETRY_AFTER_ERROR" 14 "WAIT_FOR_SESSION_DEINIT" 13 "DEINIT_SESSION" 12 "WAIT_FOR_SESSION_STOP" 11 "STOP_SESSION" 10 "RANGING" 9 "WAIT_FOR_RANGING_STARTED_CONFIRMATION" 8 "WAIT_FOR_APPLE_SESSION_INITIATE" 7 "APPLE_SESSION_INITIATE" 6 "WAIT_FOR_APPLE_SHAREABLE_CONFIGURATION_DATA" 5 "SEND_CONFIGURATION_DATA_TO_PHONE" 4 "WAIT_FOR_CONFIGURATION_DATA" 3 "REQUEST_CONFIGURATION_DATA" 2 "WAIT_FOR_CORE_CONFIG_DATA" 1 "APPLY_CORE_CONFIG_DATA" 0 "IDLE" ;
VAL_ 1817 VCSEC_NISessionStateRear1 21 "COUNT" 20 "SESSION_INITIATE" 19 "WAIT_FOR_SESSION_INITIATE" 18 "WAIT_FOR_SESSION_STATE_ACTIVE" 17 "UNRECOVERABLE_DEVICE_ERROR" 16 "ERROR_WAIT_FOR_RESET" 15 "WAIT_FOR_RETRY_AFTER_ERROR" 14 "WAIT_FOR_SESSION_DEINIT" 13 "DEINIT_SESSION" 12 "WAIT_FOR_SESSION_STOP" 11 "STOP_SESSION" 10 "RANGING" 9 "WAIT_FOR_RANGING_STARTED_CONFIRMATION" 8 "WAIT_FOR_APPLE_SESSION_INITIATE" 7 "APPLE_SESSION_INITIATE" 6 "WAIT_FOR_APPLE_SHAREABLE_CONFIGURATION_DATA" 5 "SEND_CONFIGURATION_DATA_TO_PHONE" 4 "WAIT_FOR_CONFIGURATION_DATA" 3 "REQUEST_CONFIGURATION_DATA" 2 "WAIT_FOR_CORE_CONFIG_DATA" 1 "APPLY_CORE_CONFIG_DATA" 0 "IDLE" ;
VAL_ 1817 VCSEC_NISessionStateCenter2 21 "COUNT" 20 "SESSION_INITIATE" 19 "WAIT_FOR_SESSION_INITIATE" 18 "WAIT_FOR_SESSION_STATE_ACTIVE" 17 "UNRECOVERABLE_DEVICE_ERROR" 16 "ERROR_WAIT_FOR_RESET" 15 "WAIT_FOR_RETRY_AFTER_ERROR" 14 "WAIT_FOR_SESSION_DEINIT" 13 "DEINIT_SESSION" 12 "WAIT_FOR_SESSION_STOP" 11 "STOP_SESSION" 10 "RANGING" 9 "WAIT_FOR_RANGING_STARTED_CONFIRMATION" 8 "WAIT_FOR_APPLE_SESSION_INITIATE" 7 "APPLE_SESSION_INITIATE" 6 "WAIT_FOR_APPLE_SHAREABLE_CONFIGURATION_DATA" 5 "SEND_CONFIGURATION_DATA_TO_PHONE" 4 "WAIT_FOR_CONFIGURATION_DATA" 3 "REQUEST_CONFIGURATION_DATA" 2 "WAIT_FOR_CORE_CONFIG_DATA" 1 "APPLY_CORE_CONFIG_DATA" 0 "IDLE" ;
VAL_ 1817 VCSEC_NISessionStateLeft2 21 "COUNT" 20 "SESSION_INITIATE" 19 "WAIT_FOR_SESSION_INITIATE" 18 "WAIT_FOR_SESSION_STATE_ACTIVE" 17 "UNRECOVERABLE_DEVICE_ERROR" 16 "ERROR_WAIT_FOR_RESET" 15 "WAIT_FOR_RETRY_AFTER_ERROR" 14 "WAIT_FOR_SESSION_DEINIT" 13 "DEINIT_SESSION" 12 "WAIT_FOR_SESSION_STOP" 11 "STOP_SESSION" 10 "RANGING" 9 "WAIT_FOR_RANGING_STARTED_CONFIRMATION" 8 "WAIT_FOR_APPLE_SESSION_INITIATE" 7 "APPLE_SESSION_INITIATE" 6 "WAIT_FOR_APPLE_SHAREABLE_CONFIGURATION_DATA" 5 "SEND_CONFIGURATION_DATA_TO_PHONE" 4 "WAIT_FOR_CONFIGURATION_DATA" 3 "REQUEST_CONFIGURATION_DATA" 2 "WAIT_FOR_CORE_CONFIG_DATA" 1 "APPLY_CORE_CONFIG_DATA" 0 "IDLE" ;
VAL_ 1817 VCSEC_NISessionStateRight2 21 "COUNT" 20 "SESSION_INITIATE" 19 "WAIT_FOR_SESSION_INITIATE" 18 "WAIT_FOR_SESSION_STATE_ACTIVE" 17 "UNRECOVERABLE_DEVICE_ERROR" 16 "ERROR_WAIT_FOR_RESET" 15 "WAIT_FOR_RETRY_AFTER_ERROR" 14 "WAIT_FOR_SESSION_DEINIT" 13 "DEINIT_SESSION" 12 "WAIT_FOR_SESSION_STOP" 11 "STOP_SESSION" 10 "RANGING" 9 "WAIT_FOR_RANGING_STARTED_CONFIRMATION" 8 "WAIT_FOR_APPLE_SESSION_INITIATE" 7 "APPLE_SESSION_INITIATE" 6 "WAIT_FOR_APPLE_SHAREABLE_CONFIGURATION_DATA" 5 "SEND_CONFIGURATION_DATA_TO_PHONE" 4 "WAIT_FOR_CONFIGURATION_DATA" 3 "REQUEST_CONFIGURATION_DATA" 2 "WAIT_FOR_CORE_CONFIG_DATA" 1 "APPLY_CORE_CONFIG_DATA" 0 "IDLE" ;
VAL_ 1817 VCSEC_NISessionStateRearLeft2 21 "COUNT" 20 "SESSION_INITIATE" 19 "WAIT_FOR_SESSION_INITIATE" 18 "WAIT_FOR_SESSION_STATE_ACTIVE" 17 "UNRECOVERABLE_DEVICE_ERROR" 16 "ERROR_WAIT_FOR_RESET" 15 "WAIT_FOR_RETRY_AFTER_ERROR" 14 "WAIT_FOR_SESSION_DEINIT" 13 "DEINIT_SESSION" 12 "WAIT_FOR_SESSION_STOP" 11 "STOP_SESSION" 10 "RANGING" 9 "WAIT_FOR_RANGING_STARTED_CONFIRMATION" 8 "WAIT_FOR_APPLE_SESSION_INITIATE" 7 "APPLE_SESSION_INITIATE" 6 "WAIT_FOR_APPLE_SHAREABLE_CONFIGURATION_DATA" 5 "SEND_CONFIGURATION_DATA_TO_PHONE" 4 "WAIT_FOR_CONFIGURATION_DATA" 3 "REQUEST_CONFIGURATION_DATA" 2 "WAIT_FOR_CORE_CONFIG_DATA" 1 "APPLY_CORE_CONFIG_DATA" 0 "IDLE" ;
VAL_ 1817 VCSEC_NISessionStateRearRight2 21 "COUNT" 20 "SESSION_INITIATE" 19 "WAIT_FOR_SESSION_INITIATE" 18 "WAIT_FOR_SESSION_STATE_ACTIVE" 17 "UNRECOVERABLE_DEVICE_ERROR" 16 "ERROR_WAIT_FOR_RESET" 15 "WAIT_FOR_RETRY_AFTER_ERROR" 14 "WAIT_FOR_SESSION_DEINIT" 13 "DEINIT_SESSION" 12 "WAIT_FOR_SESSION_STOP" 11 "STOP_SESSION" 10 "RANGING" 9 "WAIT_FOR_RANGING_STARTED_CONFIRMATION" 8 "WAIT_FOR_APPLE_SESSION_INITIATE" 7 "APPLE_SESSION_INITIATE" 6 "WAIT_FOR_APPLE_SHAREABLE_CONFIGURATION_DATA" 5 "SEND_CONFIGURATION_DATA_TO_PHONE" 4 "WAIT_FOR_CONFIGURATION_DATA" 3 "REQUEST_CONFIGURATION_DATA" 2 "WAIT_FOR_CORE_CONFIG_DATA" 1 "APPLY_CORE_CONFIG_DATA" 0 "IDLE" ;
VAL_ 1817 VCSEC_NISessionStateRear2 21 "COUNT" 20 "SESSION_INITIATE" 19 "WAIT_FOR_SESSION_INITIATE" 18 "WAIT_FOR_SESSION_STATE_ACTIVE" 17 "UNRECOVERABLE_DEVICE_ERROR" 16 "ERROR_WAIT_FOR_RESET" 15 "WAIT_FOR_RETRY_AFTER_ERROR" 14 "WAIT_FOR_SESSION_DEINIT" 13 "DEINIT_SESSION" 12 "WAIT_FOR_SESSION_STOP" 11 "STOP_SESSION" 10 "RANGING" 9 "WAIT_FOR_RANGING_STARTED_CONFIRMATION" 8 "WAIT_FOR_APPLE_SESSION_INITIATE" 7 "APPLE_SESSION_INITIATE" 6 "WAIT_FOR_APPLE_SHAREABLE_CONFIGURATION_DATA" 5 "SEND_CONFIGURATION_DATA_TO_PHONE" 4 "WAIT_FOR_CONFIGURATION_DATA" 3 "REQUEST_CONFIGURATION_DATA" 2 "WAIT_FOR_CORE_CONFIG_DATA" 1 "APPLY_CORE_CONFIG_DATA" 0 "IDLE" ;
VAL_ 1817 VCSEC_NISessionStateLeft3 21 "COUNT" 20 "SESSION_INITIATE" 19 "WAIT_FOR_SESSION_INITIATE" 18 "WAIT_FOR_SESSION_STATE_ACTIVE" 17 "UNRECOVERABLE_DEVICE_ERROR" 16 "ERROR_WAIT_FOR_RESET" 15 "WAIT_FOR_RETRY_AFTER_ERROR" 14 "WAIT_FOR_SESSION_DEINIT" 13 "DEINIT_SESSION" 12 "WAIT_FOR_SESSION_STOP" 11 "STOP_SESSION" 10 "RANGING" 9 "WAIT_FOR_RANGING_STARTED_CONFIRMATION" 8 "WAIT_FOR_APPLE_SESSION_INITIATE" 7 "APPLE_SESSION_INITIATE" 6 "WAIT_FOR_APPLE_SHAREABLE_CONFIGURATION_DATA" 5 "SEND_CONFIGURATION_DATA_TO_PHONE" 4 "WAIT_FOR_CONFIGURATION_DATA" 3 "REQUEST_CONFIGURATION_DATA" 2 "WAIT_FOR_CORE_CONFIG_DATA" 1 "APPLY_CORE_CONFIG_DATA" 0 "IDLE" ;
VAL_ 1817 VCSEC_NISessionStateRight3 21 "COUNT" 20 "SESSION_INITIATE" 19 "WAIT_FOR_SESSION_INITIATE" 18 "WAIT_FOR_SESSION_STATE_ACTIVE" 17 "UNRECOVERABLE_DEVICE_ERROR" 16 "ERROR_WAIT_FOR_RESET" 15 "WAIT_FOR_RETRY_AFTER_ERROR" 14 "WAIT_FOR_SESSION_DEINIT" 13 "DEINIT_SESSION" 12 "WAIT_FOR_SESSION_STOP" 11 "STOP_SESSION" 10 "RANGING" 9 "WAIT_FOR_RANGING_STARTED_CONFIRMATION" 8 "WAIT_FOR_APPLE_SESSION_INITIATE" 7 "APPLE_SESSION_INITIATE" 6 "WAIT_FOR_APPLE_SHAREABLE_CONFIGURATION_DATA" 5 "SEND_CONFIGURATION_DATA_TO_PHONE" 4 "WAIT_FOR_CONFIGURATION_DATA" 3 "REQUEST_CONFIGURATION_DATA" 2 "WAIT_FOR_CORE_CONFIG_DATA" 1 "APPLY_CORE_CONFIG_DATA" 0 "IDLE" ;
VAL_ 1817 VCSEC_NISessionStateRearRight3 21 "COUNT" 20 "SESSION_INITIATE" 19 "WAIT_FOR_SESSION_INITIATE" 18 "WAIT_FOR_SESSION_STATE_ACTIVE" 17 "UNRECOVERABLE_DEVICE_ERROR" 16 "ERROR_WAIT_FOR_RESET" 15 "WAIT_FOR_RETRY_AFTER_ERROR" 14 "WAIT_FOR_SESSION_DEINIT" 13 "DEINIT_SESSION" 12 "WAIT_FOR_SESSION_STOP" 11 "STOP_SESSION" 10 "RANGING" 9 "WAIT_FOR_RANGING_STARTED_CONFIRMATION" 8 "WAIT_FOR_APPLE_SESSION_INITIATE" 7 "APPLE_SESSION_INITIATE" 6 "WAIT_FOR_APPLE_SHAREABLE_CONFIGURATION_DATA" 5 "SEND_CONFIGURATION_DATA_TO_PHONE" 4 "WAIT_FOR_CONFIGURATION_DATA" 3 "REQUEST_CONFIGURATION_DATA" 2 "WAIT_FOR_CORE_CONFIG_DATA" 1 "APPLY_CORE_CONFIG_DATA" 0 "IDLE" ;
VAL_ 1817 VCSEC_NISessionStateRearLeft3 21 "COUNT" 20 "SESSION_INITIATE" 19 "WAIT_FOR_SESSION_INITIATE" 18 "WAIT_FOR_SESSION_STATE_ACTIVE" 17 "UNRECOVERABLE_DEVICE_ERROR" 16 "ERROR_WAIT_FOR_RESET" 15 "WAIT_FOR_RETRY_AFTER_ERROR" 14 "WAIT_FOR_SESSION_DEINIT" 13 "DEINIT_SESSION" 12 "WAIT_FOR_SESSION_STOP" 11 "STOP_SESSION" 10 "RANGING" 9 "WAIT_FOR_RANGING_STARTED_CONFIRMATION" 8 "WAIT_FOR_APPLE_SESSION_INITIATE" 7 "APPLE_SESSION_INITIATE" 6 "WAIT_FOR_APPLE_SHAREABLE_CONFIGURATION_DATA" 5 "SEND_CONFIGURATION_DATA_TO_PHONE" 4 "WAIT_FOR_CONFIGURATION_DATA" 3 "REQUEST_CONFIGURATION_DATA" 2 "WAIT_FOR_CORE_CONFIG_DATA" 1 "APPLY_CORE_CONFIG_DATA" 0 "IDLE" ;
VAL_ 1817 VCSEC_NISessionStateCenter3 21 "COUNT" 20 "SESSION_INITIATE" 19 "WAIT_FOR_SESSION_INITIATE" 18 "WAIT_FOR_SESSION_STATE_ACTIVE" 17 "UNRECOVERABLE_DEVICE_ERROR" 16 "ERROR_WAIT_FOR_RESET" 15 "WAIT_FOR_RETRY_AFTER_ERROR" 14 "WAIT_FOR_SESSION_DEINIT" 13 "DEINIT_SESSION" 12 "WAIT_FOR_SESSION_STOP" 11 "STOP_SESSION" 10 "RANGING" 9 "WAIT_FOR_RANGING_STARTED_CONFIRMATION" 8 "WAIT_FOR_APPLE_SESSION_INITIATE" 7 "APPLE_SESSION_INITIATE" 6 "WAIT_FOR_APPLE_SHAREABLE_CONFIGURATION_DATA" 5 "SEND_CONFIGURATION_DATA_TO_PHONE" 4 "WAIT_FOR_CONFIGURATION_DATA" 3 "REQUEST_CONFIGURATION_DATA" 2 "WAIT_FOR_CORE_CONFIG_DATA" 1 "APPLY_CORE_CONFIG_DATA" 0 "IDLE" ;
VAL_ 793 VCSEC_infoBuildType 4 "INFO_MFG_BUILD" 3 "INFO_TRACEABLE_CI_BUILD" 2 "INFO_LOCAL_BUILD" 1 "INFO_PLATFORM_BUILD" 0 "INFO_UNKNOWN_BUILD" ;
